VERSION ""

NS_ :

BS_:

BU_: ETH

BO_ 1359 SCCM_alertMatrix: 8 Vector__XXX
 SG_ SCCM_matrixIndex M : 0|4@1+ (1,0) [0|0] "" Vector__XXX
 SG_ SCCM_a001_CANBusOff m0 : 4|1@1+ (1,0) [0|0] "" Vector__XXX
 SG_ SCCM_a002_CANTOut m0 : 5|1@1+ (1,0) [0|0] "" Vector__XXX
 SG_ SCCM_a003_highBeamOpen m0 : 6|1@1+ (1,0) [0|0] "" Vector__XXX
 SG_ SCCM_a004_highBeamShortToGND m0 : 7|1@1+ (1,0) [0|0] "" Vector__XXX
 SG_ SCCM_a005_tipWipeOpen m0 : 8|1@1+ (1,0) [0|0] "" Vector__XXX
 SG_ SCCM_a006_tipWipeShortToGND m0 : 9|1@1+ (1,0) [0|0] "" Vector__XXX
 SG_ SCCM_a007_turnIndComInfo m0 : 10|1@1+ (1,0) [0|0] "" Vector__XXX
 SG_ SCCM_a008_turnIndInvalidTrans m0 : 11|1@1+ (1,0) [0|0] "" Vector__XXX
 SG_ SCCM_a009_turnIndOpen m0 : 12|1@1+ (1,0) [0|0] "" Vector__XXX
 SG_ SCCM_a010_turnIndShortToGnd m0 : 13|1@1+ (1,0) [0|0] "" Vector__XXX
 SG_ SCCM_a011_turnIndHWErr m0 : 14|1@1+ (1,0) [0|0] "" Vector__XXX
 SG_ SCCM_a012_turnGenErr m0 : 15|1@1+ (1,0) [0|0] "" Vector__XXX
 SG_ SCCM_a013_voltageHigh m0 : 16|1@1+ (1,0) [0|0] "" Vector__XXX
 SG_ SCCM_a014_voltageLow m0 : 17|1@1+ (1,0) [0|0] "" Vector__XXX
 SG_ SCCM_a015_softwareError m0 : 18|1@1+ (1,0) [0|0] "" Vector__XXX
 SG_ SCCM_a016_hardwareError m0 : 19|1@1+ (1,0) [0|0] "" Vector__XXX
 SG_ SCCM_a017_memoryError m0 : 20|1@1+ (1,0) [0|0] "" Vector__XXX
 SG_ SCCM_a018_angleSpeedOutOfRange m0 : 21|1@1+ (1,0) [0|0] "" Vector__XXX
 SG_ SCCM_a019_angleOutOfRange m0 : 22|1@1+ (1,0) [0|0] "" Vector__XXX
 SG_ SCCM_a020_angleInternalError m0 : 23|1@1+ (1,0) [0|0] "" Vector__XXX
 SG_ SCCM_a021_gearStalkSignalInvalid m0 : 24|1@1+ (1,0) [0|0] "" Vector__XXX
 SG_ SCCM_a022_gearStalkOpenCircuit m0 : 25|1@1+ (1,0) [0|0] "" Vector__XXX
 SG_ SCCM_a023_gearStalkShortCircuit m0 : 26|1@1+ (1,0) [0|0] "" Vector__XXX
 SG_ SCCM_a024_gearStalkGenErr m0 : 27|1@1+ (1,0) [0|0] "" Vector__XXX
 SG_ SCCM_a025_runTimeError m0 : 28|1@1+ (1,0) [0|0] "" Vector__XXX
 SG_ SCCM_a026_parkButtonInvalidSignal m0 : 29|1@1+ (1,0) [0|0] "" Vector__XXX
 SG_ SCCM_a027_parkButtonOpenCircuit m0 : 30|1@1+ (1,0) [0|0] "" Vector__XXX
 SG_ SCCM_a028_parkButtonShortToGround m0 : 31|1@1+ (1,0) [0|0] "" Vector__XXX
 SG_ SCCM_a029_parkButtonMalfunction m0 : 32|1@1+ (1,0) [0|0] "" Vector__XXX

BO_ 1360 VCRIGHT_alertLog: 8 Vector__XXX
 SG_ VCRIGHT_alertID M : 0|10@1+ (1,0) [0|0] "" Vector__XXX
 SG_ VCRIGHT_alertState : 15|1@1+ (1,0) [0|0] "" Vector__XXX
 SG_ VCRIGHT_a000_alertDataW0 m0 : 16|16@1+ (1,0) [0|0] "" Vector__XXX
 SG_ VCRIGHT_a001_InternalWatchdog m1 : 16|1@1+ (1,0) [0|0] "" Vector__XXX
 SG_ VCRIGHT_a002_CPUUndervoltage m2 : 16|1@1+ (1,0) [0|0] "" Vector__XXX
 SG_ VCRIGHT_a003_AssertID m3 : 16|16@1+ (1,0) [0|0] "" Vector__XXX
 SG_ VCRIGHT_a005_busID0 m5 : 16|4@1+ (1,0) [0|0] "" Vector__XXX
 SG_ VCRIGHT_a006_busID m6 : 16|4@1+ (1,0) [0|0] "" Vector__XXX
 SG_ VCRIGHT_a010_UnderVoltageDetected m10 : 16|1@1+ (1,0) [0|0] "" Vector__XXX
 SG_ VCRIGHT_a012_ClockError m12 : 16|1@1+ (1,0) [0|0] "" Vector__XXX
 SG_ VCRIGHT_a013_LogQueueFull m13 : 16|1@1+ (1,0) [0|0] "" Vector__XXX
 SG_ VCRIGHT_a015_NVMMMemOverflow m15 : 16|1@1+ (1,0) [0|0] "" Vector__XXX
 SG_ VCRIGHT_a016_NVMMRecordID m16 : 16|16@1+ (1,0) [0|0] "" Vector__XXX
 SG_ VCRIGHT_a017_NVMMLifetimeEraseCycles m17 : 16|32@1+ (1,0) [0|0] "" Vector__XXX
 SG_ VCRIGHT_a021_Task1msLate m21 : 16|1@1+ (1,0) [0|0] "" Vector__XXX
 SG_ VCRIGHT_a022_TaskInitErrorCount m22 : 16|8@1+ (1,0) [0|0] "" Vector__XXX
 SG_ VCRIGHT_a030_logId m30 : 16|4@1+ (1,0) [0|0] "" Vector__XXX
 SG_ VCRIGHT_a031_uds_bytes_0 m31 : 16|8@1+ (1,0) [0|0] "" Vector__XXX
 SG_ VCRIGHT_a041_CPULoadTotal m41 : 16|8@1+ (1,0) [0|0] "" Vector__XXX
 SG_ VCRIGHT_a042_Usage1msTask m42 : 16|8@1+ (1,0) [0|0] "" Vector__XXX
 SG_ VCRIGHT_a043_CallTrace0 m43 : 16|24@1+ (1,0) [0|0] "" Vector__XXX
 SG_ VCRIGHT_a044_CallTrace0 m44 : 16|24@1+ (1,0) [0|0] "" Vector__XXX
 SG_ VCRIGHT_a045_CallTrace0 m45 : 16|24@1+ (1,0) [0|0] "" Vector__XXX
 SG_ VCRIGHT_a046_CallTrace0 m46 : 16|24@1+ (1,0) [0|0] "" Vector__XXX
 SG_ VCRIGHT_a057_VEH_cpControl m57 : 16|1@1+ (1,0) [0|0] "" Vector__XXX
 SG_ VCRIGHT_a058_voltageDrop m58 : 16|12@1+ (0.005443676098,0) [0|0] "" Vector__XXX
 SG_ VCRIGHT_a059_voltageDrop m59 : 16|12@1+ (0.005443676098,0) [0|0] "" Vector__XXX
 SG_ VCRIGHT_a060_lockoutDisabled m60 : 16|1@1+ (1,0) [0|0] "" Vector__XXX
 SG_ VCRIGHT_a063_switchChannel m63 : 16|8@1+ (1,0) [0|0] "" Vector__XXX
 SG_ VCRIGHT_a064_busBitField m64 : 16|8@1+ (1,0) [0|0] "" Vector__XXX
 SG_ VCRIGHT_a065_bank m65 : 16|2@1+ (1,0) [0|0] "" Vector__XXX
 SG_ VCRIGHT_a066_bank m66 : 16|2@1+ (1,0) [0|0] "" Vector__XXX
 SG_ VCRIGHT_a082_RIPC_epbPrivateState m82 : 16|1@1+ (1,0) [0|0] "" Vector__XXX
 SG_ VCRIGHT_a083_LIPC_epbPrivateState m83 : 16|1@1+ (1,0) [0|0] "" Vector__XXX
 SG_ VCRIGHT_a084_CH_StatusC m84 : 16|1@1+ (1,0) [0|0] "" Vector__XXX
 SG_ VCRIGHT_a085_PARTY_buttonStatus m85 : 16|1@1+ (1,0) [0|0] "" Vector__XXX
 SG_ VCRIGHT_a086_VEH_LVBMS_statusHigh m86 : 16|1@1+ (1,0) [0|0] "" Vector__XXX
 SG_ VCRIGHT_a087_VEH_temperature m87 : 16|1@1+ (1,0) [0|0] "" Vector__XXX
 SG_ VCRIGHT_a088_VEH_temperature m88 : 16|1@1+ (1,0) [0|0] "" Vector__XXX
 SG_ VCRIGHT_a089_PARTY_party1 m89 : 16|1@1+ (1,0) [0|0] "" Vector__XXX
 SG_ VCRIGHT_a090_VEH_chNm m90 : 16|1@1+ (1,0) [0|0] "" Vector__XXX
 SG_ VCRIGHT_a091_VEH_faultsAndExtras m91 : 16|1@1+ (1,0) [0|0] "" Vector__XXX
 SG_ VCRIGHT_a092_VEH_restraintStatus m92 : 16|1@1+ (1,0) [0|0] "" Vector__XXX
 SG_ VCRIGHT_a093_VEH_restraintStatus m93 : 16|1@1+ (1,0) [0|0] "" Vector__XXX
 SG_ VCRIGHT_a094_VEH_sysStatus m94 : 16|1@1+ (1,0) [0|0] "" Vector__XXX
 SG_ VCRIGHT_a095_PT_ptNm m95 : 16|1@1+ (1,0) [0|0] "" Vector__XXX
 SG_ VCRIGHT_a096_VEH_status m96 : 16|1@1+ (1,0) [0|0] "" Vector__XXX
 SG_ VCRIGHT_a097_VEH_HVStatus m97 : 16|1@1+ (1,0) [0|0] "" Vector__XXX
 SG_ VCRIGHT_a098_CH_torque m98 : 16|1@1+ (1,0) [0|0] "" Vector__XXX
 SG_ VCRIGHT_a099_VEH_oocStatus m99 : 16|1@1+ (1,0) [0|0] "" Vector__XXX
 SG_ VCRIGHT_a100_VEH m100 : 16|1@1+ (1,0) [0|0] "" Vector__XXX
 SG_ VCRIGHT_a101_VEH_state m101 : 16|1@1+ (1,0) [0|0] "" Vector__XXX
 SG_ VCRIGHT_a102_VEH_faultsAndExtras m102 : 16|1@1+ (1,0) [0|0] "" Vector__XXX
 SG_ VCRIGHT_a103_VEH_hvsNm m103 : 16|1@1+ (1,0) [0|0] "" Vector__XXX
 SG_ VCRIGHT_a104_PARTY_redundantBrakingControl m104 : 16|1@1+ (1,0) [0|0] "" Vector__XXX
 SG_ VCRIGHT_a105_VEH_states m105 : 16|1@1+ (1,0) [0|0] "" Vector__XXX
 SG_ VCRIGHT_a106_VEH_dcdcStatus m106 : 16|1@1+ (1,0) [0|0] "" Vector__XXX
 SG_ VCRIGHT_a107_VEH_hvsNm m107 : 16|1@1+ (1,0) [0|0] "" Vector__XXX
 SG_ VCRIGHT_a108_VEH_hvStatus m108 : 16|1@1+ (1,0) [0|0] "" Vector__XXX
 SG_ VCRIGHT_a109_PARTY_status m109 : 16|1@1+ (1,0) [0|0] "" Vector__XXX
 SG_ VCRIGHT_a110_VEH_carState m110 : 16|1@1+ (1,0) [0|0] "" Vector__XXX
 SG_ VCRIGHT_a111_VEH_internalStatus m111 : 16|1@1+ (1,0) [0|0] "" Vector__XXX
 SG_ VCRIGHT_a112_VEH_internalStatus m112 : 16|1@1+ (1,0) [0|0] "" Vector__XXX
 SG_ VCRIGHT_a113_VEH_ethNm m113 : 16|1@1+ (1,0) [0|0] "" Vector__XXX
 SG_ VCRIGHT_a114_PARTY_status m114 : 16|1@1+ (1,0) [0|0] "" Vector__XXX
 SG_ VCRIGHT_a115_VEH_vehNm m115 : 16|1@1+ (1,0) [0|0] "" Vector__XXX
 SG_ VCRIGHT_a116_PARTY_epbmStatus m116 : 16|1@1+ (1,0) [0|0] "" Vector__XXX
 SG_ VCRIGHT_a117_BDY_epbmStatus m117 : 16|1@1+ (1,0) [0|0] "" Vector__XXX
 SG_ VCRIGHT_a118_VEH_vehNm m118 : 16|1@1+ (1,0) [0|0] "" Vector__XXX
 SG_ VCRIGHT_a119_VEH_steerAngle m119 : 16|1@1+ (1,0) [0|0] "" Vector__XXX
 SG_ VCRIGHT_a120_PARTY_chassisCntl m120 : 16|1@1+ (1,0) [0|0] "" Vector__XXX
 SG_ VCRIGHT_a122_VEH_status m122 : 16|1@1+ (1,0) [0|0] "" Vector__XXX
 SG_ VCRIGHT_a126_timeSinceInitMs m126 : 16|16@1+ (10,0) [0|0] "" Vector__XXX
 SG_ VCRIGHT_a127_timeSinceInitMs m127 : 16|16@1+ (10,0) [0|0] "" Vector__XXX
 SG_ VCRIGHT_a128_timeSinceInitMs m128 : 16|16@1+ (10,0) [0|0] "" Vector__XXX
 SG_ VCRIGHT_a136_hvacIntakeStall m136 : 16|1@1+ (1,0) [0|0] "" Vector__XXX
 SG_ VCRIGHT_a137_hvacLHBleedStall m137 : 16|1@1+ (1,0) [0|0] "" Vector__XXX
 SG_ VCRIGHT_a138_hvacRHBleedStall m138 : 16|1@1+ (1,0) [0|0] "" Vector__XXX
 SG_ VCRIGHT_a139_hvacLHVaneStall m139 : 16|1@1+ (1,0) [0|0] "" Vector__XXX
 SG_ VCRIGHT_a140_hvacRHVaneStall m140 : 16|1@1+ (1,0) [0|0] "" Vector__XXX
 SG_ VCRIGHT_a141_hvacUpperModeStall m141 : 16|1@1+ (1,0) [0|0] "" Vector__XXX
 SG_ VCRIGHT_a142_hvacLowerModeStall m142 : 16|1@1+ (1,0) [0|0] "" Vector__XXX
 SG_ VCRIGHT_a144_snsShortCircuit m144 : 16|1@1+ (1,0) [0|0] "" Vector__XXX
 SG_ VCRIGHT_a145_snsShortCircuit m145 : 16|1@1+ (1,0) [0|0] "" Vector__XXX
 SG_ VCRIGHT_a146_snsShortCircuit m146 : 16|1@1+ (1,0) [0|0] "" Vector__XXX
 SG_ VCRIGHT_a147_snsShortCircuit m147 : 16|1@1+ (1,0) [0|0] "" Vector__XXX
 SG_ VCRIGHT_a148_snsShortCircuit m148 : 16|1@1+ (1,0) [0|0] "" Vector__XXX
 SG_ VCRIGHT_a149_snsShortCircuit m149 : 16|1@1+ (1,0) [0|0] "" Vector__XXX
 SG_ VCRIGHT_a150_windowPosition m150 : 16|9@1- (1.4313725490196079,197.52941176470588) [0|0] "" Vector__XXX
 SG_ VCRIGHT_a151_windowPosition m151 : 16|9@1- (1.4313725490196079,197.52941176470588) [0|0] "" Vector__XXX
 SG_ VCRIGHT_a152_zeroed m152 : 16|1@1+ (1,0) [0|0] "" Vector__XXX
 SG_ VCRIGHT_a153_zeroed m153 : 16|1@1+ (1,0) [0|0] "" Vector__XXX
 SG_ VCRIGHT_a154_windowThermalMode m154 : 16|2@1+ (1,0) [0|0] "" Vector__XXX
 SG_ VCRIGHT_a155_windowThermalMode m155 : 16|2@1+ (1,0) [0|0] "" Vector__XXX
 SG_ VCRIGHT_a156_windowThermalMode m156 : 16|2@1+ (1,0) [0|0] "" Vector__XXX
 SG_ VCRIGHT_a157_windowThermalMode m157 : 16|2@1+ (1,0) [0|0] "" Vector__XXX
 SG_ VCRIGHT_a164_testPassed m164 : 16|1@1+ (1,0) [0|0] "" Vector__XXX
 SG_ VCRIGHT_a165_testPassed m165 : 16|1@1+ (1,0) [0|0] "" Vector__XXX
 SG_ VCRIGHT_a166_windowFront m166 : 16|1@1+ (1,0) [0|0] "" Vector__XXX
 SG_ VCRIGHT_a167_windowPosition m167 : 16|8@1+ (10,0) [0|0] "" Vector__XXX
 SG_ VCRIGHT_a168_windowPosition m168 : 16|8@1+ (10,0) [0|0] "" Vector__XXX
 SG_ VCRIGHT_a169_currentPeakCurrent m169 : 16|6@1+ (0.1,0) [0|0] "" Vector__XXX
 SG_ VCRIGHT_a170_currentPeakCurrent m170 : 16|6@1+ (0.1,0) [0|0] "" Vector__XXX
 SG_ VCRIGHT_a173_btnSwPackDownLF m173 : 16|1@1+ (1,0) [0|0] "" Vector__XXX
 SG_ VCRIGHT_a175_positionAtPinch m175 : 16|11@1- (0.25,230) [0|0] "" Vector__XXX
 SG_ VCRIGHT_a176_positionAtPinch m176 : 16|11@1- (0.25,230) [0|0] "" Vector__XXX
 SG_ VCRIGHT_a180_intButtonPressed m180 : 16|1@1+ (1,0) [0|0] "" Vector__XXX
 SG_ VCRIGHT_a181_intButtonPressed m181 : 16|1@1+ (1,0) [0|0] "" Vector__XXX
 SG_ VCRIGHT_a183_testPassed m183 : 16|1@1+ (1,0) [0|0] "" Vector__XXX
 SG_ VCRIGHT_a184_voltage m184 : 16|7@1+ (0.15,0) [0|0] "" Vector__XXX
 SG_ VCRIGHT_a185_summonFaultReason m185 : 16|5@1+ (1,0) [0|0] "" Vector__XXX
 SG_ VCRIGHT_a186_voltage m186 : 16|7@1+ (0.15,0) [0|0] "" Vector__XXX
 SG_ VCRIGHT_a187_voltage m187 : 16|7@1+ (0.15,0) [0|0] "" Vector__XXX
 SG_ VCRIGHT_a188_voltage m188 : 16|7@1+ (0.15,0) [0|0] "" Vector__XXX
 SG_ VCRIGHT_a189_voltage m189 : 16|7@1+ (0.15,0) [0|0] "" Vector__XXX
 SG_ VCRIGHT_a190_eFuseTripCount m190 : 16|8@1+ (1,0) [0|0] "" Vector__XXX
 SG_ VCRIGHT_a193_amplifierCurrent m193 : 16|10@1+ (0.1,0) [0|0] "" Vector__XXX
 SG_ VCRIGHT_a194_cntctrPwrCurrent m194 : 16|10@1+ (0.1,0) [0|0] "" Vector__XXX
 SG_ VCRIGHT_a195_hvcCurrent m195 : 16|10@1+ (0.1,0) [0|0] "" Vector__XXX
 SG_ VCRIGHT_a196_outputState m196 : 16|1@1+ (1,0) [0|0] "" Vector__XXX
 SG_ VCRIGHT_a197_outputState m197 : 16|1@1+ (1,0) [0|0] "" Vector__XXX
 SG_ VCRIGHT_a198_outputState m198 : 16|1@1+ (1,0) [0|0] "" Vector__XXX
 SG_ VCRIGHT_a199_outputState m199 : 16|1@1+ (1,0) [0|0] "" Vector__XXX
 SG_ VCRIGHT_a200_voltage m200 : 16|7@1+ (0.15,0) [0|0] "" Vector__XXX
 SG_ VCRIGHT_a201_voltage m201 : 16|7@1+ (0.15,0) [0|0] "" Vector__XXX
 SG_ VCRIGHT_a202_unknownAllowed m202 : 16|1@1+ (1,0) [0|0] "" Vector__XXX
 SG_ VCRIGHT_a203_unknownAllowed m203 : 16|1@1+ (1,0) [0|0] "" Vector__XXX
 SG_ VCRIGHT_a204_unknownAllowed m204 : 16|1@1+ (1,0) [0|0] "" Vector__XXX
 SG_ VCRIGHT_a205_unknownAllowed m205 : 16|1@1+ (1,0) [0|0] "" Vector__XXX
 SG_ VCRIGHT_a206_unknownAllowed m206 : 16|1@1+ (1,0) [0|0] "" Vector__XXX
 SG_ VCRIGHT_a207_unknownAllowed m207 : 16|1@1+ (1,0) [0|0] "" Vector__XXX
 SG_ VCRIGHT_a208_unknownAllowed m208 : 16|1@1+ (1,0) [0|0] "" Vector__XXX
 SG_ VCRIGHT_a209_unknownAllowed m209 : 16|1@1+ (1,0) [0|0] "" Vector__XXX
 SG_ VCRIGHT_a210_unknownAllowed m210 : 16|1@1+ (1,0) [0|0] "" Vector__XXX
 SG_ VCRIGHT_a211_unknownAllowed m211 : 16|1@1+ (1,0) [0|0] "" Vector__XXX
 SG_ VCRIGHT_a212_unknownAllowed m212 : 16|1@1+ (1,0) [0|0] "" Vector__XXX
 SG_ VCRIGHT_a213_unknownAllowed m213 : 16|1@1+ (1,0) [0|0] "" Vector__XXX
 SG_ VCRIGHT_a214_unknownAllowed m214 : 16|1@1+ (1,0) [0|0] "" Vector__XXX
 SG_ VCRIGHT_a215_desyncCount m215 : 16|8@1+ (1,0) [0|0] "" Vector__XXX
 SG_ VCRIGHT_a216_noData m216 : 16|1@1+ (1,0) [0|0] "" Vector__XXX
 SG_ VCRIGHT_a217_byte4 m217 : 16|8@1+ (1,0) [0|0] "" Vector__XXX
 SG_ VCRIGHT_a218_motorChannels m218 : 16|16@1+ (1,0) [0|0] "" Vector__XXX
 SG_ VCRIGHT_a219_motorChannels m219 : 16|16@1+ (1,0) [0|0] "" Vector__XXX
 SG_ VCRIGHT_a224_seatMotorCalibrated m224 : 16|1@1+ (1,0) [0|0] "" Vector__XXX
 SG_ VCRIGHT_a225_seatMotorCalibrated m225 : 16|1@1+ (1,0) [0|0] "" Vector__XXX
 SG_ VCRIGHT_a226_seatMotorCalibrated m226 : 16|1@1+ (1,0) [0|0] "" Vector__XXX
 SG_ VCRIGHT_a227_seatMotorCalibrated m227 : 16|1@1+ (1,0) [0|0] "" Vector__XXX
 SG_ VCRIGHT_a228_seatMotorCalibrated m228 : 16|1@1+ (1,0) [0|0] "" Vector__XXX
 SG_ VCRIGHT_a229_seatMotorCalibrated m229 : 16|1@1+ (1,0) [0|0] "" Vector__XXX
 SG_ VCRIGHT_a230_seatMotorCalibrated m230 : 16|1@1+ (1,0) [0|0] "" Vector__XXX
 SG_ VCRIGHT_a231_seatMotorCalibrated m231 : 16|1@1+ (1,0) [0|0] "" Vector__XXX
 SG_ VCRIGHT_a232_seatMotorCurrent m232 : 16|12@1- (0.01,0) [0|0] "" Vector__XXX
 SG_ VCRIGHT_a233_seatMotorCurrent m233 : 16|12@1- (0.01,0) [0|0] "" Vector__XXX
 SG_ VCRIGHT_a234_seatMotorCurrent m234 : 16|12@1- (0.01,0) [0|0] "" Vector__XXX
 SG_ VCRIGHT_a235_seatMotorCurrent m235 : 16|12@1- (0.01,0) [0|0] "" Vector__XXX
 SG_ VCRIGHT_a236_lumbarAPressureHpa m236 : 16|16@1+ (1,0) [0|0] "" Vector__XXX
 SG_ VCRIGHT_a237_lumbarAPressureHpa m237 : 16|16@1+ (1,0) [0|0] "" Vector__XXX
 SG_ VCRIGHT_a238_lumbarAPressureHpa m238 : 16|16@1+ (1,0) [0|0] "" Vector__XXX
 SG_ VCRIGHT_a239_seatHeatCurrent m239 : 16|12@1+ (0.01,0) [0|0] "" Vector__XXX
 SG_ VCRIGHT_a240_seatHeatCurrent m240 : 16|12@1+ (0.01,0) [0|0] "" Vector__XXX
 SG_ VCRIGHT_a241_seatHeatCurrent m241 : 16|12@1+ (0.01,0) [0|0] "" Vector__XXX
 SG_ VCRIGHT_a242_seatHeatCurrent m242 : 16|12@1+ (0.01,0) [0|0] "" Vector__XXX
 SG_ VCRIGHT_a243_seatHeatCurrent m243 : 16|12@1+ (0.01,0) [0|0] "" Vector__XXX
 SG_ VCRIGHT_a244_seatHeatCurrent m244 : 16|12@1+ (0.01,0) [0|0] "" Vector__XXX
 SG_ VCRIGHT_a245_seatHeatCurrent m245 : 16|12@1+ (0.01,0) [0|0] "" Vector__XXX
 SG_ VCRIGHT_a246_seatHeatCurrent m246 : 16|12@1+ (0.01,0) [0|0] "" Vector__XXX
 SG_ VCRIGHT_a247_seatHeatCurrent m247 : 16|12@1+ (0.01,0) [0|0] "" Vector__XXX
 SG_ VCRIGHT_a248_seatHeatCurrent m248 : 16|12@1+ (0.01,0) [0|0] "" Vector__XXX
 SG_ VCRIGHT_a249_seatHeatCurrent m249 : 16|12@1+ (0.01,0) [0|0] "" Vector__XXX
 SG_ VCRIGHT_a250_seatHeatCurrent m250 : 16|12@1+ (0.01,0) [0|0] "" Vector__XXX
 SG_ VCRIGHT_a251_seatMotorCurrent m251 : 16|12@1- (0.01,0) [0|0] "" Vector__XXX
 SG_ VCRIGHT_a252_seatMotorCurrent m252 : 16|12@1- (0.01,0) [0|0] "" Vector__XXX
 SG_ VCRIGHT_a253_seatMotorCurrent m253 : 16|12@1- (0.01,0) [0|0] "" Vector__XXX
 SG_ VCRIGHT_a254_seatMotorCurrent m254 : 16|12@1- (0.01,0) [0|0] "" Vector__XXX
 SG_ VCRIGHT_a255_leftIGBTTemp m255 : 16|8@1- (1,80) [0|0] "" Vector__XXX
 SG_ VCRIGHT_a256_leftCurrent m256 : 16|8@1+ (0.2,0) [0|0] "" Vector__XXX
 SG_ VCRIGHT_a257_MIAStatus m257 : 16|1@1+ (1,0) [0|0] "" Vector__XXX
 SG_ VCRIGHT_a258_bootIdFreq m258 : 16|8@1+ (0.02,0) [0|0] "" Vector__XXX
 SG_ VCRIGHT_a259_disarmDelay m259 : 16|7@1+ (10,0) [0|0] "" Vector__XXX
 SG_ VCRIGHT_a260_disarmDelay m260 : 16|7@1+ (10,0) [0|0] "" Vector__XXX
 SG_ VCRIGHT_a262_LVLow m262 : 16|1@1+ (1,0) [0|0] "" Vector__XXX
 SG_ VCRIGHT_a263_seatMotorCurrent m263 : 16|12@1- (0.01,0) [0|0] "" Vector__XXX
 SG_ VCRIGHT_a264_seatMotorCurrent m264 : 16|12@1- (0.01,0) [0|0] "" Vector__XXX
 SG_ VCRIGHT_a265_seatMotorCurrent m265 : 16|12@1- (0.01,0) [0|0] "" Vector__XXX
 SG_ VCRIGHT_a266_seatMotorCurrent m266 : 16|12@1- (0.01,0) [0|0] "" Vector__XXX
 SG_ VCRIGHT_a267_seatMotorCurrent m267 : 16|12@1- (0.01,0) [0|0] "" Vector__XXX
 SG_ VCRIGHT_a268_seatMotorCurrent m268 : 16|12@1- (0.01,0) [0|0] "" Vector__XXX
 SG_ VCRIGHT_a269_seatMotorCurrent m269 : 16|12@1- (0.01,0) [0|0] "" Vector__XXX
 SG_ VCRIGHT_a270_seatMotorCurrent m270 : 16|12@1- (0.01,0) [0|0] "" Vector__XXX
 SG_ VCRIGHT_a271_humiditySensorSNA m271 : 16|1@1+ (1,0) [0|0] "" Vector__XXX
 SG_ VCRIGHT_a272_expectedState m272 : 16|2@1+ (1,0) [0|0] "" Vector__XXX
 SG_ VCRIGHT_a273_handlePWM m273 : 16|7@1+ (1,0) [0|0] "" Vector__XXX
 SG_ VCRIGHT_a274_handlePWM m274 : 16|7@1+ (1,0) [0|0] "" Vector__XXX
 SG_ VCRIGHT_a275_outputFaulted m275 : 16|1@1+ (1,0) [0|0] "" Vector__XXX
 SG_ VCRIGHT_a276_mirrorDebugType m276 : 16|3@1+ (1,0) [0|0] "" Vector__XXX
 SG_ VCRIGHT_a277_voltageInmV m277 : 16|16@1+ (1,0) [0|0] "" Vector__XXX
 SG_ VCRIGHT_a278_HVLow m278 : 16|1@1+ (1,0) [0|0] "" Vector__XXX
 SG_ VCRIGHT_a279_temperature m279 : 16|8@1+ (0.5,-40) [0|0] "" Vector__XXX
 SG_ VCRIGHT_a282_voltage m282 : 16|7@1+ (0.15,0) [0|0] "" Vector__XXX
 SG_ VCRIGHT_a283_voltage m283 : 16|7@1+ (0.15,0) [0|0] "" Vector__XXX
 SG_ VCRIGHT_a284_gloveboxMinCurrent m284 : 16|8@1+ (0.1,0) [0|0] "" Vector__XXX
 SG_ VCRIGHT_a285_gloveboxMinCurrent m285 : 16|8@1+ (0.1,0) [0|0] "" Vector__XXX
 SG_ VCRIGHT_a286_windowSpeed m286 : 16|8@1- (100,0) [0|0] "" Vector__XXX
 SG_ VCRIGHT_a287_windowSpeed m287 : 16|8@1- (100,0) [0|0] "" Vector__XXX
 SG_ VCRIGHT_a288_period m288 : 16|8@1+ (0.05,0) [0|0] "" Vector__XXX
 SG_ VCRIGHT_a289_period m289 : 16|8@1+ (0.05,0) [0|0] "" Vector__XXX
 SG_ VCRIGHT_a290_isNetworkSwitch m290 : 16|1@1+ (1,0) [0|0] "" Vector__XXX
 SG_ VCRIGHT_a291_buckleSensorVoltage m291 : 16|12@1+ (0.01,0) [0|0] "" Vector__XXX
 SG_ VCRIGHT_a292_buckleSensorVoltage m292 : 16|12@1- (0.01,0) [0|0] "" Vector__XXX
 SG_ VCRIGHT_a293_buckleSensorVoltage m293 : 16|12@1- (0.01,0) [0|0] "" Vector__XXX
 SG_ VCRIGHT_a294_isNetworkSwitch m294 : 16|1@1+ (1,0) [0|0] "" Vector__XXX
 SG_ VCRIGHT_a295_isNetworkSwitch m295 : 16|1@1+ (1,0) [0|0] "" Vector__XXX
 SG_ VCRIGHT_a296_isNetworkSwitch m296 : 16|1@1+ (1,0) [0|0] "" Vector__XXX
 SG_ VCRIGHT_a297_cabinTmp m297 : 16|12@1- (0.1,0) [0|0] "" Vector__XXX
 SG_ VCRIGHT_a298_buckleSensorVoltage m298 : 16|12@1- (0.01,0) [0|0] "" Vector__XXX
 SG_ VCRIGHT_a299_buckleSensorVoltage m299 : 16|12@1- (0.01,0) [0|0] "" Vector__XXX
 SG_ VCRIGHT_a303_eFuseTripCount m303 : 16|8@1+ (1,0) [0|0] "" Vector__XXX
 SG_ VCRIGHT_a304_handleADCmV m304 : 16|8@1+ (20,0) [0|0] "" Vector__XXX
 SG_ VCRIGHT_a305_handleADCmV m305 : 16|8@1+ (20,0) [0|0] "" Vector__XXX
 SG_ VCRIGHT_a306_disconnectedTime m306 : 16|10@1+ (1,0) [0|0] "" Vector__XXX
 SG_ VCRIGHT_a307_disconnectedTime m307 : 16|10@1+ (1,0) [0|0] "" Vector__XXX
 SG_ VCRIGHT_a310_mirrorFoldTime m310 : 16|9@1+ (10,0) [0|0] "" Vector__XXX
 SG_ VCRIGHT_a311_outputFaulted m311 : 16|1@1+ (1,0) [0|0] "" Vector__XXX
 SG_ VCRIGHT_a312_outputFaulted m312 : 16|1@1+ (1,0) [0|0] "" Vector__XXX
 SG_ VCRIGHT_a313_outputFaulted m313 : 16|1@1+ (1,0) [0|0] "" Vector__XXX
 SG_ VCRIGHT_a314_outputFaulted m314 : 16|1@1+ (1,0) [0|0] "" Vector__XXX
 SG_ VCRIGHT_a315_outputFaulted m315 : 16|1@1+ (1,0) [0|0] "" Vector__XXX
 SG_ VCRIGHT_a316_foldState m316 : 16|3@1+ (1,0) [0|0] "" Vector__XXX
 SG_ VCRIGHT_a318_outputFaulted m318 : 16|1@1+ (1,0) [0|0] "" Vector__XXX
 SG_ VCRIGHT_a319_outputFaulted m319 : 16|1@1+ (1,0) [0|0] "" Vector__XXX
 SG_ VCRIGHT_a321_deltaPrevZero m321 : 16|16@1- (1,0) [0|0] "" Vector__XXX
 SG_ VCRIGHT_a322_deltaPrevZero m322 : 16|16@1- (1,0) [0|0] "" Vector__XXX
 SG_ VCRIGHT_a323_calibrationLeft m323 : 16|12@1+ (0.002,0) [0|0] "" Vector__XXX
 SG_ VCRIGHT_a324_mirrorHeatCurrent m324 : 16|10@1+ (0.01,0) [0|0] "" Vector__XXX
 SG_ VCRIGHT_a330_voltage m330 : 16|7@1+ (0.15,0) [0|0] "" Vector__XXX
 SG_ VCRIGHT_a331_voltage m331 : 16|7@1+ (0.15,0) [0|0] "" Vector__XXX
 SG_ VCRIGHT_a343_rearDefrostCurrent m343 : 16|9@1+ (0.1,0) [0|0] "" Vector__XXX
 SG_ VCRIGHT_a344_rearDefrostCurrent m344 : 16|9@1+ (0.1,0) [0|0] "" Vector__XXX
 SG_ VCRIGHT_a345_PTCTHSGBPwrCurrent m345 : 16|10@1+ (0.1,0) [0|0] "" Vector__XXX
 SG_ VCRIGHT_a352_pointsAboveThreshold m352 : 16|10@1+ (1,0) [0|0] "" Vector__XXX
 SG_ VCRIGHT_a355_hvacLHBleedDither m355 : 16|1@1+ (1,0) [0|0] "" Vector__XXX
 SG_ VCRIGHT_a356_hvacRHBleedDither m356 : 16|1@1+ (1,0) [0|0] "" Vector__XXX
 SG_ VCRIGHT_a357_hvacLHVaneDither m357 : 16|1@1+ (1,0) [0|0] "" Vector__XXX
 SG_ VCRIGHT_a358_hvacRHVaneDither m358 : 16|1@1+ (1,0) [0|0] "" Vector__XXX
 SG_ VCRIGHT_a359_hvacUpperModeDither m359 : 16|1@1+ (1,0) [0|0] "" Vector__XXX
 SG_ VCRIGHT_a360_vehicleSpeed m360 : 16|8@1- (1,80) [0|0] "" Vector__XXX
 SG_ VCRIGHT_a361_accelVar m361 : 16|15@1+ (0.0001,0) [0|0] "" Vector__XXX
 SG_ VCRIGHT_a362_accelVar m362 : 16|20@1+ (1e-06,0) [0|0] "" Vector__XXX
 SG_ VCRIGHT_a363_hvacLowerModeDither m363 : 16|1@1+ (1,0) [0|0] "" Vector__XXX
 SG_ VCRIGHT_a364_hvacIntakeDither m364 : 16|1@1+ (1,0) [0|0] "" Vector__XXX
 SG_ VCRIGHT_a368_snsShortCircuit m368 : 16|1@1+ (1,0) [0|0] "" Vector__XXX
 SG_ VCRIGHT_a369_snsShortCircuit m369 : 16|1@1+ (1,0) [0|0] "" Vector__XXX
 SG_ VCRIGHT_a373_windowChannel m373 : 16|2@1+ (1,0) [0|0] "" Vector__XXX
 SG_ VCRIGHT_a375_windowFront m375 : 16|1@1+ (1,0) [0|0] "" Vector__XXX
 SG_ VCRIGHT_a376_2RowSeatTrackActuatorCurrent m376 : 16|12@1- (0.01,0) [0|0] "" Vector__XXX
 SG_ VCRIGHT_a377_snsShortCircuit m377 : 16|1@1+ (1,0) [0|0] "" Vector__XXX
 SG_ VCRIGHT_a378_snsShortCircuit m378 : 16|1@1+ (1,0) [0|0] "" Vector__XXX
 SG_ VCRIGHT_a379_snsShortCircuit m379 : 16|1@1+ (1,0) [0|0] "" Vector__XXX
 SG_ VCRIGHT_a380_outputFaulted m380 : 16|1@1+ (1,0) [0|0] "" Vector__XXX
 SG_ VCRIGHT_a381_outputFaulted m381 : 16|1@1+ (1,0) [0|0] "" Vector__XXX
 SG_ VCRIGHT_a382_outputFaulted m382 : 16|1@1+ (1,0) [0|0] "" Vector__XXX
 SG_ VCRIGHT_a426_seatMotorCalibrated m426 : 16|1@1+ (1,0) [0|0] "" Vector__XXX
 SG_ VCRIGHT_a427_seatMotorCalibrated m427 : 16|1@1+ (1,0) [0|0] "" Vector__XXX
 SG_ VCRIGHT_a428_seatMotorCalibrated m428 : 16|1@1+ (1,0) [0|0] "" Vector__XXX
 SG_ VCRIGHT_a429_seatMotorCalibrated m429 : 16|1@1+ (1,0) [0|0] "" Vector__XXX
 SG_ VCRIGHT_a444_retriesAvailable m444 : 16|8@1+ (1,0) [0|0] "" Vector__XXX
 SG_ VCRIGHT_a445_checksFailedCount m445 : 16|2@1+ (1,0) [0|0] "" Vector__XXX
 SG_ VCRIGHT_a446_caseTempHVACUnavailable m446 : 16|1@1+ (1,0) [0|0] "" Vector__XXX
 SG_ VCRIGHT_a448_manACOFFComfortCoolNudge m448 : 16|1@1+ (1,0) [0|0] "" Vector__XXX
 SG_ VCRIGHT_a450_datOverTemp m450 : 16|1@1+ (1,0) [0|0] "" Vector__XXX
 SG_ VCRIGHT_a454_failedRodRight m454 : 16|3@1+ (1,0) [0|0] "" Vector__XXX
 SG_ VCRIGHT_a482_channel m482 : 16|6@1+ (1,0) [0|0] "" Vector__XXX
 SG_ VCRIGHT_a491_faultType m491 : 16|1@1+ (1,0) [0|0] "" Vector__XXX
 SG_ VCRIGHT_a496_cabinTempInterior m496 : 16|8@1+ (0.5,-40) [0|0] "" Vector__XXX
 SG_ VCRIGHT_a499_localCdpState m499 : 16|2@1+ (1,0) [0|0] "" Vector__XXX
 SG_ VCRIGHT_a520_epbConfig m520 : 16|4@1+ (1,0) [0|0] "" Vector__XXX
 SG_ VCRIGHT_a525_GTW_twelveVBatteryType m525 : 16|3@1+ (1,0) [0|0] "" Vector__XXX
 SG_ VCRIGHT_a526_aboveAbsMaxTemp m526 : 16|1@1+ (1,0) [0|0] "" Vector__XXX
 SG_ VCRIGHT_a527_voltage m527 : 16|8@1+ (0.1,0) [0|0] "" Vector__XXX
 SG_ VCRIGHT_a533_solarScalingFactor m533 : 16|7@1+ (0.01,0) [0|0] "" Vector__XXX
 SG_ VCRIGHT_a537_usingNVRAMData m537 : 16|1@1+ (1,0) [0|0] "" Vector__XXX
 SG_ VCRIGHT_a538_ptcHeaterFault m538 : 16|1@1+ (1,0) [0|0] "" Vector__XXX
 SG_ VCRIGHT_a539_hvacSystemNotNominal m539 : 16|1@1+ (1,0) [0|0] "" Vector__XXX
 SG_ VCRIGHT_a540_LHVaneDebugDither m540 : 16|1@1+ (1,0) [0|0] "" Vector__XXX
 SG_ VCRIGHT_a542_VCLEFTMsgMIAOrSignalsSNA m542 : 16|1@1+ (1,0) [0|0] "" Vector__XXX
 SG_ VCRIGHT_a545_GTW_twelveVBatteryType m545 : 16|3@1+ (1,0) [0|0] "" Vector__XXX
 SG_ VCRIGHT_a546_mirrorFoldTypePresent m546 : 16|2@1+ (1,0) [0|0] "" Vector__XXX
 SG_ VCRIGHT_a550_ambientTemperature m550 : 16|16@1- (0.125,55) [0|0] "" Vector__XXX
 SG_ VCRIGHT_a551_restrictDoorReleaseSignalFront m551 : 16|1@1+ (1,0) [0|0] "" Vector__XXX
 SG_ VCRIGHT_a555_VEH_alertMatrix m555 : 16|1@1+ (1,0) [0|0] "" Vector__XXX
 SG_ VCRIGHT_a570_seatHeatCurrent m570 : 16|12@1+ (0.01,0) [0|0] "" Vector__XXX
 SG_ VCRIGHT_a571_seatHeatCurrent m571 : 16|12@1+ (0.01,0) [0|0] "" Vector__XXX
 SG_ VCRIGHT_a572_seatHeatCurrent m572 : 16|12@1+ (0.01,0) [0|0] "" Vector__XXX
 SG_ VCRIGHT_a573_seatHeatCurrent m573 : 16|12@1+ (0.01,0) [0|0] "" Vector__XXX
 SG_ VCRIGHT_a583_ambientTemp m583 : 16|8@1+ (0.5,-40) [0|0] "" Vector__XXX
 SG_ VCRIGHT_a584_ambientTemp m584 : 16|8@1+ (0.5,-40) [0|0] "" Vector__XXX
 SG_ VCRIGHT_a585_ambientTemp m585 : 16|8@1+ (0.5,-40) [0|0] "" Vector__XXX
 SG_ VCRIGHT_a586_ambientTemp m586 : 16|8@1+ (0.5,-40) [0|0] "" Vector__XXX
 SG_ VCRIGHT_a589_finalState m589 : 16|3@1+ (1,0) [0|0] "" Vector__XXX
 SG_ VCRIGHT_a598_hvacSystemNotNominal m598 : 16|1@1+ (1,0) [0|0] "" Vector__XXX
 SG_ VCRIGHT_a599_GTW_twelveVBatteryType m599 : 16|3@1+ (1,0) [0|0] "" Vector__XXX
 SG_ VCRIGHT_a617_VEH_VC_infoMessage m617 : 16|1@1+ (1,0) [0|0] "" Vector__XXX
 SG_ VCRIGHT_a002_PowerOnReset m2 : 17|1@1+ (1,0) [0|0] "" Vector__XXX
 SG_ VCRIGHT_a010_UnderVoltageTimeout m10 : 17|1@1+ (1,0) [0|0] "" Vector__XXX
 SG_ VCRIGHT_a012_FlashError m12 : 17|1@1+ (1,0) [0|0] "" Vector__XXX
 SG_ VCRIGHT_a013_ClearQueueFull m13 : 17|1@1+ (1,0) [0|0] "" Vector__XXX
 SG_ VCRIGHT_a015_NVMMFilesystemError m15 : 17|1@1+ (1,0) [0|0] "" Vector__XXX
 SG_ VCRIGHT_a021_Task1msStarved m21 : 17|1@1+ (1,0) [0|0] "" Vector__XXX
 SG_ VCRIGHT_a060_resetUnlocked m60 : 17|1@1+ (1,0) [0|0] "" Vector__XXX
 SG_ VCRIGHT_a082_RIPC_remoteHSD m82 : 17|1@1+ (1,0) [0|0] "" Vector__XXX
 SG_ VCRIGHT_a083_LIPC_remoteHSD m83 : 17|1@1+ (1,0) [0|0] "" Vector__XXX
 SG_ VCRIGHT_a086_VEH_LVBMS_statusLow m86 : 17|1@1+ (1,0) [0|0] "" Vector__XXX
 SG_ VCRIGHT_a087_VEH_thermalControl m87 : 17|1@1+ (1,0) [0|0] "" Vector__XXX
 SG_ VCRIGHT_a088_VEH_thermalControl m88 : 17|1@1+ (1,0) [0|0] "" Vector__XXX
 SG_ VCRIGHT_a089_PARTY_status m89 : 17|1@1+ (1,0) [0|0] "" Vector__XXX
 SG_ VCRIGHT_a090_VEH_state m90 : 17|1@1+ (1,0) [0|0] "" Vector__XXX
 SG_ VCRIGHT_a091_VEH_info m91 : 17|1@1+ (1,0) [0|0] "" Vector__XXX
 SG_ VCRIGHT_a092_VEH_switchStatus m92 : 17|1@1+ (1,0) [0|0] "" Vector__XXX
 SG_ VCRIGHT_a093_VEH_switchStatus m93 : 17|1@1+ (1,0) [0|0] "" Vector__XXX
 SG_ VCRIGHT_a094_PARTY_sysStatus m94 : 17|1@1+ (1,0) [0|0] "" Vector__XXX
 SG_ VCRIGHT_a095_PT_status m95 : 17|1@1+ (1,0) [0|0] "" Vector__XXX
 SG_ VCRIGHT_a096_CH_status m96 : 17|1@1+ (1,0) [0|0] "" Vector__XXX
 SG_ VCRIGHT_a097_VEH_state m97 : 17|1@1+ (1,0) [0|0] "" Vector__XXX
 SG_ VCRIGHT_a098_VEH_hvStatus m98 : 17|1@1+ (1,0) [0|0] "" Vector__XXX
 SG_ VCRIGHT_a100_PARTY m100 : 17|1@1+ (1,0) [0|0] "" Vector__XXX
 SG_ VCRIGHT_a101_PARTY_locState m101 : 17|1@1+ (1,0) [0|0] "" Vector__XXX
 SG_ VCRIGHT_a102_VEH_feedbackStatus m102 : 17|1@1+ (1,0) [0|0] "" Vector__XXX
 SG_ VCRIGHT_a103_VEH_vehNm m103 : 17|1@1+ (1,0) [0|0] "" Vector__XXX
 SG_ VCRIGHT_a104_BDY_redundantBrakingControl m104 : 17|1@1+ (1,0) [0|0] "" Vector__XXX
 SG_ VCRIGHT_a105_VEH_chNm m105 : 17|1@1+ (1,0) [0|0] "" Vector__XXX
 SG_ VCRIGHT_a106_VEH_thermalControl m106 : 17|1@1+ (1,0) [0|0] "" Vector__XXX
 SG_ VCRIGHT_a107_VEH_vehNm m107 : 17|1@1+ (1,0) [0|0] "" Vector__XXX
 SG_ VCRIGHT_a108_VEH_temperature m108 : 17|1@1+ (1,0) [0|0] "" Vector__XXX
 SG_ VCRIGHT_a109_PARTY_inertial2 m109 : 17|1@1+ (1,0) [0|0] "" Vector__XXX
 SG_ VCRIGHT_a110_VEH_carConfig m110 : 17|1@1+ (1,0) [0|0] "" Vector__XXX
 SG_ VCRIGHT_a111_VEH_status m111 : 17|1@1+ (1,0) [0|0] "" Vector__XXX
 SG_ VCRIGHT_a112_VEH_status m112 : 17|1@1+ (1,0) [0|0] "" Vector__XXX
 SG_ VCRIGHT_a113_VEH_hvacRequest m113 : 17|1@1+ (1,0) [0|0] "" Vector__XXX
 SG_ VCRIGHT_a114_PARTY_wheelSpeeds m114 : 17|1@1+ (1,0) [0|0] "" Vector__XXX
 SG_ VCRIGHT_a115_VEH_authentication m115 : 17|1@1+ (1,0) [0|0] "" Vector__XXX
 SG_ VCRIGHT_a116_VEH_vehNm m116 : 17|1@1+ (1,0) [0|0] "" Vector__XXX
 SG_ VCRIGHT_a117_BDY_restraintStatus m117 : 17|1@1+ (1,0) [0|0] "" Vector__XXX
 SG_ VCRIGHT_a118_VEH_lighting m118 : 17|1@1+ (1,0) [0|0] "" Vector__XXX
 SG_ VCRIGHT_a119_VEH_leftStalk m119 : 17|1@1+ (1,0) [0|0] "" Vector__XXX
 SG_ VCRIGHT_a120_VEH_systemStatus m120 : 17|1@1+ (1,0) [0|0] "" Vector__XXX
 SG_ VCRIGHT_a122_VEH_nonLocalizedOccupancy m122 : 17|1@1+ (1,0) [0|0] "" Vector__XXX
 SG_ VCRIGHT_a144_snsDisconnect m144 : 17|1@1+ (1,0) [0|0] "" Vector__XXX
 SG_ VCRIGHT_a145_snsDisconnect m145 : 17|1@1+ (1,0) [0|0] "" Vector__XXX
 SG_ VCRIGHT_a146_snsDisconnect m146 : 17|1@1+ (1,0) [0|0] "" Vector__XXX
 SG_ VCRIGHT_a147_snsDisconnect m147 : 17|1@1+ (1,0) [0|0] "" Vector__XXX
 SG_ VCRIGHT_a148_snsDisconnect m148 : 17|1@1+ (1,0) [0|0] "" Vector__XXX
 SG_ VCRIGHT_a149_snsDisconnect m149 : 17|1@1+ (1,0) [0|0] "" Vector__XXX
 SG_ VCRIGHT_a152_endStopTrusted m152 : 17|1@1+ (1,0) [0|0] "" Vector__XXX
 SG_ VCRIGHT_a153_endStopTrusted m153 : 17|1@1+ (1,0) [0|0] "" Vector__XXX
 SG_ VCRIGHT_a164_windowFront m164 : 17|1@1+ (1,0) [0|0] "" Vector__XXX
 SG_ VCRIGHT_a165_windowFront m165 : 17|1@1+ (1,0) [0|0] "" Vector__XXX
 SG_ VCRIGHT_a166_windowRear m166 : 17|1@1+ (1,0) [0|0] "" Vector__XXX
 SG_ VCRIGHT_a173_btnSwPackAutoDownLF m173 : 17|1@1+ (1,0) [0|0] "" Vector__XXX
 SG_ VCRIGHT_a183_doorFront m183 : 17|1@1+ (1,0) [0|0] "" Vector__XXX
 SG_ VCRIGHT_a196_NVRAMState m196 : 17|1@1+ (1,0) [0|0] "" Vector__XXX
 SG_ VCRIGHT_a197_NVRAMState m197 : 17|1@1+ (1,0) [0|0] "" Vector__XXX
 SG_ VCRIGHT_a198_NVRAMState m198 : 17|1@1+ (1,0) [0|0] "" Vector__XXX
 SG_ VCRIGHT_a199_NVRAMState m199 : 17|1@1+ (1,0) [0|0] "" Vector__XXX
 SG_ VCRIGHT_a202_openAllowed m202 : 17|1@1+ (1,0) [0|0] "" Vector__XXX
 SG_ VCRIGHT_a203_openAllowed m203 : 17|1@1+ (1,0) [0|0] "" Vector__XXX
 SG_ VCRIGHT_a204_openAllowed m204 : 17|1@1+ (1,0) [0|0] "" Vector__XXX
 SG_ VCRIGHT_a205_openAllowed m205 : 17|1@1+ (1,0) [0|0] "" Vector__XXX
 SG_ VCRIGHT_a206_openAllowed m206 : 17|1@1+ (1,0) [0|0] "" Vector__XXX
 SG_ VCRIGHT_a207_openAllowed m207 : 17|1@1+ (1,0) [0|0] "" Vector__XXX
 SG_ VCRIGHT_a208_openAllowed m208 : 17|1@1+ (1,0) [0|0] "" Vector__XXX
 SG_ VCRIGHT_a209_openAllowed m209 : 17|1@1+ (1,0) [0|0] "" Vector__XXX
 SG_ VCRIGHT_a210_openAllowed m210 : 17|1@1+ (1,0) [0|0] "" Vector__XXX
 SG_ VCRIGHT_a211_openAllowed m211 : 17|1@1+ (1,0) [0|0] "" Vector__XXX
 SG_ VCRIGHT_a212_openAllowed m212 : 17|1@1+ (1,0) [0|0] "" Vector__XXX
 SG_ VCRIGHT_a213_openAllowed m213 : 17|1@1+ (1,0) [0|0] "" Vector__XXX
 SG_ VCRIGHT_a214_openAllowed m214 : 17|1@1+ (1,0) [0|0] "" Vector__XXX
 SG_ VCRIGHT_a216_spiFault m216 : 17|1@1+ (1,0) [0|0] "" Vector__XXX
 SG_ VCRIGHT_a224_seatMotorCurrent m224 : 17|12@1- (0.01,0) [0|0] "" Vector__XXX
 SG_ VCRIGHT_a225_seatMotorCurrent m225 : 17|12@1- (0.01,0) [0|0] "" Vector__XXX
 SG_ VCRIGHT_a226_seatMotorCurrent m226 : 17|12@1- (0.01,0) [0|0] "" Vector__XXX
 SG_ VCRIGHT_a227_seatMotorCurrent m227 : 17|12@1- (0.01,0) [0|0] "" Vector__XXX
 SG_ VCRIGHT_a228_seatMotorCurrent m228 : 17|12@1- (0.01,0) [0|0] "" Vector__XXX
 SG_ VCRIGHT_a229_seatMotorCurrent m229 : 17|12@1- (0.01,0) [0|0] "" Vector__XXX
 SG_ VCRIGHT_a230_seatMotorCurrent m230 : 17|12@1- (0.01,0) [0|0] "" Vector__XXX
 SG_ VCRIGHT_a231_seatMotorCurrent m231 : 17|12@1- (0.01,0) [0|0] "" Vector__XXX
 SG_ VCRIGHT_a262_LVHigh m262 : 17|1@1+ (1,0) [0|0] "" Vector__XXX
 SG_ VCRIGHT_a271_temperatureSensorSNA m271 : 17|1@1+ (1,0) [0|0] "" Vector__XXX
 SG_ VCRIGHT_a275_currentSenseFaulted m275 : 17|1@1+ (1,0) [0|0] "" Vector__XXX
 SG_ VCRIGHT_a278_PTCMIA m278 : 17|1@1+ (1,0) [0|0] "" Vector__XXX
 SG_ VCRIGHT_a290_occupancySensorV m290 : 17|12@1- (0.01,0) [0|0] "" Vector__XXX
 SG_ VCRIGHT_a294_occupancySensorV m294 : 17|12@1- (0.01,0) [0|0] "" Vector__XXX
 SG_ VCRIGHT_a295_occupancySensorV m295 : 17|12@1- (0.01,0) [0|0] "" Vector__XXX
 SG_ VCRIGHT_a296_occupancySensorV m296 : 17|12@1- (0.01,0) [0|0] "" Vector__XXX
 SG_ VCRIGHT_a311_currentSenseFaulted m311 : 17|1@1+ (1,0) [0|0] "" Vector__XXX
 SG_ VCRIGHT_a312_currentSenseFaulted m312 : 17|1@1+ (1,0) [0|0] "" Vector__XXX
 SG_ VCRIGHT_a313_currentSenseFaulted m313 : 17|1@1+ (1,0) [0|0] "" Vector__XXX
 SG_ VCRIGHT_a314_currentSenseFaulted m314 : 17|1@1+ (1,0) [0|0] "" Vector__XXX
 SG_ VCRIGHT_a315_currentSenseFaulted m315 : 17|1@1+ (1,0) [0|0] "" Vector__XXX
 SG_ VCRIGHT_a318_currentSenseFaulted m318 : 17|1@1+ (1,0) [0|0] "" Vector__XXX
 SG_ VCRIGHT_a319_currentSenseFaulted m319 : 17|1@1+ (1,0) [0|0] "" Vector__XXX
 SG_ VCRIGHT_a368_snsDisconnect m368 : 17|1@1+ (1,0) [0|0] "" Vector__XXX
 SG_ VCRIGHT_a369_snsDisconnect m369 : 17|1@1+ (1,0) [0|0] "" Vector__XXX
 SG_ VCRIGHT_a377_snsDisconnect m377 : 17|1@1+ (1,0) [0|0] "" Vector__XXX
 SG_ VCRIGHT_a378_snsDisconnect m378 : 17|1@1+ (1,0) [0|0] "" Vector__XXX
 SG_ VCRIGHT_a379_snsDisconnect m379 : 17|1@1+ (1,0) [0|0] "" Vector__XXX
 SG_ VCRIGHT_a380_currentSenseFaulted m380 : 17|1@1+ (1,0) [0|0] "" Vector__XXX
 SG_ VCRIGHT_a381_currentSenseFaulted m381 : 17|1@1+ (1,0) [0|0] "" Vector__XXX
 SG_ VCRIGHT_a382_currentSenseFaulted m382 : 17|1@1+ (1,0) [0|0] "" Vector__XXX
 SG_ VCRIGHT_a426_seatMotorCurrent m426 : 17|12@1- (0.01,0) [0|0] "" Vector__XXX
 SG_ VCRIGHT_a427_seatMotorCurrent m427 : 17|12@1- (0.01,0) [0|0] "" Vector__XXX
 SG_ VCRIGHT_a428_seatMotorCurrent m428 : 17|12@1- (0.01,0) [0|0] "" Vector__XXX
 SG_ VCRIGHT_a429_seatMotorCurrent m429 : 17|12@1- (0.01,0) [0|0] "" Vector__XXX
 SG_ VCRIGHT_a446_evapHVACUnavailable m446 : 17|1@1+ (1,0) [0|0] "" Vector__XXX
 SG_ VCRIGHT_a448_manAirflowComfortHeatNudge m448 : 17|1@1+ (1,0) [0|0] "" Vector__XXX
 SG_ VCRIGHT_a450_datExceedingModel m450 : 17|1@1+ (1,0) [0|0] "" Vector__XXX
 SG_ VCRIGHT_a491_faultCurrent m491 : 17|10@1+ (0.01,0) [0|0] "" Vector__XXX
 SG_ VCRIGHT_a526_slowTemperatureRise m526 : 17|1@1+ (1,0) [0|0] "" Vector__XXX
 SG_ VCRIGHT_a537_outputsInvalid m537 : 17|1@1+ (1,0) [0|0] "" Vector__XXX
 SG_ VCRIGHT_a538_ductTempSensorFault m538 : 17|1@1+ (1,0) [0|0] "" Vector__XXX
 SG_ VCRIGHT_a539_modeledCabinTempOutOfRange m539 : 17|1@1+ (1,0) [0|0] "" Vector__XXX
 SG_ VCRIGHT_a540_LHVaneDBGDitherErrToTarget m540 : 17|5@1+ (1,0) [0|0] "" Vector__XXX
 SG_ VCRIGHT_a542_SWCHeaterFaulty m542 : 17|1@1+ (1,0) [0|0] "" Vector__XXX
 SG_ VCRIGHT_a598_modeledCabinTempOutOfRange m598 : 17|1@1+ (1,0) [0|0] "" Vector__XXX
 SG_ VCRIGHT_a617_BDY_defogInfoMessage m617 : 17|1@1+ (1,0) [0|0] "" Vector__XXX
 SG_ VCRIGHT_a012_SoftwareReset m12 : 18|1@1+ (1,0) [0|0] "" Vector__XXX
 SG_ VCRIGHT_a015_NVMMRecordIDError m15 : 18|1@1+ (1,0) [0|0] "" Vector__XXX
 SG_ VCRIGHT_a021_Task1msMissed m21 : 18|1@1+ (1,0) [0|0] "" Vector__XXX
 SG_ VCRIGHT_a065_index m65 : 18|5@1+ (1,0) [0|0] "" Vector__XXX
 SG_ VCRIGHT_a066_index m66 : 18|5@1+ (1,0) [0|0] "" Vector__XXX
 SG_ VCRIGHT_a082_RIPC_railStatus m82 : 18|1@1+ (1,0) [0|0] "" Vector__XXX
 SG_ VCRIGHT_a083_LIPC_railStatus m83 : 18|1@1+ (1,0) [0|0] "" Vector__XXX
 SG_ VCRIGHT_a086_VEH_status m86 : 18|1@1+ (1,0) [0|0] "" Vector__XXX
 SG_ VCRIGHT_a087_VEH_torque m87 : 18|1@1+ (1,0) [0|0] "" Vector__XXX
 SG_ VCRIGHT_a088_VEH_torque m88 : 18|1@1+ (1,0) [0|0] "" Vector__XXX
 SG_ VCRIGHT_a089_VEH_status m89 : 18|1@1+ (1,0) [0|0] "" Vector__XXX
 SG_ VCRIGHT_a090_PARTY_eacMonitor m90 : 18|1@1+ (1,0) [0|0] "" Vector__XXX
 SG_ VCRIGHT_a091_VEH_state m91 : 18|1@1+ (1,0) [0|0] "" Vector__XXX
 SG_ VCRIGHT_a092_VEH_seatStatus2 m92 : 18|1@1+ (1,0) [0|0] "" Vector__XXX
 SG_ VCRIGHT_a093_VEH_seatStatus2 m93 : 18|1@1+ (1,0) [0|0] "" Vector__XXX
 SG_ VCRIGHT_a098_VEH_status m98 : 18|1@1+ (1,0) [0|0] "" Vector__XXX
 SG_ VCRIGHT_a100_PT m100 : 18|1@1+ (1,0) [0|0] "" Vector__XXX
 SG_ VCRIGHT_a101_LIPC_externalWatchdogHeartBeat m101 : 18|1@1+ (1,0) [0|0] "" Vector__XXX
 SG_ VCRIGHT_a102_VEH_sensorStatus m102 : 18|1@1+ (1,0) [0|0] "" Vector__XXX
 SG_ VCRIGHT_a103_VEH_status m103 : 18|1@1+ (1,0) [0|0] "" Vector__XXX
 SG_ VCRIGHT_a104_VEH_chNm m104 : 18|1@1+ (1,0) [0|0] "" Vector__XXX
 SG_ VCRIGHT_a105_VEH_dampingStates m105 : 18|1@1+ (1,0) [0|0] "" Vector__XXX
 SG_ VCRIGHT_a106_VEH_dcdcRailStatus m106 : 18|1@1+ (1,0) [0|0] "" Vector__XXX
 SG_ VCRIGHT_a107_VEH_status m107 : 18|1@1+ (1,0) [0|0] "" Vector__XXX
 SG_ VCRIGHT_a108_VEH_thermalControl m108 : 18|1@1+ (1,0) [0|0] "" Vector__XXX
 SG_ VCRIGHT_a109_PARTY_nearDeploy m109 : 18|1@1+ (1,0) [0|0] "" Vector__XXX
 SG_ VCRIGHT_a110_VEH_time m110 : 18|1@1+ (1,0) [0|0] "" Vector__XXX
 SG_ VCRIGHT_a111_VEH_vehNm m111 : 18|1@1+ (1,0) [0|0] "" Vector__XXX
 SG_ VCRIGHT_a112_VEH_vehNm m112 : 18|1@1+ (1,0) [0|0] "" Vector__XXX
 SG_ VCRIGHT_a113_VEH_chargeRequest m113 : 18|1@1+ (1,0) [0|0] "" Vector__XXX
 SG_ VCRIGHT_a114_VEH_wheelSpeeds m114 : 18|1@1+ (1,0) [0|0] "" Vector__XXX
 SG_ VCRIGHT_a115_VEH_BLEResetRequest m115 : 18|1@1+ (1,0) [0|0] "" Vector__XXX
 SG_ VCRIGHT_a116_VEH_hvacRequest m116 : 18|1@1+ (1,0) [0|0] "" Vector__XXX
 SG_ VCRIGHT_a117_VEH_prndStatus m117 : 18|1@1+ (1,0) [0|0] "" Vector__XXX
 SG_ VCRIGHT_a118_VEH_sensors m118 : 18|1@1+ (1,0) [0|0] "" Vector__XXX
 SG_ VCRIGHT_a119_VEH_rightStalk m119 : 18|1@1+ (1,0) [0|0] "" Vector__XXX
 SG_ VCRIGHT_a120_CH_chassisCntl m120 : 18|1@1+ (1,0) [0|0] "" Vector__XXX
 SG_ VCRIGHT_a122_VEH_occupancy m122 : 18|1@1+ (1,0) [0|0] "" Vector__XXX
 SG_ VCRIGHT_a144_snsRateChangeUp m144 : 18|1@1+ (1,0) [0|0] "" Vector__XXX
 SG_ VCRIGHT_a145_snsRateChangeUp m145 : 18|1@1+ (1,0) [0|0] "" Vector__XXX
 SG_ VCRIGHT_a146_snsRateChangeUp m146 : 18|1@1+ (1,0) [0|0] "" Vector__XXX
 SG_ VCRIGHT_a147_snsRateChangeUp m147 : 18|1@1+ (1,0) [0|0] "" Vector__XXX
 SG_ VCRIGHT_a148_snsRateChangeUp m148 : 18|1@1+ (1,0) [0|0] "" Vector__XXX
 SG_ VCRIGHT_a149_snsRateChangeUp m149 : 18|1@1+ (1,0) [0|0] "" Vector__XXX
 SG_ VCRIGHT_a152_speedTableStatus m152 : 18|2@1+ (1,0) [0|0] "" Vector__XXX
 SG_ VCRIGHT_a153_speedTableStatus m153 : 18|2@1+ (1,0) [0|0] "" Vector__XXX
 SG_ VCRIGHT_a154_lightShowActive m154 : 18|1@1+ (1,0) [0|0] "" Vector__XXX
 SG_ VCRIGHT_a155_lightShowActive m155 : 18|1@1+ (1,0) [0|0] "" Vector__XXX
 SG_ VCRIGHT_a164_windowRear m164 : 18|1@1+ (1,0) [0|0] "" Vector__XXX
 SG_ VCRIGHT_a165_windowRear m165 : 18|1@1+ (1,0) [0|0] "" Vector__XXX
 SG_ VCRIGHT_a166_PINCH_V2C m166 : 18|1@1+ (1,0) [0|0] "" Vector__XXX
 SG_ VCRIGHT_a173_btnSwPackDownLR m173 : 18|1@1+ (1,0) [0|0] "" Vector__XXX
 SG_ VCRIGHT_a183_doorRear m183 : 18|1@1+ (1,0) [0|0] "" Vector__XXX
 SG_ VCRIGHT_a196_lockoutState m196 : 18|1@1+ (1,0) [0|0] "" Vector__XXX
 SG_ VCRIGHT_a197_lockoutState m197 : 18|1@1+ (1,0) [0|0] "" Vector__XXX
 SG_ VCRIGHT_a198_lockoutState m198 : 18|1@1+ (1,0) [0|0] "" Vector__XXX
 SG_ VCRIGHT_a199_lockoutState m199 : 18|1@1+ (1,0) [0|0] "" Vector__XXX
 SG_ VCRIGHT_a202_dynamicAllowed m202 : 18|1@1+ (1,0) [0|0] "" Vector__XXX
 SG_ VCRIGHT_a203_dynamicAllowed m203 : 18|1@1+ (1,0) [0|0] "" Vector__XXX
 SG_ VCRIGHT_a204_dynamicAllowed m204 : 18|1@1+ (1,0) [0|0] "" Vector__XXX
 SG_ VCRIGHT_a205_dynamicAllowed m205 : 18|1@1+ (1,0) [0|0] "" Vector__XXX
 SG_ VCRIGHT_a206_dynamicAllowed m206 : 18|1@1+ (1,0) [0|0] "" Vector__XXX
 SG_ VCRIGHT_a207_dynamicAllowed m207 : 18|1@1+ (1,0) [0|0] "" Vector__XXX
 SG_ VCRIGHT_a208_dynamicAllowed m208 : 18|1@1+ (1,0) [0|0] "" Vector__XXX
 SG_ VCRIGHT_a209_dynamicAllowed m209 : 18|1@1+ (1,0) [0|0] "" Vector__XXX
 SG_ VCRIGHT_a210_dynamicAllowed m210 : 18|1@1+ (1,0) [0|0] "" Vector__XXX
 SG_ VCRIGHT_a211_dynamicAllowed m211 : 18|1@1+ (1,0) [0|0] "" Vector__XXX
 SG_ VCRIGHT_a212_dynamicAllowed m212 : 18|1@1+ (1,0) [0|0] "" Vector__XXX
 SG_ VCRIGHT_a213_dynamicAllowed m213 : 18|1@1+ (1,0) [0|0] "" Vector__XXX
 SG_ VCRIGHT_a214_dynamicAllowed m214 : 18|1@1+ (1,0) [0|0] "" Vector__XXX
 SG_ VCRIGHT_a216_CRC_error m216 : 18|1@1+ (1,0) [0|0] "" Vector__XXX
 SG_ VCRIGHT_a262_HVLow m262 : 18|1@1+ (1,0) [0|0] "" Vector__XXX
 SG_ VCRIGHT_a271_solarVisSensorSNA m271 : 18|1@1+ (1,0) [0|0] "" Vector__XXX
 SG_ VCRIGHT_a272_actualState m272 : 18|2@1+ (1,0) [0|0] "" Vector__XXX
 SG_ VCRIGHT_a275_tempSenseFaulted m275 : 18|1@1+ (1,0) [0|0] "" Vector__XXX
 SG_ VCRIGHT_a311_tempSenseFaulted m311 : 18|1@1+ (1,0) [0|0] "" Vector__XXX
 SG_ VCRIGHT_a312_tempSenseFaulted m312 : 18|1@1+ (1,0) [0|0] "" Vector__XXX
 SG_ VCRIGHT_a313_tempSenseFaulted m313 : 18|1@1+ (1,0) [0|0] "" Vector__XXX
 SG_ VCRIGHT_a314_tempSenseFaulted m314 : 18|1@1+ (1,0) [0|0] "" Vector__XXX
 SG_ VCRIGHT_a315_tempSenseFaulted m315 : 18|1@1+ (1,0) [0|0] "" Vector__XXX
 SG_ VCRIGHT_a318_tempSenseFaulted m318 : 18|1@1+ (1,0) [0|0] "" Vector__XXX
 SG_ VCRIGHT_a319_tempSenseFaulted m319 : 18|1@1+ (1,0) [0|0] "" Vector__XXX
 SG_ VCRIGHT_a368_snsRateChangeUp m368 : 18|1@1+ (1,0) [0|0] "" Vector__XXX
 SG_ VCRIGHT_a369_snsRateChangeUp m369 : 18|1@1+ (1,0) [0|0] "" Vector__XXX
 SG_ VCRIGHT_a377_snsRateChangeUp m377 : 18|1@1+ (1,0) [0|0] "" Vector__XXX
 SG_ VCRIGHT_a378_snsRateChangeUp m378 : 18|1@1+ (1,0) [0|0] "" Vector__XXX
 SG_ VCRIGHT_a379_snsRateChangeUp m379 : 18|1@1+ (1,0) [0|0] "" Vector__XXX
 SG_ VCRIGHT_a380_tempSenseFaulted m380 : 18|1@1+ (1,0) [0|0] "" Vector__XXX
 SG_ VCRIGHT_a381_tempSenseFaulted m381 : 18|1@1+ (1,0) [0|0] "" Vector__XXX
 SG_ VCRIGHT_a382_tempSenseFaulted m382 : 18|1@1+ (1,0) [0|0] "" Vector__XXX
 SG_ VCRIGHT_a445_SPIFaultCount m445 : 18|2@1+ (1,0) [0|0] "" Vector__XXX
 SG_ VCRIGHT_a446_evapTempInvalid m446 : 18|1@1+ (1,0) [0|0] "" Vector__XXX
 SG_ VCRIGHT_a448_manAirflowFwdLkComfortHeatNudge m448 : 18|1@1+ (1,0) [0|0] "" Vector__XXX
 SG_ VCRIGHT_a450_heaterOverTemp m450 : 18|1@1+ (1,0) [0|0] "" Vector__XXX
 SG_ VCRIGHT_a499_remoteCdpState m499 : 18|2@1+ (1,0) [0|0] "" Vector__XXX
 SG_ VCRIGHT_a526_fastTemperatureRise m526 : 18|1@1+ (1,0) [0|0] "" Vector__XXX
 SG_ VCRIGHT_a538_evapTempSensorFault m538 : 18|1@1+ (1,0) [0|0] "" Vector__XXX
 SG_ VCRIGHT_a539_modeledCabinTempExceedingSetTemp m539 : 18|1@1+ (1,0) [0|0] "" Vector__XXX
 SG_ VCRIGHT_a542_ThermistorOverTemp m542 : 18|1@1+ (1,0) [0|0] "" Vector__XXX
 SG_ VCRIGHT_a546_mirrorFoldTypePrevious m546 : 18|2@1+ (1,0) [0|0] "" Vector__XXX
 SG_ VCRIGHT_a598_modeledCabinTempExceedingSetTemp m598 : 18|1@1+ (1,0) [0|0] "" Vector__XXX
 SG_ VCRIGHT_a617_VEH_thermalStatus m617 : 18|1@1+ (1,0) [0|0] "" Vector__XXX
 SG_ VCRIGHT_a012_CheckstopReset m12 : 19|1@1+ (1,0) [0|0] "" Vector__XXX
 SG_ VCRIGHT_a021_Task10msLate m21 : 19|1@1+ (1,0) [0|0] "" Vector__XXX
 SG_ VCRIGHT_a082_RIPC_remoteMux m82 : 19|1@1+ (1,0) [0|0] "" Vector__XXX
 SG_ VCRIGHT_a083_LIPC_HSDFaults m83 : 19|1@1+ (1,0) [0|0] "" Vector__XXX
 SG_ VCRIGHT_a086_VEH_12VBatteryStatus m86 : 19|1@1+ (1,0) [0|0] "" Vector__XXX
 SG_ VCRIGHT_a087_VEH_status m87 : 19|1@1+ (1,0) [0|0] "" Vector__XXX
 SG_ VCRIGHT_a088_VEH_status m88 : 19|1@1+ (1,0) [0|0] "" Vector__XXX
 SG_ VCRIGHT_a089_BDY_party1 m89 : 19|1@1+ (1,0) [0|0] "" Vector__XXX
 SG_ VCRIGHT_a090_CH_eacMonitor m90 : 19|1@1+ (1,0) [0|0] "" Vector__XXX
 SG_ VCRIGHT_a092_VEH_vehNm m92 : 19|1@1+ (1,0) [0|0] "" Vector__XXX
 SG_ VCRIGHT_a093_VEH_vehNm m93 : 19|1@1+ (1,0) [0|0] "" Vector__XXX
 SG_ VCRIGHT_a098_VEH_thermalControl m98 : 19|1@1+ (1,0) [0|0] "" Vector__XXX
 SG_ VCRIGHT_a100_CH m100 : 19|1@1+ (1,0) [0|0] "" Vector__XXX
 SG_ VCRIGHT_a101_VEH_locState m101 : 19|1@1+ (1,0) [0|0] "" Vector__XXX
 SG_ VCRIGHT_a102_VEH_rods m102 : 19|1@1+ (1,0) [0|0] "" Vector__XXX
 SG_ VCRIGHT_a103_PT_ptNm m103 : 19|1@1+ (1,0) [0|0] "" Vector__XXX
 SG_ VCRIGHT_a104_VEH_bodyControls m104 : 19|1@1+ (1,0) [0|0] "" Vector__XXX
 SG_ VCRIGHT_a106_CH_dcdcRailStatus m106 : 19|1@1+ (1,0) [0|0] "" Vector__XXX
 SG_ VCRIGHT_a107_VEH_thermalStatus m107 : 19|1@1+ (1,0) [0|0] "" Vector__XXX
 SG_ VCRIGHT_a108_VEH_torque m108 : 19|1@1+ (1,0) [0|0] "" Vector__XXX
 SG_ VCRIGHT_a109_PARTY_collision m109 : 19|1@1+ (1,0) [0|0] "" Vector__XXX
 SG_ VCRIGHT_a110_VEH_updateStatus m110 : 19|1@1+ (1,0) [0|0] "" Vector__XXX
 SG_ VCRIGHT_a111_RIPC_LVPowerState m111 : 19|1@1+ (1,0) [0|0] "" Vector__XXX
 SG_ VCRIGHT_a112_LIPC_LVPowerState m112 : 19|1@1+ (1,0) [0|0] "" Vector__XXX
 SG_ VCRIGHT_a113_VEH_vehicleControl m113 : 19|1@1+ (1,0) [0|0] "" Vector__XXX
 SG_ VCRIGHT_a114_CH_wheelSpeeds m114 : 19|1@1+ (1,0) [0|0] "" Vector__XXX
 SG_ VCRIGHT_a115_VEH_requests m115 : 19|1@1+ (1,0) [0|0] "" Vector__XXX
 SG_ VCRIGHT_a116_VEH_hvacStatus m116 : 19|1@1+ (1,0) [0|0] "" Vector__XXX
 SG_ VCRIGHT_a117_PARTY_epbmStatus m117 : 19|1@1+ (1,0) [0|0] "" Vector__XXX
 SG_ VCRIGHT_a118_VEH_status m118 : 19|1@1+ (1,0) [0|0] "" Vector__XXX
 SG_ VCRIGHT_a119_PARTY_rightStalk m119 : 19|1@1+ (1,0) [0|0] "" Vector__XXX
 SG_ VCRIGHT_a120_PARTY_systemStatus m120 : 19|1@1+ (1,0) [0|0] "" Vector__XXX
 SG_ VCRIGHT_a122_VEH_occupancy2 m122 : 19|1@1+ (1,0) [0|0] "" Vector__XXX
 SG_ VCRIGHT_a144_snsRateChangeDown m144 : 19|1@1+ (1,0) [0|0] "" Vector__XXX
 SG_ VCRIGHT_a145_snsRateChangeDown m145 : 19|1@1+ (1,0) [0|0] "" Vector__XXX
 SG_ VCRIGHT_a146_snsRateChangeDown m146 : 19|1@1+ (1,0) [0|0] "" Vector__XXX
 SG_ VCRIGHT_a147_snsRateChangeDown m147 : 19|1@1+ (1,0) [0|0] "" Vector__XXX
 SG_ VCRIGHT_a148_snsRateChangeDown m148 : 19|1@1+ (1,0) [0|0] "" Vector__XXX
 SG_ VCRIGHT_a149_snsRateChangeDown m149 : 19|1@1+ (1,0) [0|0] "" Vector__XXX
 SG_ VCRIGHT_a164_lastState m164 : 19|4@1+ (1,0) [0|0] "" Vector__XXX
 SG_ VCRIGHT_a166_PINCH_OVERRIDE m166 : 19|1@1+ (1,0) [0|0] "" Vector__XXX
 SG_ VCRIGHT_a173_btnSwPackAutoDownLR m173 : 19|1@1+ (1,0) [0|0] "" Vector__XXX
 SG_ VCRIGHT_a183_lastState m183 : 19|3@1+ (1,0) [0|0] "" Vector__XXX
 SG_ VCRIGHT_a202_parkAllowed m202 : 19|1@1+ (1,0) [0|0] "" Vector__XXX
 SG_ VCRIGHT_a203_parkAllowed m203 : 19|1@1+ (1,0) [0|0] "" Vector__XXX
 SG_ VCRIGHT_a204_parkAllowed m204 : 19|1@1+ (1,0) [0|0] "" Vector__XXX
 SG_ VCRIGHT_a205_parkAllowed m205 : 19|1@1+ (1,0) [0|0] "" Vector__XXX
 SG_ VCRIGHT_a206_parkAllowed m206 : 19|1@1+ (1,0) [0|0] "" Vector__XXX
 SG_ VCRIGHT_a207_parkAllowed m207 : 19|1@1+ (1,0) [0|0] "" Vector__XXX
 SG_ VCRIGHT_a208_parkAllowed m208 : 19|1@1+ (1,0) [0|0] "" Vector__XXX
 SG_ VCRIGHT_a209_parkAllowed m209 : 19|1@1+ (1,0) [0|0] "" Vector__XXX
 SG_ VCRIGHT_a210_parkAllowed m210 : 19|1@1+ (1,0) [0|0] "" Vector__XXX
 SG_ VCRIGHT_a211_parkAllowed m211 : 19|1@1+ (1,0) [0|0] "" Vector__XXX
 SG_ VCRIGHT_a212_parkAllowed m212 : 19|1@1+ (1,0) [0|0] "" Vector__XXX
 SG_ VCRIGHT_a213_parkAllowed m213 : 19|1@1+ (1,0) [0|0] "" Vector__XXX
 SG_ VCRIGHT_a214_parkAllowed m214 : 19|1@1+ (1,0) [0|0] "" Vector__XXX
 SG_ VCRIGHT_a216_monitor_MIA m216 : 19|1@1+ (1,0) [0|0] "" Vector__XXX
 SG_ VCRIGHT_a262_HVHigh m262 : 19|1@1+ (1,0) [0|0] "" Vector__XXX
 SG_ VCRIGHT_a271_solarInfSensorSNA m271 : 19|1@1+ (1,0) [0|0] "" Vector__XXX
 SG_ VCRIGHT_a275_underCurrent m275 : 19|1@1+ (1,0) [0|0] "" Vector__XXX
 SG_ VCRIGHT_a276_mirrorState m276 : 19|3@1+ (1,0) [0|0] "" Vector__XXX
 SG_ VCRIGHT_a311_underCurrent m311 : 19|1@1+ (1,0) [0|0] "" Vector__XXX
 SG_ VCRIGHT_a312_underCurrent m312 : 19|1@1+ (1,0) [0|0] "" Vector__XXX
 SG_ VCRIGHT_a313_underCurrent m313 : 19|1@1+ (1,0) [0|0] "" Vector__XXX
 SG_ VCRIGHT_a314_underCurrent m314 : 19|1@1+ (1,0) [0|0] "" Vector__XXX
 SG_ VCRIGHT_a315_underCurrent m315 : 19|1@1+ (1,0) [0|0] "" Vector__XXX
 SG_ VCRIGHT_a316_actuationDurationMs m316 : 19|10@1+ (10,0) [0|0] "" Vector__XXX
 SG_ VCRIGHT_a318_underCurrent m318 : 19|1@1+ (1,0) [0|0] "" Vector__XXX
 SG_ VCRIGHT_a319_underCurrent m319 : 19|1@1+ (1,0) [0|0] "" Vector__XXX
 SG_ VCRIGHT_a368_snsRateChangeDown m368 : 19|1@1+ (1,0) [0|0] "" Vector__XXX
 SG_ VCRIGHT_a369_snsRateChangeDown m369 : 19|1@1+ (1,0) [0|0] "" Vector__XXX
 SG_ VCRIGHT_a377_snsRateChangeDown m377 : 19|1@1+ (1,0) [0|0] "" Vector__XXX
 SG_ VCRIGHT_a378_snsRateChangeDown m378 : 19|1@1+ (1,0) [0|0] "" Vector__XXX
 SG_ VCRIGHT_a379_snsRateChangeDown m379 : 19|1@1+ (1,0) [0|0] "" Vector__XXX
 SG_ VCRIGHT_a380_underCurrent m380 : 19|1@1+ (1,0) [0|0] "" Vector__XXX
 SG_ VCRIGHT_a381_underCurrent m381 : 19|1@1+ (1,0) [0|0] "" Vector__XXX
 SG_ VCRIGHT_a382_underCurrent m382 : 19|1@1+ (1,0) [0|0] "" Vector__XXX
 SG_ VCRIGHT_a446_hvacBlowerFaulted m446 : 19|1@1+ (1,0) [0|0] "" Vector__XXX
 SG_ VCRIGHT_a448_manAirflowFwdLkComfortCoolNudge m448 : 19|1@1+ (1,0) [0|0] "" Vector__XXX
 SG_ VCRIGHT_a450_tempDuctLeft m450 : 19|8@1+ (0.5,-22) [0|0] "" Vector__XXX
 SG_ VCRIGHT_a454_failedRodLeft m454 : 19|3@1+ (1,0) [0|0] "" Vector__XXX
 SG_ VCRIGHT_a525_newLVBatteryType m525 : 19|3@1+ (1,0) [0|0] "" Vector__XXX
 SG_ VCRIGHT_a538_cabinTempSensorFault m538 : 19|1@1+ (1,0) [0|0] "" Vector__XXX
 SG_ VCRIGHT_a539_cabinTempSensorFault m539 : 19|1@1+ (1,0) [0|0] "" Vector__XXX
 SG_ VCRIGHT_a542_CabinProbeTempFaultyOrOverTemp m542 : 19|1@1+ (1,0) [0|0] "" Vector__XXX
 SG_ VCRIGHT_a545_newLVBatteryType m545 : 19|3@1+ (1,0) [0|0] "" Vector__XXX
 SG_ VCRIGHT_a589_blowerFault m589 : 19|1@1+ (1,0) [0|0] "" Vector__XXX
 SG_ VCRIGHT_a598_cabinTempSensorFault m598 : 19|1@1+ (1,0) [0|0] "" Vector__XXX
 SG_ VCRIGHT_a599_newLVBatteryType m599 : 19|3@1+ (1,0) [0|0] "" Vector__XXX
 SG_ VCRIGHT_a617_VEH_APP_VC_infoMessage m617 : 19|1@1+ (1,0) [0|0] "" Vector__XXX
 SG_ VCRIGHT_a005_faults0 m5 : 20|12@1+ (1,0) [0|0] "" Vector__XXX
 SG_ VCRIGHT_a006_fault m6 : 20|4@1+ (1,0) [0|0] "" Vector__XXX
 SG_ VCRIGHT_a012_DebugReset m12 : 20|1@1+ (1,0) [0|0] "" Vector__XXX
 SG_ VCRIGHT_a021_Task10msStarved m21 : 20|1@1+ (1,0) [0|0] "" Vector__XXX
 SG_ VCRIGHT_a086_VEH_LVPowerState m86 : 20|1@1+ (1,0) [0|0] "" Vector__XXX
 SG_ VCRIGHT_a087_PARTY_torque m87 : 20|1@1+ (1,0) [0|0] "" Vector__XXX
 SG_ VCRIGHT_a088_PARTY_torque m88 : 20|1@1+ (1,0) [0|0] "" Vector__XXX
 SG_ VCRIGHT_a089_BDY_status m89 : 20|1@1+ (1,0) [0|0] "" Vector__XXX
 SG_ VCRIGHT_a098_VEH_temperature m98 : 20|1@1+ (1,0) [0|0] "" Vector__XXX
 SG_ VCRIGHT_a100_OBD m100 : 20|1@1+ (1,0) [0|0] "" Vector__XXX
 SG_ VCRIGHT_a101_BDY_locState m101 : 20|1@1+ (1,0) [0|0] "" Vector__XXX
 SG_ VCRIGHT_a103_PT_status m103 : 20|1@1+ (1,0) [0|0] "" Vector__XXX
 SG_ VCRIGHT_a104_VEH_bodyControls3 m104 : 20|1@1+ (1,0) [0|0] "" Vector__XXX
 SG_ VCRIGHT_a106_CH_alertMatrix m106 : 20|1@1+ (1,0) [0|0] "" Vector__XXX
 SG_ VCRIGHT_a107_VEH_bmbMinMax m107 : 20|1@1+ (1,0) [0|0] "" Vector__XXX
 SG_ VCRIGHT_a108_VEH_status m108 : 20|1@1+ (1,0) [0|0] "" Vector__XXX
 SG_ VCRIGHT_a109_VEH_status m109 : 20|1@1+ (1,0) [0|0] "" Vector__XXX
 SG_ VCRIGHT_a110_VEH_vehNm m110 : 20|1@1+ (1,0) [0|0] "" Vector__XXX
 SG_ VCRIGHT_a111_RIPC_epbPrivateState m111 : 20|1@1+ (1,0) [0|0] "" Vector__XXX
 SG_ VCRIGHT_a112_LIPC_epbPrivateState m112 : 20|1@1+ (1,0) [0|0] "" Vector__XXX
 SG_ VCRIGHT_a113_VEH_vehicleControl2 m113 : 20|1@1+ (1,0) [0|0] "" Vector__XXX
 SG_ VCRIGHT_a114_PARTY_party3 m114 : 20|1@1+ (1,0) [0|0] "" Vector__XXX
 SG_ VCRIGHT_a115_VEH_requests2 m115 : 20|1@1+ (1,0) [0|0] "" Vector__XXX
 SG_ VCRIGHT_a116_VEH_LVPowerState m116 : 20|1@1+ (1,0) [0|0] "" Vector__XXX
 SG_ VCRIGHT_a117_VEH_vehNm m117 : 20|1@1+ (1,0) [0|0] "" Vector__XXX
 SG_ VCRIGHT_a118_VEH_okToUseHighPwr m118 : 20|1@1+ (1,0) [0|0] "" Vector__XXX
 SG_ VCRIGHT_a119_CH_steerAngle m119 : 20|1@1+ (1,0) [0|0] "" Vector__XXX
 SG_ VCRIGHT_a120_PARTY_torque m120 : 20|1@1+ (1,0) [0|0] "" Vector__XXX
 SG_ VCRIGHT_a152_causedByBackoffs m152 : 20|1@1+ (1,0) [0|0] "" Vector__XXX
 SG_ VCRIGHT_a153_causedByBackoffs m153 : 20|1@1+ (1,0) [0|0] "" Vector__XXX
 SG_ VCRIGHT_a166_THERMAL m166 : 20|1@1+ (1,0) [0|0] "" Vector__XXX
 SG_ VCRIGHT_a173_btnSwPackDownRF m173 : 20|1@1+ (1,0) [0|0] "" Vector__XXX
 SG_ VCRIGHT_a202_startAllowed m202 : 20|1@1+ (1,0) [0|0] "" Vector__XXX
 SG_ VCRIGHT_a203_startAllowed m203 : 20|1@1+ (1,0) [0|0] "" Vector__XXX
 SG_ VCRIGHT_a204_startAllowed m204 : 20|1@1+ (1,0) [0|0] "" Vector__XXX
 SG_ VCRIGHT_a205_startAllowed m205 : 20|1@1+ (1,0) [0|0] "" Vector__XXX
 SG_ VCRIGHT_a206_startAllowed m206 : 20|1@1+ (1,0) [0|0] "" Vector__XXX
 SG_ VCRIGHT_a207_startAllowed m207 : 20|1@1+ (1,0) [0|0] "" Vector__XXX
 SG_ VCRIGHT_a208_startAllowed m208 : 20|1@1+ (1,0) [0|0] "" Vector__XXX
 SG_ VCRIGHT_a209_startAllowed m209 : 20|1@1+ (1,0) [0|0] "" Vector__XXX
 SG_ VCRIGHT_a210_startAllowed m210 : 20|1@1+ (1,0) [0|0] "" Vector__XXX
 SG_ VCRIGHT_a211_startAllowed m211 : 20|1@1+ (1,0) [0|0] "" Vector__XXX
 SG_ VCRIGHT_a212_startAllowed m212 : 20|1@1+ (1,0) [0|0] "" Vector__XXX
 SG_ VCRIGHT_a213_startAllowed m213 : 20|1@1+ (1,0) [0|0] "" Vector__XXX
 SG_ VCRIGHT_a214_startAllowed m214 : 20|1@1+ (1,0) [0|0] "" Vector__XXX
 SG_ VCRIGHT_a262_LeftOverCurrent m262 : 20|1@1+ (1,0) [0|0] "" Vector__XXX
 SG_ VCRIGHT_a275_overCurrent m275 : 20|1@1+ (1,0) [0|0] "" Vector__XXX
 SG_ VCRIGHT_a311_overCurrent m311 : 20|1@1+ (1,0) [0|0] "" Vector__XXX
 SG_ VCRIGHT_a312_overCurrent m312 : 20|1@1+ (1,0) [0|0] "" Vector__XXX
 SG_ VCRIGHT_a313_overCurrent m313 : 20|1@1+ (1,0) [0|0] "" Vector__XXX
 SG_ VCRIGHT_a314_overCurrent m314 : 20|1@1+ (1,0) [0|0] "" Vector__XXX
 SG_ VCRIGHT_a315_overCurrent m315 : 20|1@1+ (1,0) [0|0] "" Vector__XXX
 SG_ VCRIGHT_a318_overCurrent m318 : 20|1@1+ (1,0) [0|0] "" Vector__XXX
 SG_ VCRIGHT_a319_overCurrent m319 : 20|1@1+ (1,0) [0|0] "" Vector__XXX
 SG_ VCRIGHT_a380_overCurrent m380 : 20|1@1+ (1,0) [0|0] "" Vector__XXX
 SG_ VCRIGHT_a381_overCurrent m381 : 20|1@1+ (1,0) [0|0] "" Vector__XXX
 SG_ VCRIGHT_a382_overCurrent m382 : 20|1@1+ (1,0) [0|0] "" Vector__XXX
 SG_ VCRIGHT_a446_evapOperationNotAllowed m446 : 20|1@1+ (1,0) [0|0] "" Vector__XXX
 SG_ VCRIGHT_a448_manACOffFwdLkComfortCoolNudge m448 : 20|1@1+ (1,0) [0|0] "" Vector__XXX
 SG_ VCRIGHT_a520_gtwEpbConfig m520 : 20|4@1+ (1,0) [0|0] "" Vector__XXX
 SG_ VCRIGHT_a538_cabinModelNotInitialized m538 : 20|1@1+ (1,0) [0|0] "" Vector__XXX
 SG_ VCRIGHT_a539_cabinTempSensorOutOfRange m539 : 20|1@1+ (1,0) [0|0] "" Vector__XXX
 SG_ VCRIGHT_a542_SWCFirmwareMismatch m542 : 20|1@1+ (1,0) [0|0] "" Vector__XXX
 SG_ VCRIGHT_a589_blowerRpm m589 : 20|1@1+ (1,0) [0|0] "" Vector__XXX
 SG_ VCRIGHT_a598_cabinTempSensorOutOfRange m598 : 20|1@1+ (1,0) [0|0] "" Vector__XXX
 SG_ VCRIGHT_a617_VEH_defogInfoMessage m617 : 20|1@1+ (1,0) [0|0] "" Vector__XXX
 SG_ VCRIGHT_a012_ExternalReset m12 : 21|1@1+ (1,0) [0|0] "" Vector__XXX
 SG_ VCRIGHT_a021_Task10msMissed m21 : 21|1@1+ (1,0) [0|0] "" Vector__XXX
 SG_ VCRIGHT_a086_VEH_lightStatus m86 : 21|1@1+ (1,0) [0|0] "" Vector__XXX
 SG_ VCRIGHT_a087_PARTY_status m87 : 21|1@1+ (1,0) [0|0] "" Vector__XXX
 SG_ VCRIGHT_a088_PARTY_status m88 : 21|1@1+ (1,0) [0|0] "" Vector__XXX
 SG_ VCRIGHT_a089_CH_status m89 : 21|1@1+ (1,0) [0|0] "" Vector__XXX
 SG_ VCRIGHT_a098_VEH_torque m98 : 21|1@1+ (1,0) [0|0] "" Vector__XXX
 SG_ VCRIGHT_a103_VEH_evseStatus m103 : 21|1@1+ (1,0) [0|0] "" Vector__XXX
 SG_ VCRIGHT_a104_BDY_bodyControls3 m104 : 21|1@1+ (1,0) [0|0] "" Vector__XXX
 SG_ VCRIGHT_a107_VEH_powerAvailable m107 : 21|1@1+ (1,0) [0|0] "" Vector__XXX
 SG_ VCRIGHT_a108_PARTY_torque m108 : 21|1@1+ (1,0) [0|0] "" Vector__XXX
 SG_ VCRIGHT_a109_VEH_imuOffsets m109 : 21|1@1+ (1,0) [0|0] "" Vector__XXX
 SG_ VCRIGHT_a110_VEH_mismatchFault m110 : 21|1@1+ (1,0) [0|0] "" Vector__XXX
 SG_ VCRIGHT_a111_RIPC_railStatus m111 : 21|1@1+ (1,0) [0|0] "" Vector__XXX
 SG_ VCRIGHT_a112_LIPC_railStatus m112 : 21|1@1+ (1,0) [0|0] "" Vector__XXX
 SG_ VCRIGHT_a113_VEH_peripheralPowerRequests m113 : 21|1@1+ (1,0) [0|0] "" Vector__XXX
 SG_ VCRIGHT_a114_VEH_party3 m114 : 21|1@1+ (1,0) [0|0] "" Vector__XXX
 SG_ VCRIGHT_a115_REM_authentication m115 : 21|1@1+ (1,0) [0|0] "" Vector__XXX
 SG_ VCRIGHT_a116_VEH_lightStatus m116 : 21|1@1+ (1,0) [0|0] "" Vector__XXX
 SG_ VCRIGHT_a117_VEH_hvacBlowerFdb m117 : 21|1@1+ (1,0) [0|0] "" Vector__XXX
 SG_ VCRIGHT_a118_VEH_LVPowerState m118 : 21|1@1+ (1,0) [0|0] "" Vector__XXX
 SG_ VCRIGHT_a119_PARTY_steerAngle m119 : 21|1@1+ (1,0) [0|0] "" Vector__XXX
 SG_ VCRIGHT_a120_VEH_torque m120 : 21|1@1+ (1,0) [0|0] "" Vector__XXX
 SG_ VCRIGHT_a166_THERMAL_BLOCKED m166 : 21|1@1+ (1,0) [0|0] "" Vector__XXX
 SG_ VCRIGHT_a173_btnSwPackAutoDownRF m173 : 21|1@1+ (1,0) [0|0] "" Vector__XXX
 SG_ VCRIGHT_a202_serviceAllowed m202 : 21|1@1+ (1,0) [0|0] "" Vector__XXX
 SG_ VCRIGHT_a203_serviceAllowed m203 : 21|1@1+ (1,0) [0|0] "" Vector__XXX
 SG_ VCRIGHT_a204_serviceAllowed m204 : 21|1@1+ (1,0) [0|0] "" Vector__XXX
 SG_ VCRIGHT_a205_serviceAllowed m205 : 21|1@1+ (1,0) [0|0] "" Vector__XXX
 SG_ VCRIGHT_a206_serviceAllowed m206 : 21|1@1+ (1,0) [0|0] "" Vector__XXX
 SG_ VCRIGHT_a207_serviceAllowed m207 : 21|1@1+ (1,0) [0|0] "" Vector__XXX
 SG_ VCRIGHT_a208_serviceAllowed m208 : 21|1@1+ (1,0) [0|0] "" Vector__XXX
 SG_ VCRIGHT_a209_serviceAllowed m209 : 21|1@1+ (1,0) [0|0] "" Vector__XXX
 SG_ VCRIGHT_a210_serviceAllowed m210 : 21|1@1+ (1,0) [0|0] "" Vector__XXX
 SG_ VCRIGHT_a211_serviceAllowed m211 : 21|1@1+ (1,0) [0|0] "" Vector__XXX
 SG_ VCRIGHT_a212_serviceAllowed m212 : 21|1@1+ (1,0) [0|0] "" Vector__XXX
 SG_ VCRIGHT_a213_serviceAllowed m213 : 21|1@1+ (1,0) [0|0] "" Vector__XXX
 SG_ VCRIGHT_a214_serviceAllowed m214 : 21|1@1+ (1,0) [0|0] "" Vector__XXX
 SG_ VCRIGHT_a262_RightOverCurrent m262 : 21|1@1+ (1,0) [0|0] "" Vector__XXX
 SG_ VCRIGHT_a275_overTemperature m275 : 21|1@1+ (1,0) [0|0] "" Vector__XXX
 SG_ VCRIGHT_a311_overTemperature m311 : 21|1@1+ (1,0) [0|0] "" Vector__XXX
 SG_ VCRIGHT_a312_overTemperature m312 : 21|1@1+ (1,0) [0|0] "" Vector__XXX
 SG_ VCRIGHT_a313_overTemperature m313 : 21|1@1+ (1,0) [0|0] "" Vector__XXX
 SG_ VCRIGHT_a314_overTemperature m314 : 21|1@1+ (1,0) [0|0] "" Vector__XXX
 SG_ VCRIGHT_a315_overTemperature m315 : 21|1@1+ (1,0) [0|0] "" Vector__XXX
 SG_ VCRIGHT_a318_overTemperature m318 : 21|1@1+ (1,0) [0|0] "" Vector__XXX
 SG_ VCRIGHT_a319_overTemperature m319 : 21|1@1+ (1,0) [0|0] "" Vector__XXX
 SG_ VCRIGHT_a380_overTemperature m380 : 21|1@1+ (1,0) [0|0] "" Vector__XXX
 SG_ VCRIGHT_a381_overTemperature m381 : 21|1@1+ (1,0) [0|0] "" Vector__XXX
 SG_ VCRIGHT_a382_overTemperature m382 : 21|1@1+ (1,0) [0|0] "" Vector__XXX
 SG_ VCRIGHT_a446_allAirPathsBlocked m446 : 21|1@1+ (1,0) [0|0] "" Vector__XXX
 SG_ VCRIGHT_a448_manFreshComfortHeatManualHVACIntvn m448 : 21|1@1+ (1,0) [0|0] "" Vector__XXX
 SG_ VCRIGHT_a538_airpathsBlocked m538 : 21|1@1+ (1,0) [0|0] "" Vector__XXX
 SG_ VCRIGHT_a539_modeledCabinTempDeviation m539 : 21|1@1+ (1,0) [0|0] "" Vector__XXX
 SG_ VCRIGHT_a589_intakeDoor m589 : 21|1@1+ (1,0) [0|0] "" Vector__XXX
 SG_ VCRIGHT_a598_modeledCabinTempDeviation m598 : 21|1@1+ (1,0) [0|0] "" Vector__XXX
 SG_ VCRIGHT_a021_Task100msLate m21 : 22|1@1+ (1,0) [0|0] "" Vector__XXX
 SG_ VCRIGHT_a086_VEH_systemStatus m86 : 22|1@1+ (1,0) [0|0] "" Vector__XXX
 SG_ VCRIGHT_a087_PARTY_temperature m87 : 22|1@1+ (1,0) [0|0] "" Vector__XXX
 SG_ VCRIGHT_a088_PARTY_temperature m88 : 22|1@1+ (1,0) [0|0] "" Vector__XXX
 SG_ VCRIGHT_a089_CH_party1 m89 : 22|1@1+ (1,0) [0|0] "" Vector__XXX
 SG_ VCRIGHT_a098_PARTY_status m98 : 22|1@1+ (1,0) [0|0] "" Vector__XXX
 SG_ VCRIGHT_a104_VEH_thermalStatus m104 : 22|1@1+ (1,0) [0|0] "" Vector__XXX
 SG_ VCRIGHT_a107_PT_ptNm m107 : 22|1@1+ (1,0) [0|0] "" Vector__XXX
 SG_ VCRIGHT_a108_PARTY_status m108 : 22|1@1+ (1,0) [0|0] "" Vector__XXX
 SG_ VCRIGHT_a109_PARTY_inertial1 m109 : 22|1@1+ (1,0) [0|0] "" Vector__XXX
 SG_ VCRIGHT_a110_VEH_vin m110 : 22|1@1+ (1,0) [0|0] "" Vector__XXX
 SG_ VCRIGHT_a111_RIPC_remoteADC m111 : 22|1@1+ (1,0) [0|0] "" Vector__XXX
 SG_ VCRIGHT_a112_LIPC_remoteADC m112 : 22|1@1+ (1,0) [0|0] "" Vector__XXX
 SG_ VCRIGHT_a113_VEH_corianderVehicleControl m113 : 22|1@1+ (1,0) [0|0] "" Vector__XXX
 SG_ VCRIGHT_a114_VEH_status m114 : 22|1@1+ (1,0) [0|0] "" Vector__XXX
 SG_ VCRIGHT_a115_UI_corianderVehicleControl m115 : 22|1@1+ (1,0) [0|0] "" Vector__XXX
 SG_ VCRIGHT_a116_VEH_seatStatus m116 : 22|1@1+ (1,0) [0|0] "" Vector__XXX
 SG_ VCRIGHT_a117_VEH_LVPowerState m117 : 22|1@1+ (1,0) [0|0] "" Vector__XXX
 SG_ VCRIGHT_a118_VEH_coolant m118 : 22|1@1+ (1,0) [0|0] "" Vector__XXX
 SG_ VCRIGHT_a120_PARTY_locStatus m120 : 22|1@1+ (1,0) [0|0] "" Vector__XXX
 SG_ VCRIGHT_a166_CAL_CLEAR_SWITCH m166 : 22|1@1+ (1,0) [0|0] "" Vector__XXX
 SG_ VCRIGHT_a173_btnSwPackDownRR m173 : 22|1@1+ (1,0) [0|0] "" Vector__XXX
 SG_ VCRIGHT_a202_winchAllowed m202 : 22|1@1+ (1,0) [0|0] "" Vector__XXX
 SG_ VCRIGHT_a203_winchAllowed m203 : 22|1@1+ (1,0) [0|0] "" Vector__XXX
 SG_ VCRIGHT_a204_winchAllowed m204 : 22|1@1+ (1,0) [0|0] "" Vector__XXX
 SG_ VCRIGHT_a205_winchAllowed m205 : 22|1@1+ (1,0) [0|0] "" Vector__XXX
 SG_ VCRIGHT_a206_winchAllowed m206 : 22|1@1+ (1,0) [0|0] "" Vector__XXX
 SG_ VCRIGHT_a207_winchAllowed m207 : 22|1@1+ (1,0) [0|0] "" Vector__XXX
 SG_ VCRIGHT_a208_winchAllowed m208 : 22|1@1+ (1,0) [0|0] "" Vector__XXX
 SG_ VCRIGHT_a209_winchAllowed m209 : 22|1@1+ (1,0) [0|0] "" Vector__XXX
 SG_ VCRIGHT_a210_winchAllowed m210 : 22|1@1+ (1,0) [0|0] "" Vector__XXX
 SG_ VCRIGHT_a211_winchAllowed m211 : 22|1@1+ (1,0) [0|0] "" Vector__XXX
 SG_ VCRIGHT_a212_winchAllowed m212 : 22|1@1+ (1,0) [0|0] "" Vector__XXX
 SG_ VCRIGHT_a213_winchAllowed m213 : 22|1@1+ (1,0) [0|0] "" Vector__XXX
 SG_ VCRIGHT_a214_winchAllowed m214 : 22|1@1+ (1,0) [0|0] "" Vector__XXX
 SG_ VCRIGHT_a262_LeftShutOutlet m262 : 22|1@1+ (1,0) [0|0] "" Vector__XXX
 SG_ VCRIGHT_a276_mirrorDip m276 : 22|1@1+ (1,0) [0|0] "" Vector__XXX
 SG_ VCRIGHT_a446_rawDuctTempInvalidLeft m446 : 22|1@1+ (1,0) [0|0] "" Vector__XXX
 SG_ VCRIGHT_a448_manFreshComfortCoolManualHVACIntvn m448 : 22|1@1+ (1,0) [0|0] "" Vector__XXX
 SG_ VCRIGHT_a482_spiFault m482 : 22|1@1+ (1,0) [0|0] "" Vector__XXX
 SG_ VCRIGHT_a538_blowerFaultOrStopped m538 : 22|1@1+ (1,0) [0|0] "" Vector__XXX
 SG_ VCRIGHT_a540_LHBleedDebugDither m540 : 22|1@1+ (1,0) [0|0] "" Vector__XXX
 SG_ VCRIGHT_a545_serviceMode m545 : 22|1@1+ (1,0) [0|0] "" Vector__XXX
 SG_ VCRIGHT_a589_upperModeDoor m589 : 22|1@1+ (1,0) [0|0] "" Vector__XXX
 SG_ VCRIGHT_a598_cabinTempSensorOutOfRangeLow m598 : 22|1@1+ (1,0) [0|0] "" Vector__XXX
 SG_ VCRIGHT_a021_Task100msStarved m21 : 23|1@1+ (1,0) [0|0] "" Vector__XXX
 SG_ VCRIGHT_a066_totalShortPeriods m66 : 23|16@1+ (10,0) [0|0] "" Vector__XXX
 SG_ VCRIGHT_a086_VEH_thermalStatus m86 : 23|1@1+ (1,0) [0|0] "" Vector__XXX
 SG_ VCRIGHT_a087_PARTY_thermalControl m87 : 23|1@1+ (1,0) [0|0] "" Vector__XXX
 SG_ VCRIGHT_a088_PARTY_thermalControl m88 : 23|1@1+ (1,0) [0|0] "" Vector__XXX
 SG_ VCRIGHT_a089_CH_party3 m89 : 23|1@1+ (1,0) [0|0] "" Vector__XXX
 SG_ VCRIGHT_a098_PARTY_temperature m98 : 23|1@1+ (1,0) [0|0] "" Vector__XXX
 SG_ VCRIGHT_a104_CH_control m104 : 23|1@1+ (1,0) [0|0] "" Vector__XXX
 SG_ VCRIGHT_a107_PT_status m107 : 23|1@1+ (1,0) [0|0] "" Vector__XXX
 SG_ VCRIGHT_a108_PARTY_temperature m108 : 23|1@1+ (1,0) [0|0] "" Vector__XXX
 SG_ VCRIGHT_a109_BDY_imuOffsets m109 : 23|1@1+ (1,0) [0|0] "" Vector__XXX
 SG_ VCRIGHT_a110_VEH_bmpDebug m110 : 23|1@1+ (1,0) [0|0] "" Vector__XXX
 SG_ VCRIGHT_a111_RIPC_switchStatus m111 : 23|1@1+ (1,0) [0|0] "" Vector__XXX
 SG_ VCRIGHT_a112_LIPC_switchStatus m112 : 23|1@1+ (1,0) [0|0] "" Vector__XXX
 SG_ VCRIGHT_a113_VEH_solarData m113 : 23|1@1+ (1,0) [0|0] "" Vector__XXX
 SG_ VCRIGHT_a114_PARTY_wheelRotation m114 : 23|1@1+ (1,0) [0|0] "" Vector__XXX
 SG_ VCRIGHT_a115_CH_TPMSDisplay m115 : 23|1@1+ (1,0) [0|0] "" Vector__XXX
 SG_ VCRIGHT_a116_VEH_thsStatus m116 : 23|1@1+ (1,0) [0|0] "" Vector__XXX
 SG_ VCRIGHT_a117_VEH_restraintStatus m117 : 23|1@1+ (1,0) [0|0] "" Vector__XXX
 SG_ VCRIGHT_a118_VEH_vehicleStatus m118 : 23|1@1+ (1,0) [0|0] "" Vector__XXX
 SG_ VCRIGHT_a120_PARTY_speed m120 : 23|1@1+ (1,0) [0|0] "" Vector__XXX
 SG_ VCRIGHT_a166_CAL_CLEAR_POS m166 : 23|1@1+ (1,0) [0|0] "" Vector__XXX
 SG_ VCRIGHT_a173_btnSwPackAutoDownRR m173 : 23|1@1+ (1,0) [0|0] "" Vector__XXX
 SG_ VCRIGHT_a200_motorChannels m200 : 23|16@1+ (1,0) [0|0] "" Vector__XXX
 SG_ VCRIGHT_a202_winchReleaseAllowed m202 : 23|1@1+ (1,0) [0|0] "" Vector__XXX
 SG_ VCRIGHT_a203_winchReleaseAllowed m203 : 23|1@1+ (1,0) [0|0] "" Vector__XXX
 SG_ VCRIGHT_a204_winchReleaseAllowed m204 : 23|1@1+ (1,0) [0|0] "" Vector__XXX
 SG_ VCRIGHT_a205_winchReleaseAllowed m205 : 23|1@1+ (1,0) [0|0] "" Vector__XXX
 SG_ VCRIGHT_a206_winchReleaseAllowed m206 : 23|1@1+ (1,0) [0|0] "" Vector__XXX
 SG_ VCRIGHT_a207_winchReleaseAllowed m207 : 23|1@1+ (1,0) [0|0] "" Vector__XXX
 SG_ VCRIGHT_a208_winchReleaseAllowed m208 : 23|1@1+ (1,0) [0|0] "" Vector__XXX
 SG_ VCRIGHT_a209_winchReleaseAllowed m209 : 23|1@1+ (1,0) [0|0] "" Vector__XXX
 SG_ VCRIGHT_a210_winchReleaseAllowed m210 : 23|1@1+ (1,0) [0|0] "" Vector__XXX
 SG_ VCRIGHT_a211_winchReleaseAllowed m211 : 23|1@1+ (1,0) [0|0] "" Vector__XXX
 SG_ VCRIGHT_a212_winchReleaseAllowed m212 : 23|1@1+ (1,0) [0|0] "" Vector__XXX
 SG_ VCRIGHT_a213_winchReleaseAllowed m213 : 23|1@1+ (1,0) [0|0] "" Vector__XXX
 SG_ VCRIGHT_a214_winchReleaseAllowed m214 : 23|1@1+ (1,0) [0|0] "" Vector__XXX
 SG_ VCRIGHT_a262_RightShutOutlet m262 : 23|1@1+ (1,0) [0|0] "" Vector__XXX
 SG_ VCRIGHT_a446_rawDuctTempInvalidRight m446 : 23|1@1+ (1,0) [0|0] "" Vector__XXX
 SG_ VCRIGHT_a448_manFreshComfortCoolAutoHVACIntvn m448 : 23|1@1+ (1,0) [0|0] "" Vector__XXX
 SG_ VCRIGHT_a482_resetBar m482 : 23|1@1+ (1,0) [0|0] "" Vector__XXX
 SG_ VCRIGHT_a538_compressorFaultOrStandby m538 : 23|1@1+ (1,0) [0|0] "" Vector__XXX
 SG_ VCRIGHT_a545_factoryGated m545 : 23|1@1+ (1,0) [0|0] "" Vector__XXX
 SG_ VCRIGHT_a589_cameraHeaterGrid m589 : 23|1@1+ (1,0) [0|0] "" Vector__XXX
 SG_ VCRIGHT_a006_mailboxID m6 : 24|8@1+ (1,0) [0|0] "" Vector__XXX
 SG_ VCRIGHT_a021_Task100msMissed m21 : 24|1@1+ (1,0) [0|0] "" Vector__XXX
 SG_ VCRIGHT_a022_TaskInitError0 m22 : 24|8@1+ (1,0) [0|0] "" Vector__XXX
 SG_ VCRIGHT_a031_uds_bytes_1 m31 : 24|8@1+ (1,0) [0|0] "" Vector__XXX
 SG_ VCRIGHT_a041_CPULoad1msTask m41 : 24|8@1+ (1,0) [0|0] "" Vector__XXX
 SG_ VCRIGHT_a042_Usage10msTask m42 : 24|8@1+ (1,0) [0|0] "" Vector__XXX
 SG_ VCRIGHT_a063_switchType m63 : 24|8@1+ (1,0) [0|0] "" Vector__XXX
 SG_ VCRIGHT_a086_VEH_vehNm m86 : 24|1@1+ (1,0) [0|0] "" Vector__XXX
 SG_ VCRIGHT_a087_VEH_motorStatus m87 : 24|1@1+ (1,0) [0|0] "" Vector__XXX
 SG_ VCRIGHT_a088_VEH_motorStatus m88 : 24|1@1+ (1,0) [0|0] "" Vector__XXX
 SG_ VCRIGHT_a089_VEH_party1 m89 : 24|1@1+ (1,0) [0|0] "" Vector__XXX
 SG_ VCRIGHT_a098_PARTY_thermalControl m98 : 24|1@1+ (1,0) [0|0] "" Vector__XXX
 SG_ VCRIGHT_a104_PARTY_control m104 : 24|1@1+ (1,0) [0|0] "" Vector__XXX
 SG_ VCRIGHT_a107_PT_thermalStatus m107 : 24|1@1+ (1,0) [0|0] "" Vector__XXX
 SG_ VCRIGHT_a108_PARTY_thermalControl m108 : 24|1@1+ (1,0) [0|0] "" Vector__XXX
 SG_ VCRIGHT_a109_BDY_inertial1 m109 : 24|1@1+ (1,0) [0|0] "" Vector__XXX
 SG_ VCRIGHT_a110_VEH_gearControl m110 : 24|1@1+ (1,0) [0|0] "" Vector__XXX
 SG_ VCRIGHT_a111_VEH_LVPowerState m111 : 24|1@1+ (1,0) [0|0] "" Vector__XXX
 SG_ VCRIGHT_a112_VEH_LVPowerState m112 : 24|1@1+ (1,0) [0|0] "" Vector__XXX
 SG_ VCRIGHT_a113_VEH_ventCntlReq m113 : 24|1@1+ (1,0) [0|0] "" Vector__XXX
 SG_ VCRIGHT_a114_CH_wheelRotation m114 : 24|1@1+ (1,0) [0|0] "" Vector__XXX
 SG_ VCRIGHT_a115_VEH_RSSI m115 : 24|1@1+ (1,0) [0|0] "" Vector__XXX
 SG_ VCRIGHT_a116_VEH_doorStatus m116 : 24|1@1+ (1,0) [0|0] "" Vector__XXX
 SG_ VCRIGHT_a117_VEH_lightStatus m117 : 24|1@1+ (1,0) [0|0] "" Vector__XXX
 SG_ VCRIGHT_a118_VEH_12VBatteryStatus m118 : 24|1@1+ (1,0) [0|0] "" Vector__XXX
 SG_ VCRIGHT_a120_VEH_speed m120 : 24|1@1+ (1,0) [0|0] "" Vector__XXX
 SG_ VCRIGHT_a164_stopReason m164 : 24|3@1+ (1,0) [0|0] "" Vector__XXX
 SG_ VCRIGHT_a165_maxClosingPower m165 : 24|8@1+ (1,0) [0|0] "" Vector__XXX
 SG_ VCRIGHT_a166_CAL_CLEAR_PARTIAL m166 : 24|1@1+ (1,0) [0|0] "" Vector__XXX
 SG_ VCRIGHT_a167_movementTimeMs m167 : 24|7@1+ (50,0) [0|0] "" Vector__XXX
 SG_ VCRIGHT_a168_movementTimeMs m168 : 24|7@1+ (50,0) [0|0] "" Vector__XXX
 SG_ VCRIGHT_a169_currentPeakPosition m169 : 24|8@1+ (10,0) [0|0] "" Vector__XXX
 SG_ VCRIGHT_a170_currentPeakPosition m170 : 24|8@1+ (10,0) [0|0] "" Vector__XXX
 SG_ VCRIGHT_a173_isRHD m173 : 24|1@1+ (1,0) [0|0] "" Vector__XXX
 SG_ VCRIGHT_a180_extHandlePWM m180 : 24|8@1+ (1,0) [0|0] "" Vector__XXX
 SG_ VCRIGHT_a181_extHandlePWM m181 : 24|8@1+ (1,0) [0|0] "" Vector__XXX
 SG_ VCRIGHT_a183_stopReason m183 : 24|4@1+ (1,0) [0|0] "" Vector__XXX
 SG_ VCRIGHT_a184_temperature m184 : 24|8@1+ (0.5,-40) [0|0] "" Vector__XXX
 SG_ VCRIGHT_a186_temperature m186 : 24|8@1+ (0.5,-40) [0|0] "" Vector__XXX
 SG_ VCRIGHT_a187_temperature m187 : 24|8@1+ (0.5,-40) [0|0] "" Vector__XXX
 SG_ VCRIGHT_a188_temperature m188 : 24|8@1+ (0.5,-40) [0|0] "" Vector__XXX
 SG_ VCRIGHT_a189_temperature m189 : 24|8@1+ (0.5,-40) [0|0] "" Vector__XXX
 SG_ VCRIGHT_a201_motorChannels m201 : 24|16@1+ (1,0) [0|0] "" Vector__XXX
 SG_ VCRIGHT_a202_parkingAllowed m202 : 24|1@1+ (1,0) [0|0] "" Vector__XXX
 SG_ VCRIGHT_a203_parkingAllowed m203 : 24|1@1+ (1,0) [0|0] "" Vector__XXX
 SG_ VCRIGHT_a204_parkingAllowed m204 : 24|1@1+ (1,0) [0|0] "" Vector__XXX
 SG_ VCRIGHT_a205_parkingAllowed m205 : 24|1@1+ (1,0) [0|0] "" Vector__XXX
 SG_ VCRIGHT_a206_parkingAllowed m206 : 24|1@1+ (1,0) [0|0] "" Vector__XXX
 SG_ VCRIGHT_a207_parkingAllowed m207 : 24|1@1+ (1,0) [0|0] "" Vector__XXX
 SG_ VCRIGHT_a208_parkingAllowed m208 : 24|1@1+ (1,0) [0|0] "" Vector__XXX
 SG_ VCRIGHT_a209_parkingAllowed m209 : 24|1@1+ (1,0) [0|0] "" Vector__XXX
 SG_ VCRIGHT_a210_parkingAllowed m210 : 24|1@1+ (1,0) [0|0] "" Vector__XXX
 SG_ VCRIGHT_a211_parkingAllowed m211 : 24|1@1+ (1,0) [0|0] "" Vector__XXX
 SG_ VCRIGHT_a212_parkingAllowed m212 : 24|1@1+ (1,0) [0|0] "" Vector__XXX
 SG_ VCRIGHT_a213_parkingAllowed m213 : 24|1@1+ (1,0) [0|0] "" Vector__XXX
 SG_ VCRIGHT_a214_parkingAllowed m214 : 24|1@1+ (1,0) [0|0] "" Vector__XXX
 SG_ VCRIGHT_a216_byte0 m216 : 24|8@1+ (1,0) [0|0] "" Vector__XXX
 SG_ VCRIGHT_a217_byte5 m217 : 24|8@1+ (1,0) [0|0] "" Vector__XXX
 SG_ VCRIGHT_a255_rightIGBTTemp m255 : 24|8@1- (1,80) [0|0] "" Vector__XXX
 SG_ VCRIGHT_a256_rightCurrent m256 : 24|8@1+ (0.2,0) [0|0] "" Vector__XXX
 SG_ VCRIGHT_a259_voltage m259 : 24|7@1+ (0.15,0) [0|0] "" Vector__XXX
 SG_ VCRIGHT_a260_voltage m260 : 24|7@1+ (0.15,0) [0|0] "" Vector__XXX
 SG_ VCRIGHT_a262_ThermalShutPCB m262 : 24|1@1+ (1,0) [0|0] "" Vector__XXX
 SG_ VCRIGHT_a273_temperature m273 : 24|8@1+ (0.5,-40) [0|0] "" Vector__XXX
 SG_ VCRIGHT_a274_temperature m274 : 24|8@1+ (0.5,-40) [0|0] "" Vector__XXX
 SG_ VCRIGHT_a276_mirrorTiltXPosition m276 : 24|8@1+ (0.02,0) [0|0] "" Vector__XXX
 SG_ VCRIGHT_a282_temperature m282 : 24|8@1+ (0.5,-40) [0|0] "" Vector__XXX
 SG_ VCRIGHT_a283_temperature m283 : 24|8@1+ (0.5,-40) [0|0] "" Vector__XXX
 SG_ VCRIGHT_a284_gloveboxMaxCurrent m284 : 24|8@1+ (0.1,0) [0|0] "" Vector__XXX
 SG_ VCRIGHT_a285_gloveboxMaxCurrent m285 : 24|8@1+ (0.1,0) [0|0] "" Vector__XXX
 SG_ VCRIGHT_a286_windowDirectionUp m286 : 24|1@1+ (1,0) [0|0] "" Vector__XXX
 SG_ VCRIGHT_a287_windowDirectionUp m287 : 24|1@1+ (1,0) [0|0] "" Vector__XXX
 SG_ VCRIGHT_a288_temperature m288 : 24|8@1+ (0.5,-40) [0|0] "" Vector__XXX
 SG_ VCRIGHT_a289_temperature m289 : 24|8@1+ (0.5,-40) [0|0] "" Vector__XXX
 SG_ VCRIGHT_a330_maxCurrent m330 : 24|7@1+ (0.25,0) [0|0] "" Vector__XXX
 SG_ VCRIGHT_a331_maxCurrent m331 : 24|7@1+ (0.25,0) [0|0] "" Vector__XXX
 SG_ VCRIGHT_a360_accelVar m360 : 24|10@1+ (0.0002,0) [0|0] "" Vector__XXX
 SG_ VCRIGHT_a444_channel m444 : 24|8@1+ (1,0) [0|0] "" Vector__XXX
 SG_ VCRIGHT_a445_expectedMSB m445 : 24|8@1+ (1,0) [0|0] "" Vector__XXX
 SG_ VCRIGHT_a448_manFreshComfortHeatAutoHVACIntvn m448 : 24|1@1+ (1,0) [0|0] "" Vector__XXX
 SG_ VCRIGHT_a482_overTempShutdown m482 : 24|1@1+ (1,0) [0|0] "" Vector__XXX
 SG_ VCRIGHT_a499_localEpbmStatus m499 : 24|5@1+ (1,0) [0|0] "" Vector__XXX
 SG_ VCRIGHT_a525_initialLVBatteryType m525 : 24|3@1+ (1,0) [0|0] "" Vector__XXX
 SG_ VCRIGHT_a526_pcbaTemperature m526 : 24|16@1- (0.125,55) [0|0] "" Vector__XXX
 SG_ VCRIGHT_a533_thsLINSchedule m533 : 24|3@1+ (1,0) [0|0] "" Vector__XXX
 SG_ VCRIGHT_a538_heatPumpModeNotAttainable m538 : 24|1@1+ (1,0) [0|0] "" Vector__XXX
 SG_ VCRIGHT_a540_LHBleedDBGDitherErrToTarget m540 : 24|5@1+ (1,0) [0|0] "" Vector__XXX
 SG_ VCRIGHT_a545_frunkOpen m545 : 24|1@1+ (1,0) [0|0] "" Vector__XXX
 SG_ VCRIGHT_a546_mirrorMaxFoldCurrent m546 : 24|7@1- (0.05,0) [0|0] "" Vector__XXX
 SG_ VCRIGHT_a551_interiorReleaseReqCountFront m551 : 24|8@1+ (1,0) [0|0] "" Vector__XXX
 SG_ VCRIGHT_a589_cabinTempSensor m589 : 24|1@1+ (1,0) [0|0] "" Vector__XXX
 SG_ VCRIGHT_a599_initialLVBatteryType m599 : 24|3@1+ (1,0) [0|0] "" Vector__XXX
 SG_ VCRIGHT_a021_Task1000msLate m21 : 25|1@1+ (1,0) [0|0] "" Vector__XXX
 SG_ VCRIGHT_a089_VEH_party3 m89 : 25|1@1+ (1,0) [0|0] "" Vector__XXX
 SG_ VCRIGHT_a098_PARTY_torque m98 : 25|1@1+ (1,0) [0|0] "" Vector__XXX
 SG_ VCRIGHT_a104_PARTY_bodyControls m104 : 25|1@1+ (1,0) [0|0] "" Vector__XXX
 SG_ VCRIGHT_a107_PT_socStatus m107 : 25|1@1+ (1,0) [0|0] "" Vector__XXX
 SG_ VCRIGHT_a108_PT_temperature m108 : 25|1@1+ (1,0) [0|0] "" Vector__XXX
 SG_ VCRIGHT_a109_BDY_inertial2 m109 : 25|1@1+ (1,0) [0|0] "" Vector__XXX
 SG_ VCRIGHT_a110_VEH_canLogAvailability m110 : 25|1@1+ (1,0) [0|0] "" Vector__XXX
 SG_ VCRIGHT_a111_VEH_seatStatus m111 : 25|1@1+ (1,0) [0|0] "" Vector__XXX
 SG_ VCRIGHT_a112_PARTY_status m112 : 25|1@1+ (1,0) [0|0] "" Vector__XXX
 SG_ VCRIGHT_a113_VEH_chassisControl m113 : 25|1@1+ (1,0) [0|0] "" Vector__XXX
 SG_ VCRIGHT_a114_VEH_wheelRotation m114 : 25|1@1+ (1,0) [0|0] "" Vector__XXX
 SG_ VCRIGHT_a115_VEH_authenticationWithMac m115 : 25|1@1+ (1,0) [0|0] "" Vector__XXX
 SG_ VCRIGHT_a116_VEH_seatHeatStatus m116 : 25|1@1+ (1,0) [0|0] "" Vector__XXX
 SG_ VCRIGHT_a117_VEH_seatStatus m117 : 25|1@1+ (1,0) [0|0] "" Vector__XXX
 SG_ VCRIGHT_a118_VEH_systemStatus m118 : 25|1@1+ (1,0) [0|0] "" Vector__XXX
 SG_ VCRIGHT_a120_PARTY_status m120 : 25|1@1+ (1,0) [0|0] "" Vector__XXX
 SG_ VCRIGHT_a150_movementTimeMs m150 : 25|7@1+ (50,0) [0|0] "" Vector__XXX
 SG_ VCRIGHT_a151_movementTimeMs m151 : 25|7@1+ (50,0) [0|0] "" Vector__XXX
 SG_ VCRIGHT_a166_JUST_CALIBRATED m166 : 25|1@1+ (1,0) [0|0] "" Vector__XXX
 SG_ VCRIGHT_a173_doorOpenTimeMs m173 : 25|7@1+ (500,0) [0|0] "" Vector__XXX
 SG_ VCRIGHT_a202_dynApplyAllowed m202 : 25|1@1+ (1,0) [0|0] "" Vector__XXX
 SG_ VCRIGHT_a203_dynApplyAllowed m203 : 25|1@1+ (1,0) [0|0] "" Vector__XXX
 SG_ VCRIGHT_a204_dynApplyAllowed m204 : 25|1@1+ (1,0) [0|0] "" Vector__XXX
 SG_ VCRIGHT_a205_dynApplyAllowed m205 : 25|1@1+ (1,0) [0|0] "" Vector__XXX
 SG_ VCRIGHT_a206_dynApplyAllowed m206 : 25|1@1+ (1,0) [0|0] "" Vector__XXX
 SG_ VCRIGHT_a207_dynApplyAllowed m207 : 25|1@1+ (1,0) [0|0] "" Vector__XXX
 SG_ VCRIGHT_a208_dynApplyAllowed m208 : 25|1@1+ (1,0) [0|0] "" Vector__XXX
 SG_ VCRIGHT_a209_dynApplyAllowed m209 : 25|1@1+ (1,0) [0|0] "" Vector__XXX
 SG_ VCRIGHT_a210_dynApplyAllowed m210 : 25|1@1+ (1,0) [0|0] "" Vector__XXX
 SG_ VCRIGHT_a211_dynApplyAllowed m211 : 25|1@1+ (1,0) [0|0] "" Vector__XXX
 SG_ VCRIGHT_a212_dynApplyAllowed m212 : 25|1@1+ (1,0) [0|0] "" Vector__XXX
 SG_ VCRIGHT_a213_dynApplyAllowed m213 : 25|1@1+ (1,0) [0|0] "" Vector__XXX
 SG_ VCRIGHT_a214_dynApplyAllowed m214 : 25|1@1+ (1,0) [0|0] "" Vector__XXX
 SG_ VCRIGHT_a262_LeftThermalShutIGBT m262 : 25|1@1+ (1,0) [0|0] "" Vector__XXX
 SG_ VCRIGHT_a286_voltage m286 : 25|7@1+ (0.15,0) [0|0] "" Vector__XXX
 SG_ VCRIGHT_a287_voltage m287 : 25|7@1+ (0.15,0) [0|0] "" Vector__XXX
 SG_ VCRIGHT_a310_foldingDirection m310 : 25|1@1+ (1,0) [0|0] "" Vector__XXX
 SG_ VCRIGHT_a343_batteryVoltage m343 : 25|7@1+ (0.15,0) [0|0] "" Vector__XXX
 SG_ VCRIGHT_a344_batteryVoltage m344 : 25|7@1+ (0.15,0) [0|0] "" Vector__XXX
 SG_ VCRIGHT_a448_manRecircRHAutoHVACIntvn m448 : 25|1@1+ (1,0) [0|0] "" Vector__XXX
 SG_ VCRIGHT_a482_thermalWarning m482 : 25|1@1+ (1,0) [0|0] "" Vector__XXX
 SG_ VCRIGHT_a538_thsVersionMismatch m538 : 25|1@1+ (1,0) [0|0] "" Vector__XXX
 SG_ VCRIGHT_a589_ambientTempSensor m589 : 25|1@1+ (1,0) [0|0] "" Vector__XXX
 SG_ VCRIGHT_a021_Task1000msStarved m21 : 26|1@1+ (1,0) [0|0] "" Vector__XXX
 SG_ VCRIGHT_a098_PT_thermalControl m98 : 26|1@1+ (1,0) [0|0] "" Vector__XXX
 SG_ VCRIGHT_a104_PARTY_gpsAccuracies m104 : 26|1@1+ (1,0) [0|0] "" Vector__XXX
 SG_ VCRIGHT_a107_VEH_socStatus m107 : 26|1@1+ (1,0) [0|0] "" Vector__XXX
 SG_ VCRIGHT_a108_PT_thermalControl m108 : 26|1@1+ (1,0) [0|0] "" Vector__XXX
 SG_ VCRIGHT_a109_BDY_status m109 : 26|1@1+ (1,0) [0|0] "" Vector__XXX
 SG_ VCRIGHT_a110_CH_airbagCutoffStatus m110 : 26|1@1+ (1,0) [0|0] "" Vector__XXX
 SG_ VCRIGHT_a111_PARTY_status m111 : 26|1@1+ (1,0) [0|0] "" Vector__XXX
 SG_ VCRIGHT_a112_CH_status m112 : 26|1@1+ (1,0) [0|0] "" Vector__XXX
 SG_ VCRIGHT_a113_VEH_trackModeSettings m113 : 26|1@1+ (1,0) [0|0] "" Vector__XXX
 SG_ VCRIGHT_a114_PARTY_brakeTorque m114 : 26|1@1+ (1,0) [0|0] "" Vector__XXX
 SG_ VCRIGHT_a115_VEH_endpointTemp m115 : 26|1@1+ (1,0) [0|0] "" Vector__XXX
 SG_ VCRIGHT_a116_VEH_restraintStatus m116 : 26|1@1+ (1,0) [0|0] "" Vector__XXX
 SG_ VCRIGHT_a117_BDY_falconSwitchStatus m117 : 26|1@1+ (1,0) [0|0] "" Vector__XXX
 SG_ VCRIGHT_a118_PARTY_LVPowerState m118 : 26|1@1+ (1,0) [0|0] "" Vector__XXX
 SG_ VCRIGHT_a120_PT_speed m120 : 26|1@1+ (1,0) [0|0] "" Vector__XXX
 SG_ VCRIGHT_a166_POWER_AT_SEAL m166 : 26|1@1+ (1,0) [0|0] "" Vector__XXX
 SG_ VCRIGHT_a202_releaseAllowed m202 : 26|1@1+ (1,0) [0|0] "" Vector__XXX
 SG_ VCRIGHT_a203_releaseAllowed m203 : 26|1@1+ (1,0) [0|0] "" Vector__XXX
 SG_ VCRIGHT_a204_releaseAllowed m204 : 26|1@1+ (1,0) [0|0] "" Vector__XXX
 SG_ VCRIGHT_a205_releaseAllowed m205 : 26|1@1+ (1,0) [0|0] "" Vector__XXX
 SG_ VCRIGHT_a206_releaseAllowed m206 : 26|1@1+ (1,0) [0|0] "" Vector__XXX
 SG_ VCRIGHT_a207_releaseAllowed m207 : 26|1@1+ (1,0) [0|0] "" Vector__XXX
 SG_ VCRIGHT_a208_releaseAllowed m208 : 26|1@1+ (1,0) [0|0] "" Vector__XXX
 SG_ VCRIGHT_a209_releaseAllowed m209 : 26|1@1+ (1,0) [0|0] "" Vector__XXX
 SG_ VCRIGHT_a210_releaseAllowed m210 : 26|1@1+ (1,0) [0|0] "" Vector__XXX
 SG_ VCRIGHT_a211_releaseAllowed m211 : 26|1@1+ (1,0) [0|0] "" Vector__XXX
 SG_ VCRIGHT_a212_releaseAllowed m212 : 26|1@1+ (1,0) [0|0] "" Vector__XXX
 SG_ VCRIGHT_a213_releaseAllowed m213 : 26|1@1+ (1,0) [0|0] "" Vector__XXX
 SG_ VCRIGHT_a214_releaseAllowed m214 : 26|1@1+ (1,0) [0|0] "" Vector__XXX
 SG_ VCRIGHT_a262_RightThermalShutIGBT m262 : 26|1@1+ (1,0) [0|0] "" Vector__XXX
 SG_ VCRIGHT_a352_maxCurrent m352 : 26|8@1+ (0.1,0) [0|0] "" Vector__XXX
 SG_ VCRIGHT_a448_manRecircFlashFogGenericHVACIntvn m448 : 26|1@1+ (1,0) [0|0] "" Vector__XXX
 SG_ VCRIGHT_a482_underOrOverVoltageOrOverCurrent m482 : 26|1@1+ (1,0) [0|0] "" Vector__XXX
 SG_ VCRIGHT_a538_thsMia m538 : 26|1@1+ (1,0) [0|0] "" Vector__XXX
 SG_ VCRIGHT_a589_THS m589 : 26|1@1+ (1,0) [0|0] "" Vector__XXX
 SG_ VCRIGHT_a021_Task1000msMissed m21 : 27|1@1+ (1,0) [0|0] "" Vector__XXX
 SG_ VCRIGHT_a098_PT_temperature m98 : 27|1@1+ (1,0) [0|0] "" Vector__XXX
 SG_ VCRIGHT_a104_CH_status m104 : 27|1@1+ (1,0) [0|0] "" Vector__XXX
 SG_ VCRIGHT_a107_VEH_packConfig m107 : 27|1@1+ (1,0) [0|0] "" Vector__XXX
 SG_ VCRIGHT_a108_PARTY_motorStatus m108 : 27|1@1+ (1,0) [0|0] "" Vector__XXX
 SG_ VCRIGHT_a109_VEH_inertial1 m109 : 27|1@1+ (1,0) [0|0] "" Vector__XXX
 SG_ VCRIGHT_a110_CH_carConfig m110 : 27|1@1+ (1,0) [0|0] "" Vector__XXX
 SG_ VCRIGHT_a111_CH_status m111 : 27|1@1+ (1,0) [0|0] "" Vector__XXX
 SG_ VCRIGHT_a113_VEH_powertrainControl m113 : 27|1@1+ (1,0) [0|0] "" Vector__XXX
 SG_ VCRIGHT_a114_PARTY_offsets m114 : 27|1@1+ (1,0) [0|0] "" Vector__XXX
 SG_ VCRIGHT_a115_VEH_ChildSeatStatus m115 : 27|1@1+ (1,0) [0|0] "" Vector__XXX
 SG_ VCRIGHT_a116_VEH_switchStatus m116 : 27|1@1+ (1,0) [0|0] "" Vector__XXX
 SG_ VCRIGHT_a117_VEH_doorStatus m117 : 27|1@1+ (1,0) [0|0] "" Vector__XXX
 SG_ VCRIGHT_a118_PARTY_outputPowerStatus m118 : 27|1@1+ (1,0) [0|0] "" Vector__XXX
 SG_ VCRIGHT_a120_PT_systemStatus m120 : 27|1@1+ (1,0) [0|0] "" Vector__XXX
 SG_ VCRIGHT_a166_UNDERCURRENT m166 : 27|1@1+ (1,0) [0|0] "" Vector__XXX
 SG_ VCRIGHT_a202_parkPendingAllowed m202 : 27|1@1+ (1,0) [0|0] "" Vector__XXX
 SG_ VCRIGHT_a203_parkPendingAllowed m203 : 27|1@1+ (1,0) [0|0] "" Vector__XXX
 SG_ VCRIGHT_a204_parkPendingAllowed m204 : 27|1@1+ (1,0) [0|0] "" Vector__XXX
 SG_ VCRIGHT_a205_parkPendingAllowed m205 : 27|1@1+ (1,0) [0|0] "" Vector__XXX
 SG_ VCRIGHT_a206_parkPendingAllowed m206 : 27|1@1+ (1,0) [0|0] "" Vector__XXX
 SG_ VCRIGHT_a207_parkPendingAllowed m207 : 27|1@1+ (1,0) [0|0] "" Vector__XXX
 SG_ VCRIGHT_a208_parkPendingAllowed m208 : 27|1@1+ (1,0) [0|0] "" Vector__XXX
 SG_ VCRIGHT_a209_parkPendingAllowed m209 : 27|1@1+ (1,0) [0|0] "" Vector__XXX
 SG_ VCRIGHT_a210_parkPendingAllowed m210 : 27|1@1+ (1,0) [0|0] "" Vector__XXX
 SG_ VCRIGHT_a211_parkPendingAllowed m211 : 27|1@1+ (1,0) [0|0] "" Vector__XXX
 SG_ VCRIGHT_a212_parkPendingAllowed m212 : 27|1@1+ (1,0) [0|0] "" Vector__XXX
 SG_ VCRIGHT_a213_parkPendingAllowed m213 : 27|1@1+ (1,0) [0|0] "" Vector__XXX
 SG_ VCRIGHT_a214_parkPendingAllowed m214 : 27|1@1+ (1,0) [0|0] "" Vector__XXX
 SG_ VCRIGHT_a262_CANTimeout m262 : 27|1@1+ (1,0) [0|0] "" Vector__XXX
 SG_ VCRIGHT_a448_manRecircFlashFogWetAirHVACIntvn m448 : 27|1@1+ (1,0) [0|0] "" Vector__XXX
 SG_ VCRIGHT_a450_tempDuctRight m450 : 27|8@1+ (0.5,-22) [0|0] "" Vector__XXX
 SG_ VCRIGHT_a482_underloadDetected m482 : 27|1@1+ (1,0) [0|0] "" Vector__XXX
 SG_ VCRIGHT_a525_serviceMode m525 : 27|1@1+ (1,0) [0|0] "" Vector__XXX
 SG_ VCRIGHT_a538_hvOn m538 : 27|1@1+ (1,0) [0|0] "" Vector__XXX
 SG_ VCRIGHT_a589_evapTempSensor m589 : 27|1@1+ (1,0) [0|0] "" Vector__XXX
 SG_ VCRIGHT_a599_serviceMode m599 : 27|1@1+ (1,0) [0|0] "" Vector__XXX
 SG_ VCRIGHT_a058_current m58 : 28|11@1+ (0.1,0) [0|0] "" Vector__XXX
 SG_ VCRIGHT_a059_resistanceEstimate m59 : 28|12@1+ (0.00244,0) [0|0] "" Vector__XXX
 SG_ VCRIGHT_a098_PARTY_motorStatus m98 : 28|1@1+ (1,0) [0|0] "" Vector__XXX
 SG_ VCRIGHT_a104_PARTY_status m104 : 28|1@1+ (1,0) [0|0] "" Vector__XXX
 SG_ VCRIGHT_a107_VEH_energyStatus m107 : 28|1@1+ (1,0) [0|0] "" Vector__XXX
 SG_ VCRIGHT_a108_VEH_motorStatus m108 : 28|1@1+ (1,0) [0|0] "" Vector__XXX
 SG_ VCRIGHT_a109_VEH_inertial2 m109 : 28|1@1+ (1,0) [0|0] "" Vector__XXX
 SG_ VCRIGHT_a110_CH_carState m110 : 28|1@1+ (1,0) [0|0] "" Vector__XXX
 SG_ VCRIGHT_a113_VEH_vehicleModes m113 : 28|1@1+ (1,0) [0|0] "" Vector__XXX
 SG_ VCRIGHT_a114_BDY_offsets m114 : 28|1@1+ (1,0) [0|0] "" Vector__XXX
 SG_ VCRIGHT_a115_BDY_ChildSeatStatus m115 : 28|1@1+ (1,0) [0|0] "" Vector__XXX
 SG_ VCRIGHT_a116_VEH_logging1Hz m116 : 28|1@1+ (1,0) [0|0] "" Vector__XXX
 SG_ VCRIGHT_a117_VEH_doorStatus2 m117 : 28|1@1+ (1,0) [0|0] "" Vector__XXX
 SG_ VCRIGHT_a118_PARTY_vehicleTime m118 : 28|1@1+ (1,0) [0|0] "" Vector__XXX
 SG_ VCRIGHT_a120_PARTY_vehicleEstimates m120 : 28|1@1+ (1,0) [0|0] "" Vector__XXX
 SG_ VCRIGHT_a166_ENCODER_STALL m166 : 28|1@1+ (1,0) [0|0] "" Vector__XXX
 SG_ VCRIGHT_a202_wenchPendingAllowed m202 : 28|1@1+ (1,0) [0|0] "" Vector__XXX
 SG_ VCRIGHT_a203_wenchPendingAllowed m203 : 28|1@1+ (1,0) [0|0] "" Vector__XXX
 SG_ VCRIGHT_a204_wenchPendingAllowed m204 : 28|1@1+ (1,0) [0|0] "" Vector__XXX
 SG_ VCRIGHT_a205_wenchPendingAllowed m205 : 28|1@1+ (1,0) [0|0] "" Vector__XXX
 SG_ VCRIGHT_a206_wenchPendingAllowed m206 : 28|1@1+ (1,0) [0|0] "" Vector__XXX
 SG_ VCRIGHT_a207_wenchPendingAllowed m207 : 28|1@1+ (1,0) [0|0] "" Vector__XXX
 SG_ VCRIGHT_a208_wenchPendingAllowed m208 : 28|1@1+ (1,0) [0|0] "" Vector__XXX
 SG_ VCRIGHT_a209_wenchPendingAllowed m209 : 28|1@1+ (1,0) [0|0] "" Vector__XXX
 SG_ VCRIGHT_a210_wenchPendingAllowed m210 : 28|1@1+ (1,0) [0|0] "" Vector__XXX
 SG_ VCRIGHT_a211_wenchPendingAllowed m211 : 28|1@1+ (1,0) [0|0] "" Vector__XXX
 SG_ VCRIGHT_a212_wenchPendingAllowed m212 : 28|1@1+ (1,0) [0|0] "" Vector__XXX
 SG_ VCRIGHT_a213_wenchPendingAllowed m213 : 28|1@1+ (1,0) [0|0] "" Vector__XXX
 SG_ VCRIGHT_a214_wenchPendingAllowed m214 : 28|1@1+ (1,0) [0|0] "" Vector__XXX
 SG_ VCRIGHT_a232_seatMotorPosReal m232 : 28|12@1- (1,0) [0|0] "" Vector__XXX
 SG_ VCRIGHT_a233_seatMotorPosReal m233 : 28|12@1- (1,0) [0|0] "" Vector__XXX
 SG_ VCRIGHT_a234_seatMotorPosReal m234 : 28|12@1- (1,0) [0|0] "" Vector__XXX
 SG_ VCRIGHT_a235_seatMotorPosReal m235 : 28|12@1- (1,0) [0|0] "" Vector__XXX
 SG_ VCRIGHT_a239_seatHeatTmp m239 : 28|12@1- (0.05,0) [0|0] "" Vector__XXX
 SG_ VCRIGHT_a240_seatHeatTmp m240 : 28|12@1- (0.05,0) [0|0] "" Vector__XXX
 SG_ VCRIGHT_a241_seatHeatTmp m241 : 28|12@1- (0.05,0) [0|0] "" Vector__XXX
 SG_ VCRIGHT_a242_seatHeatTmp m242 : 28|12@1- (0.05,0) [0|0] "" Vector__XXX
 SG_ VCRIGHT_a243_seatHeatTmp m243 : 28|12@1- (0.05,0) [0|0] "" Vector__XXX
 SG_ VCRIGHT_a244_seatHeatTmp m244 : 28|12@1- (0.05,0) [0|0] "" Vector__XXX
 SG_ VCRIGHT_a245_seatHeatTmp m245 : 28|12@1- (0.05,0) [0|0] "" Vector__XXX
 SG_ VCRIGHT_a246_seatHeatTmp m246 : 28|12@1- (0.05,0) [0|0] "" Vector__XXX
 SG_ VCRIGHT_a247_seatHeatTmp m247 : 28|12@1- (0.05,0) [0|0] "" Vector__XXX
 SG_ VCRIGHT_a248_seatHeatTmp m248 : 28|12@1- (0.05,0) [0|0] "" Vector__XXX
 SG_ VCRIGHT_a249_seatHeatTmp m249 : 28|12@1- (0.05,0) [0|0] "" Vector__XXX
 SG_ VCRIGHT_a250_seatHeatTmp m250 : 28|12@1- (0.05,0) [0|0] "" Vector__XXX
 SG_ VCRIGHT_a251_seatMotorPosReal m251 : 28|12@1- (1,0) [0|0] "" Vector__XXX
 SG_ VCRIGHT_a252_seatMotorPosReal m252 : 28|12@1- (1,0) [0|0] "" Vector__XXX
 SG_ VCRIGHT_a253_seatMotorPosReal m253 : 28|12@1- (1,0) [0|0] "" Vector__XXX
 SG_ VCRIGHT_a254_seatMotorPosReal m254 : 28|12@1- (1,0) [0|0] "" Vector__XXX
 SG_ VCRIGHT_a262_LowVoltageSensor m262 : 28|1@1+ (1,0) [0|0] "" Vector__XXX
 SG_ VCRIGHT_a263_seatMotorDCurrent m263 : 28|12@1- (0.01,0) [0|0] "" Vector__XXX
 SG_ VCRIGHT_a264_seatMotorDCurrent m264 : 28|12@1- (0.01,0) [0|0] "" Vector__XXX
 SG_ VCRIGHT_a265_seatMotorDCurrent m265 : 28|12@1- (0.01,0) [0|0] "" Vector__XXX
 SG_ VCRIGHT_a266_seatMotorDCurrent m266 : 28|12@1- (0.01,0) [0|0] "" Vector__XXX
 SG_ VCRIGHT_a267_seatMotorDCurrent m267 : 28|12@1- (0.01,0) [0|0] "" Vector__XXX
 SG_ VCRIGHT_a268_seatMotorDCurrent m268 : 28|12@1- (0.01,0) [0|0] "" Vector__XXX
 SG_ VCRIGHT_a269_seatMotorDCurrent m269 : 28|12@1- (0.01,0) [0|0] "" Vector__XXX
 SG_ VCRIGHT_a270_seatMotorDCurrent m270 : 28|12@1- (0.01,0) [0|0] "" Vector__XXX
 SG_ VCRIGHT_a291_railVoltage m291 : 28|12@1+ (0.01,0) [0|0] "" Vector__XXX
 SG_ VCRIGHT_a292_railV m292 : 28|12@1- (0.01,0) [0|0] "" Vector__XXX
 SG_ VCRIGHT_a293_railV m293 : 28|12@1- (0.01,0) [0|0] "" Vector__XXX
 SG_ VCRIGHT_a298_railV m298 : 28|12@1- (0.01,0) [0|0] "" Vector__XXX
 SG_ VCRIGHT_a299_railV m299 : 28|12@1- (0.01,0) [0|0] "" Vector__XXX
 SG_ VCRIGHT_a323_calibrationRight m323 : 28|12@1+ (0.002,0) [0|0] "" Vector__XXX
 SG_ VCRIGHT_a376_2RowSeatTrackActuatorDuty m376 : 28|12@1- (0.1,0) [0|0] "" Vector__XXX
 SG_ VCRIGHT_a448_manRecircRHManualHVACNudge m448 : 28|1@1+ (1,0) [0|0] "" Vector__XXX
 SG_ VCRIGHT_a525_factoryGated m525 : 28|1@1+ (1,0) [0|0] "" Vector__XXX
 SG_ VCRIGHT_a538_hvacPowerOn m538 : 28|1@1+ (1,0) [0|0] "" Vector__XXX
 SG_ VCRIGHT_a570_seatHeatTmp m570 : 28|12@1- (0.05,0) [0|0] "" Vector__XXX
 SG_ VCRIGHT_a571_seatHeatTmp m571 : 28|12@1- (0.05,0) [0|0] "" Vector__XXX
 SG_ VCRIGHT_a572_seatHeatTmp m572 : 28|12@1- (0.05,0) [0|0] "" Vector__XXX
 SG_ VCRIGHT_a573_seatHeatTmp m573 : 28|12@1- (0.05,0) [0|0] "" Vector__XXX
 SG_ VCRIGHT_a589_defrostTempSensor m589 : 28|1@1+ (1,0) [0|0] "" Vector__XXX
 SG_ VCRIGHT_a599_factoryGated m599 : 28|1@1+ (1,0) [0|0] "" Vector__XXX
 SG_ VCRIGHT_a098_VEH_motorStatus m98 : 29|1@1+ (1,0) [0|0] "" Vector__XXX
 SG_ VCRIGHT_a104_PARTY_steeringControl m104 : 29|1@1+ (1,0) [0|0] "" Vector__XXX
 SG_ VCRIGHT_a107_VEH_chargeInfo m107 : 29|1@1+ (1,0) [0|0] "" Vector__XXX
 SG_ VCRIGHT_a108_CH_torque m108 : 29|1@1+ (1,0) [0|0] "" Vector__XXX
 SG_ VCRIGHT_a109_CH_inertial1 m109 : 29|1@1+ (1,0) [0|0] "" Vector__XXX
 SG_ VCRIGHT_a110_CH_vin m110 : 29|1@1+ (1,0) [0|0] "" Vector__XXX
 SG_ VCRIGHT_a113_VEH_driverProfileRecall m113 : 29|1@1+ (1,0) [0|0] "" Vector__XXX
 SG_ VCRIGHT_a114_BDY_party3 m114 : 29|1@1+ (1,0) [0|0] "" Vector__XXX
 SG_ VCRIGHT_a116_VEH_seatStatus2 m116 : 29|1@1+ (1,0) [0|0] "" Vector__XXX
 SG_ VCRIGHT_a117_VEH_windowStatus m117 : 29|1@1+ (1,0) [0|0] "" Vector__XXX
 SG_ VCRIGHT_a118_VEH_thermalCommand m118 : 29|1@1+ (1,0) [0|0] "" Vector__XXX
 SG_ VCRIGHT_a120_VEH_aggregatedAxleSpeed m120 : 29|1@1+ (1,0) [0|0] "" Vector__XXX
 SG_ VCRIGHT_a166_PINCH_V1 m166 : 29|1@1+ (1,0) [0|0] "" Vector__XXX
 SG_ VCRIGHT_a224_seatMotorState m224 : 29|3@1+ (1,0) [0|0] "" Vector__XXX
 SG_ VCRIGHT_a225_seatMotorState m225 : 29|3@1+ (1,0) [0|0] "" Vector__XXX
 SG_ VCRIGHT_a226_seatMotorState m226 : 29|3@1+ (1,0) [0|0] "" Vector__XXX
 SG_ VCRIGHT_a227_seatMotorState m227 : 29|3@1+ (1,0) [0|0] "" Vector__XXX
 SG_ VCRIGHT_a262_HighVoltageSensor m262 : 29|1@1+ (1,0) [0|0] "" Vector__XXX
 SG_ VCRIGHT_a448_manACoffRHManualHVACNudge m448 : 29|1@1+ (1,0) [0|0] "" Vector__XXX
 SG_ VCRIGHT_a525_frunkOpen m525 : 29|1@1+ (1,0) [0|0] "" Vector__XXX
 SG_ VCRIGHT_a538_limpMode m538 : 29|1@1+ (1,0) [0|0] "" Vector__XXX
 SG_ VCRIGHT_a540_RHVaneDebugDither m540 : 29|1@1+ (1,0) [0|0] "" Vector__XXX
 SG_ VCRIGHT_a589_cabinModel m589 : 29|1@1+ (1,0) [0|0] "" Vector__XXX
 SG_ VCRIGHT_a599_frunkOpen m599 : 29|1@1+ (1,0) [0|0] "" Vector__XXX
 SG_ VCRIGHT_a104_CH_steeringControl m104 : 30|1@1+ (1,0) [0|0] "" Vector__XXX
 SG_ VCRIGHT_a109_CH_inertial2 m109 : 30|1@1+ (1,0) [0|0] "" Vector__XXX
 SG_ VCRIGHT_a110_CH_chNm m110 : 30|1@1+ (1,0) [0|0] "" Vector__XXX
 SG_ VCRIGHT_a113_VEH_driverProfileRecall2 m113 : 30|1@1+ (1,0) [0|0] "" Vector__XXX
 SG_ VCRIGHT_a114_BDY_status m114 : 30|1@1+ (1,0) [0|0] "" Vector__XXX
 SG_ VCRIGHT_a116_VEH_status m116 : 30|1@1+ (1,0) [0|0] "" Vector__XXX
 SG_ VCRIGHT_a117_VEH_switchStatus m117 : 30|1@1+ (1,0) [0|0] "" Vector__XXX
 SG_ VCRIGHT_a118_CH_LVPowerState m118 : 30|1@1+ (1,0) [0|0] "" Vector__XXX
 SG_ VCRIGHT_a120_PARTY_aggregatedAxleSpeed m120 : 30|1@1+ (1,0) [0|0] "" Vector__XXX
 SG_ VCRIGHT_a166_PINCH_DEBUG m166 : 30|1@1+ (1,0) [0|0] "" Vector__XXX
 SG_ VCRIGHT_a262_LeftCurrentHVSensor m262 : 30|1@1+ (1,0) [0|0] "" Vector__XXX
 SG_ VCRIGHT_a448_manHvacOffAutoSteerFogIntvn m448 : 30|1@1+ (1,0) [0|0] "" Vector__XXX
 SG_ VCRIGHT_a104_VEH_steeringControl m104 : 31|1@1+ (1,0) [0|0] "" Vector__XXX
 SG_ VCRIGHT_a109_CH_status m109 : 31|1@1+ (1,0) [0|0] "" Vector__XXX
 SG_ VCRIGHT_a110_CH_epochTimeGtw m110 : 31|1@1+ (1,0) [0|0] "" Vector__XXX
 SG_ VCRIGHT_a113_VEH_ventCntlReg m113 : 31|1@1+ (1,0) [0|0] "" Vector__XXX
 SG_ VCRIGHT_a114_BDY_wheelRotation m114 : 31|1@1+ (1,0) [0|0] "" Vector__XXX
 SG_ VCRIGHT_a116_VEH_thermalCommand m116 : 31|1@1+ (1,0) [0|0] "" Vector__XXX
 SG_ VCRIGHT_a117_VEH_intrusionSensorStatus m117 : 31|1@1+ (1,0) [0|0] "" Vector__XXX
 SG_ VCRIGHT_a118_PARTY_sensors m118 : 31|1@1+ (1,0) [0|0] "" Vector__XXX
 SG_ VCRIGHT_a120_VEH_systemPower m120 : 31|1@1+ (1,0) [0|0] "" Vector__XXX
 SG_ VCRIGHT_a166_STATE_TIMEOUT m166 : 31|1@1+ (1,0) [0|0] "" Vector__XXX
 SG_ VCRIGHT_a262_RightCurrentHVSensor m262 : 31|1@1+ (1,0) [0|0] "" Vector__XXX
 SG_ VCRIGHT_a361_angleVar m361 : 31|17@1+ (1e-05,0) [0|0] "" Vector__XXX
 SG_ VCRIGHT_a448_manHvacOffAutoSteerFogNudge m448 : 31|1@1+ (1,0) [0|0] "" Vector__XXX
 SG_ VCRIGHT_a000_alertDataW1 m0 : 32|16@1+ (1,0) [0|0] "" Vector__XXX
 SG_ VCRIGHT_a003_LineNumber m3 : 32|16@1+ (1,0) [0|0] "" Vector__XXX
 SG_ VCRIGHT_a005_busID1 m5 : 32|4@1+ (1,0) [0|0] "" Vector__XXX
 SG_ VCRIGHT_a006_messageID m6 : 32|29@1+ (1,0) [0|0] "" Vector__XXX
 SG_ VCRIGHT_a016_NVMMRecordNotFound m16 : 32|1@1+ (1,0) [0|0] "" Vector__XXX
 SG_ VCRIGHT_a022_TaskInitError1 m22 : 32|8@1+ (1,0) [0|0] "" Vector__XXX
 SG_ VCRIGHT_a031_uds_bytes_2 m31 : 32|8@1+ (1,0) [0|0] "" Vector__XXX
 SG_ VCRIGHT_a041_CPULoad10msTask m41 : 32|8@1+ (1,0) [0|0] "" Vector__XXX
 SG_ VCRIGHT_a042_Usage100msTask m42 : 32|8@1+ (1,0) [0|0] "" Vector__XXX
 SG_ VCRIGHT_a063_ADCVoltage m63 : 32|8@1+ (0.025,0) [0|0] "" Vector__XXX
 SG_ VCRIGHT_a104_PARTY_integratedSafetyFront m104 : 32|1@1+ (1,0) [0|0] "" Vector__XXX
 SG_ VCRIGHT_a110_PARTY_carConfig m110 : 32|1@1+ (1,0) [0|0] "" Vector__XXX
 SG_ VCRIGHT_a113_VEH_debugECU m113 : 32|1@1+ (1,0) [0|0] "" Vector__XXX
 SG_ VCRIGHT_a114_BDY_wheelSpeeds m114 : 32|1@1+ (1,0) [0|0] "" Vector__XXX
 SG_ VCRIGHT_a116_VEH_windowStatus m116 : 32|1@1+ (1,0) [0|0] "" Vector__XXX
 SG_ VCRIGHT_a117_VEH_liftgateStatus m117 : 32|1@1+ (1,0) [0|0] "" Vector__XXX
 SG_ VCRIGHT_a118_CH_sensors m118 : 32|1@1+ (1,0) [0|0] "" Vector__XXX
 SG_ VCRIGHT_a120_PARTY_autonomyHealth m120 : 32|1@1+ (1,0) [0|0] "" Vector__XXX
 SG_ VCRIGHT_a126_intakeN0P1LS m126 : 32|1@1+ (1,0) [0|0] "" Vector__XXX
 SG_ VCRIGHT_a127_intakeN0P1LS m127 : 32|1@1+ (1,0) [0|0] "" Vector__XXX
 SG_ VCRIGHT_a128_IOSPIErr m128 : 32|1@1+ (1,0) [0|0] "" Vector__XXX
 SG_ VCRIGHT_a150_windowPinchReason m150 : 32|3@1+ (1,0) [0|0] "" Vector__XXX
 SG_ VCRIGHT_a151_windowPinchReason m151 : 32|3@1+ (1,0) [0|0] "" Vector__XXX
 SG_ VCRIGHT_a164_upMovementTimeMs m164 : 32|7@1+ (50,0) [0|0] "" Vector__XXX
 SG_ VCRIGHT_a165_sealZoneStartPos m165 : 32|8@1+ (1,0) [0|0] "" Vector__XXX
 SG_ VCRIGHT_a166_powerSealPos m166 : 32|11@1+ (1,0) [0|0] "" Vector__XXX
 SG_ VCRIGHT_a167_pinchVoltage m167 : 32|6@1+ (0.25,0) [0|0] "" Vector__XXX
 SG_ VCRIGHT_a168_pinchVoltage m168 : 32|6@1+ (0.25,0) [0|0] "" Vector__XXX
 SG_ VCRIGHT_a173_btnTimeMsDownLF m173 : 32|4@1+ (50,0) [0|0] "" Vector__XXX
 SG_ VCRIGHT_a175_lookbackIndex m175 : 32|6@1+ (1,0) [0|0] "" Vector__XXX
 SG_ VCRIGHT_a176_lookbackIndex m176 : 32|6@1+ (1,0) [0|0] "" Vector__XXX
 SG_ VCRIGHT_a180_extHandlePulled m180 : 32|1@1+ (1,0) [0|0] "" Vector__XXX
 SG_ VCRIGHT_a181_extHandlePulled m181 : 32|1@1+ (1,0) [0|0] "" Vector__XXX
 SG_ VCRIGHT_a184_trunkCurrent m184 : 32|8@1+ (0.05,0) [0|0] "" Vector__XXX
 SG_ VCRIGHT_a202_desyncCount m202 : 32|6@1+ (1,0) [0|0] "" Vector__XXX
 SG_ VCRIGHT_a203_desyncCount m203 : 32|6@1+ (1,0) [0|0] "" Vector__XXX
 SG_ VCRIGHT_a204_desyncCount m204 : 32|6@1+ (1,0) [0|0] "" Vector__XXX
 SG_ VCRIGHT_a205_desyncCount m205 : 32|6@1+ (1,0) [0|0] "" Vector__XXX
 SG_ VCRIGHT_a206_unitStatusEPB m206 : 32|5@1+ (1,0) [0|0] "" Vector__XXX
 SG_ VCRIGHT_a207_unitStatusEPB m207 : 32|5@1+ (1,0) [0|0] "" Vector__XXX
 SG_ VCRIGHT_a208_unitStatusEPB m208 : 32|5@1+ (1,0) [0|0] "" Vector__XXX
 SG_ VCRIGHT_a209_unitStatusEPB m209 : 32|5@1+ (1,0) [0|0] "" Vector__XXX
 SG_ VCRIGHT_a210_unitStatusEPB m210 : 32|5@1+ (1,0) [0|0] "" Vector__XXX
 SG_ VCRIGHT_a211_desyncCount m211 : 32|6@1+ (1,0) [0|0] "" Vector__XXX
 SG_ VCRIGHT_a212_desyncCount m212 : 32|6@1+ (1,0) [0|0] "" Vector__XXX
 SG_ VCRIGHT_a213_desyncCount m213 : 32|6@1+ (1,0) [0|0] "" Vector__XXX
 SG_ VCRIGHT_a214_desyncCount m214 : 32|6@1+ (1,0) [0|0] "" Vector__XXX
 SG_ VCRIGHT_a216_byte1 m216 : 32|8@1+ (1,0) [0|0] "" Vector__XXX
 SG_ VCRIGHT_a217_byte6 m217 : 32|8@1+ (1,0) [0|0] "" Vector__XXX
 SG_ VCRIGHT_a218_voltage m218 : 32|10@1+ (0.02,0) [0|0] "" Vector__XXX
 SG_ VCRIGHT_a219_dropoutCount m219 : 32|12@1+ (1,0) [0|0] "" Vector__XXX
 SG_ VCRIGHT_a224_seatSwitchBack m224 : 32|2@1+ (1,0) [0|0] "" Vector__XXX
 SG_ VCRIGHT_a225_seatSwitchBack m225 : 32|2@1+ (1,0) [0|0] "" Vector__XXX
 SG_ VCRIGHT_a226_seatSwitchBack m226 : 32|2@1+ (1,0) [0|0] "" Vector__XXX
 SG_ VCRIGHT_a227_seatSwitchBack m227 : 32|2@1+ (1,0) [0|0] "" Vector__XXX
 SG_ VCRIGHT_a228_seatMotorPosReal m228 : 32|12@1- (1,0) [0|0] "" Vector__XXX
 SG_ VCRIGHT_a229_seatMotorPosReal m229 : 32|12@1- (1,0) [0|0] "" Vector__XXX
 SG_ VCRIGHT_a230_seatMotorPosReal m230 : 32|12@1- (1,0) [0|0] "" Vector__XXX
 SG_ VCRIGHT_a231_seatMotorPosReal m231 : 32|12@1- (1,0) [0|0] "" Vector__XXX
 SG_ VCRIGHT_a236_lumbarBPressureHpa m236 : 32|16@1+ (1,0) [0|0] "" Vector__XXX
 SG_ VCRIGHT_a237_lumbarBPressureHpa m237 : 32|16@1+ (1,0) [0|0] "" Vector__XXX
 SG_ VCRIGHT_a238_lumbarBPressureHpa m238 : 32|16@1+ (1,0) [0|0] "" Vector__XXX
 SG_ VCRIGHT_a255_OCPTemp m255 : 32|8@1- (1,80) [0|0] "" Vector__XXX
 SG_ VCRIGHT_a259_temperature m259 : 32|8@1+ (0.5,-40) [0|0] "" Vector__XXX
 SG_ VCRIGHT_a260_temperature m260 : 32|8@1+ (0.5,-40) [0|0] "" Vector__XXX
 SG_ VCRIGHT_a262_LeftTempIGBT m262 : 32|1@1+ (1,0) [0|0] "" Vector__XXX
 SG_ VCRIGHT_a276_mirrorTiltYPosition m276 : 32|8@1+ (0.02,0) [0|0] "" Vector__XXX
 SG_ VCRIGHT_a284_cabinTempInterior m284 : 32|8@1+ (0.5,-40) [0|0] "" Vector__XXX
 SG_ VCRIGHT_a285_cabinTempInterior m285 : 32|8@1+ (0.5,-40) [0|0] "" Vector__XXX
 SG_ VCRIGHT_a286_encoderVoltage m286 : 32|6@1+ (0.15,0) [0|0] "" Vector__XXX
 SG_ VCRIGHT_a287_encoderVoltage m287 : 32|6@1+ (0.15,0) [0|0] "" Vector__XXX
 SG_ VCRIGHT_a290_railVoltage m290 : 32|12@1- (0.01,0) [0|0] "" Vector__XXX
 SG_ VCRIGHT_a294_railV m294 : 32|12@1- (0.01,0) [0|0] "" Vector__XXX
 SG_ VCRIGHT_a295_railV m295 : 32|12@1- (0.01,0) [0|0] "" Vector__XXX
 SG_ VCRIGHT_a296_railV m296 : 32|12@1- (0.01,0) [0|0] "" Vector__XXX
 SG_ VCRIGHT_a310_mirrorMaxFoldCurrent m310 : 32|7@1- (0.05,0) [0|0] "" Vector__XXX
 SG_ VCRIGHT_a316_maxCurrentAmps m316 : 32|12@1+ (0.01,0) [0|0] "" Vector__XXX
 SG_ VCRIGHT_a321_movementStartPosition m321 : 32|16@1- (1,0) [0|0] "" Vector__XXX
 SG_ VCRIGHT_a322_movementStartPosition m322 : 32|16@1- (1,0) [0|0] "" Vector__XXX
 SG_ VCRIGHT_a330_temperature m330 : 32|8@1+ (0.5,-40) [0|0] "" Vector__XXX
 SG_ VCRIGHT_a331_temperature m331 : 32|8@1+ (0.5,-40) [0|0] "" Vector__XXX
 SG_ VCRIGHT_a343_ambientTemperature m343 : 32|8@1+ (0.5,-40) [0|0] "" Vector__XXX
 SG_ VCRIGHT_a344_ambientTemperature m344 : 32|8@1+ (0.5,-40) [0|0] "" Vector__XXX
 SG_ VCRIGHT_a426_seatMotorPosReal m426 : 32|12@1- (1,0) [0|0] "" Vector__XXX
 SG_ VCRIGHT_a427_seatMotorPosReal m427 : 32|12@1- (1,0) [0|0] "" Vector__XXX
 SG_ VCRIGHT_a428_seatMotorPosReal m428 : 32|12@1- (1,0) [0|0] "" Vector__XXX
 SG_ VCRIGHT_a429_seatMotorPosReal m429 : 32|12@1- (1,0) [0|0] "" Vector__XXX
 SG_ VCRIGHT_a444_watchdog m444 : 32|1@1+ (1,0) [0|0] "" Vector__XXX
 SG_ VCRIGHT_a445_expectedLSB m445 : 32|8@1+ (1,0) [0|0] "" Vector__XXX
 SG_ VCRIGHT_a448_manHvacAutoSteerFogIntvn m448 : 32|1@1+ (1,0) [0|0] "" Vector__XXX
 SG_ VCRIGHT_a491_ambientTemperature m491 : 32|8@1+ (0.5,-40) [0|0] "" Vector__XXX
 SG_ VCRIGHT_a499_remoteEpbmStatus m499 : 32|5@1+ (1,0) [0|0] "" Vector__XXX
 SG_ VCRIGHT_a533_thsTimeOnSchedule m533 : 32|7@1+ (100,0) [0|0] "" Vector__XXX
 SG_ VCRIGHT_a540_RHVaneDBGDitherErrToTarget m540 : 32|5@1+ (1,0) [0|0] "" Vector__XXX
 SG_ VCRIGHT_a546_mirrorMaxFoldVoltage m546 : 32|8@1+ (0.0784313725490196,0) [0|0] "" Vector__XXX
 SG_ VCRIGHT_a550_pcbaTemperature m550 : 32|16@1- (0.125,55) [0|0] "" Vector__XXX
 SG_ VCRIGHT_a551_lastRequestSourceFront m551 : 32|3@1+ (1,0) [0|0] "" Vector__XXX
 SG_ VCRIGHT_a589_defrostingTime m589 : 32|5@1+ (1,0) [0|0] "" Vector__XXX
 SG_ VCRIGHT_a016_NVMMCRCMismatch m16 : 33|1@1+ (1,0) [0|0] "" Vector__XXX
 SG_ VCRIGHT_a104_PARTY_matrixBendAngleRequest m104 : 33|1@1+ (1,0) [0|0] "" Vector__XXX
 SG_ VCRIGHT_a113_VEH_status m113 : 33|1@1+ (1,0) [0|0] "" Vector__XXX
 SG_ VCRIGHT_a114_CH_party1 m114 : 33|1@1+ (1,0) [0|0] "" Vector__XXX
 SG_ VCRIGHT_a116_PARTY_restraintStatus m116 : 33|1@1+ (1,0) [0|0] "" Vector__XXX
 SG_ VCRIGHT_a117_VEH_seatStatus2 m117 : 33|1@1+ (1,0) [0|0] "" Vector__XXX
 SG_ VCRIGHT_a118_VEH_interNodeResistance m118 : 33|1@1+ (1,0) [0|0] "" Vector__XXX
 SG_ VCRIGHT_a120_VEH_autonomyHealth m120 : 33|1@1+ (1,0) [0|0] "" Vector__XXX
 SG_ VCRIGHT_a126_intakeN0P1HS m126 : 33|1@1+ (1,0) [0|0] "" Vector__XXX
 SG_ VCRIGHT_a127_intakeN0P1HS m127 : 33|1@1+ (1,0) [0|0] "" Vector__XXX
 SG_ VCRIGHT_a128_node0SPIError m128 : 33|1@1+ (1,0) [0|0] "" Vector__XXX
 SG_ VCRIGHT_a262_TempOCP m262 : 33|1@1+ (1,0) [0|0] "" Vector__XXX
 SG_ VCRIGHT_a444_gateDriver m444 : 33|1@1+ (1,0) [0|0] "" Vector__XXX
 SG_ VCRIGHT_a448_manHvacAutoSteerFogNudge m448 : 33|1@1+ (1,0) [0|0] "" Vector__XXX
 SG_ VCRIGHT_a016_NVMMVersionMismatch m16 : 34|1@1+ (1,0) [0|0] "" Vector__XXX
 SG_ VCRIGHT_a104_VEH_matrixHighBeamRequest m104 : 34|1@1+ (1,0) [0|0] "" Vector__XXX
 SG_ VCRIGHT_a113_VEH_elevationStatus m113 : 34|1@1+ (1,0) [0|0] "" Vector__XXX
 SG_ VCRIGHT_a114_CH_party3 m114 : 34|1@1+ (1,0) [0|0] "" Vector__XXX
 SG_ VCRIGHT_a116_PARTY_doorStatus m116 : 34|1@1+ (1,0) [0|0] "" Vector__XXX
 SG_ VCRIGHT_a117_PARTY_restraintStatus m117 : 34|1@1+ (1,0) [0|0] "" Vector__XXX
 SG_ VCRIGHT_a118_CH_lighting m118 : 34|1@1+ (1,0) [0|0] "" Vector__XXX
 SG_ VCRIGHT_a120_PT_systemPower m120 : 34|1@1+ (1,0) [0|0] "" Vector__XXX
 SG_ VCRIGHT_a126_intakeN0P2LS m126 : 34|1@1+ (1,0) [0|0] "" Vector__XXX
 SG_ VCRIGHT_a127_intakeN0P2LS m127 : 34|1@1+ (1,0) [0|0] "" Vector__XXX
 SG_ VCRIGHT_a128_node0LoadError m128 : 34|1@1+ (1,0) [0|0] "" Vector__XXX
 SG_ VCRIGHT_a224_seatSwitchForward m224 : 34|2@1+ (1,0) [0|0] "" Vector__XXX
 SG_ VCRIGHT_a225_seatSwitchForward m225 : 34|2@1+ (1,0) [0|0] "" Vector__XXX
 SG_ VCRIGHT_a226_seatSwitchForward m226 : 34|2@1+ (1,0) [0|0] "" Vector__XXX
 SG_ VCRIGHT_a227_seatSwitchForward m227 : 34|2@1+ (1,0) [0|0] "" Vector__XXX
 SG_ VCRIGHT_a262_RightTempIGBT m262 : 34|1@1+ (1,0) [0|0] "" Vector__XXX
 SG_ VCRIGHT_a352_prevFilteredCurrent m352 : 34|8@1+ (0.1,0) [0|0] "" Vector__XXX
 SG_ VCRIGHT_a360_angleVar m360 : 34|10@1+ (1e-05,0) [0|0] "" Vector__XXX
 SG_ VCRIGHT_a444_overcurrent m444 : 34|1@1+ (1,0) [0|0] "" Vector__XXX
 SG_ VCRIGHT_a448_manualHighBlowerSpeedAutoHVACIntvn m448 : 34|1@1+ (1,0) [0|0] "" Vector__XXX
 SG_ VCRIGHT_a016_NVMMRecordUpgraded m16 : 35|1@1+ (1,0) [0|0] "" Vector__XXX
 SG_ VCRIGHT_a104_VEH_summonCommand m104 : 35|1@1+ (1,0) [0|0] "" Vector__XXX
 SG_ VCRIGHT_a113_VEH_LVControl m113 : 35|1@1+ (1,0) [0|0] "" Vector__XXX
 SG_ VCRIGHT_a114_CH_status m114 : 35|1@1+ (1,0) [0|0] "" Vector__XXX
 SG_ VCRIGHT_a116_BDY_epbmStatus m116 : 35|1@1+ (1,0) [0|0] "" Vector__XXX
 SG_ VCRIGHT_a117_VEH_thermalStatus m117 : 35|1@1+ (1,0) [0|0] "" Vector__XXX
 SG_ VCRIGHT_a118_VEH_lightStatus m118 : 35|1@1+ (1,0) [0|0] "" Vector__XXX
 SG_ VCRIGHT_a120_PARTY_stalklessInterfaces m120 : 35|1@1+ (1,0) [0|0] "" Vector__XXX
 SG_ VCRIGHT_a126_intakeN0P2HS m126 : 35|1@1+ (1,0) [0|0] "" Vector__XXX
 SG_ VCRIGHT_a127_intakeN0P2HS m127 : 35|1@1+ (1,0) [0|0] "" Vector__XXX
 SG_ VCRIGHT_a128_node0UnderVoltage m128 : 35|1@1+ (1,0) [0|0] "" Vector__XXX
 SG_ VCRIGHT_a150_lookbackIndex m150 : 35|6@1+ (1,0) [0|0] "" Vector__XXX
 SG_ VCRIGHT_a151_lookbackIndex m151 : 35|6@1+ (1,0) [0|0] "" Vector__XXX
 SG_ VCRIGHT_a262_TempPCB m262 : 35|1@1+ (1,0) [0|0] "" Vector__XXX
 SG_ VCRIGHT_a444_supplyUndervoltage m444 : 35|1@1+ (1,0) [0|0] "" Vector__XXX
 SG_ VCRIGHT_a450_tempDuctLeftEst m450 : 35|8@1+ (0.5,-22) [0|0] "" Vector__XXX
 SG_ VCRIGHT_a551_restrictDoorReleaseSignalRear m551 : 35|1@1+ (1,0) [0|0] "" Vector__XXX
 SG_ VCRIGHT_a005_faults1 m5 : 36|12@1+ (1,0) [0|0] "" Vector__XXX
 SG_ VCRIGHT_a016_NVMMMemOverflow m16 : 36|1@1+ (1,0) [0|0] "" Vector__XXX
 SG_ VCRIGHT_a104_VEH_status m104 : 36|1@1+ (1,0) [0|0] "" Vector__XXX
 SG_ VCRIGHT_a113_CH_chassisControl m113 : 36|1@1+ (1,0) [0|0] "" Vector__XXX
 SG_ VCRIGHT_a116_BDY_restraintStatus m116 : 36|1@1+ (1,0) [0|0] "" Vector__XXX
 SG_ VCRIGHT_a117_PARTY_doorStatus m117 : 36|1@1+ (1,0) [0|0] "" Vector__XXX
 SG_ VCRIGHT_a118_PARTY_vehNm m118 : 36|1@1+ (1,0) [0|0] "" Vector__XXX
 SG_ VCRIGHT_a120_CH_speed m120 : 36|1@1+ (1,0) [0|0] "" Vector__XXX
 SG_ VCRIGHT_a126_leftVaneN0P3LS m126 : 36|1@1+ (1,0) [0|0] "" Vector__XXX
 SG_ VCRIGHT_a127_leftVaneN0P3LS m127 : 36|1@1+ (1,0) [0|0] "" Vector__XXX
 SG_ VCRIGHT_a128_node0OverVoltage m128 : 36|1@1+ (1,0) [0|0] "" Vector__XXX
 SG_ VCRIGHT_a173_btnTimeMsAutoDownLF m173 : 36|4@1+ (50,0) [0|0] "" Vector__XXX
 SG_ VCRIGHT_a262_LeftIGBTShort m262 : 36|1@1+ (1,0) [0|0] "" Vector__XXX
 SG_ VCRIGHT_a362_angleVar m362 : 36|20@1+ (1e-06,0) [0|0] "" Vector__XXX
 SG_ VCRIGHT_a444_cpUndervoltage m444 : 36|1@1+ (1,0) [0|0] "" Vector__XXX
 SG_ VCRIGHT_a016_NVMMWriteFailed m16 : 37|1@1+ (1,0) [0|0] "" Vector__XXX
 SG_ VCRIGHT_a104_CH_pscControl m104 : 37|1@1+ (1,0) [0|0] "" Vector__XXX
 SG_ VCRIGHT_a113_CH_powertrainControl m113 : 37|1@1+ (1,0) [0|0] "" Vector__XXX
 SG_ VCRIGHT_a116_BDY_switchStatus m116 : 37|1@1+ (1,0) [0|0] "" Vector__XXX
 SG_ VCRIGHT_a117_VEH_status m117 : 37|1@1+ (1,0) [0|0] "" Vector__XXX
 SG_ VCRIGHT_a118_CH_12VBatteryStatus m118 : 37|1@1+ (1,0) [0|0] "" Vector__XXX
 SG_ VCRIGHT_a120_VEH_estimatedBrakeTemp m120 : 37|1@1+ (1,0) [0|0] "" Vector__XXX
 SG_ VCRIGHT_a126_leftVaneN0P3HS m126 : 37|1@1+ (1,0) [0|0] "" Vector__XXX
 SG_ VCRIGHT_a127_leftVaneN0P3HS m127 : 37|1@1+ (1,0) [0|0] "" Vector__XXX
 SG_ VCRIGHT_a128_node0NotPowerOnReset m128 : 37|1@1+ (1,0) [0|0] "" Vector__XXX
 SG_ VCRIGHT_a262_RightIGBTShort m262 : 37|1@1+ (1,0) [0|0] "" Vector__XXX
 SG_ VCRIGHT_a444_overTempShutdown m444 : 37|1@1+ (1,0) [0|0] "" Vector__XXX
 SG_ VCRIGHT_a540_RHBleedDebugDither m540 : 37|1@1+ (1,0) [0|0] "" Vector__XXX
 SG_ VCRIGHT_a104_BDY_gpsAccuracies m104 : 38|1@1+ (1,0) [0|0] "" Vector__XXX
 SG_ VCRIGHT_a113_VEH_tripPlanning m113 : 38|1@1+ (1,0) [0|0] "" Vector__XXX
 SG_ VCRIGHT_a117_PARTY_prndStatus m117 : 38|1@1+ (1,0) [0|0] "" Vector__XXX
 SG_ VCRIGHT_a118_CH_LVBMS_statusHigh m118 : 38|1@1+ (1,0) [0|0] "" Vector__XXX
 SG_ VCRIGHT_a120_PARTY_prndControl m120 : 38|1@1+ (1,0) [0|0] "" Vector__XXX
 SG_ VCRIGHT_a126_leftVaneN0P4LS m126 : 38|1@1+ (1,0) [0|0] "" Vector__XXX
 SG_ VCRIGHT_a127_leftVaneN0P4LS m127 : 38|1@1+ (1,0) [0|0] "" Vector__XXX
 SG_ VCRIGHT_a128_node0ThermalShutdown m128 : 38|1@1+ (1,0) [0|0] "" Vector__XXX
 SG_ VCRIGHT_a167_powerDeriv2Accum m167 : 38|10@1+ (1,0) [0|0] "" Vector__XXX
 SG_ VCRIGHT_a168_powerDeriv2Accum m168 : 38|10@1+ (1,0) [0|0] "" Vector__XXX
 SG_ VCRIGHT_a175_absAccelTripped m175 : 38|1@1+ (1,0) [0|0] "" Vector__XXX
 SG_ VCRIGHT_a176_absAccelTripped m176 : 38|1@1+ (1,0) [0|0] "" Vector__XXX
 SG_ VCRIGHT_a202_current m202 : 38|10@1+ (0.05,0) [0|0] "" Vector__XXX
 SG_ VCRIGHT_a203_current m203 : 38|10@1+ (0.05,0) [0|0] "" Vector__XXX
 SG_ VCRIGHT_a204_current m204 : 38|10@1+ (0.05,0) [0|0] "" Vector__XXX
 SG_ VCRIGHT_a205_current m205 : 38|10@1+ (0.05,0) [0|0] "" Vector__XXX
 SG_ VCRIGHT_a211_current m211 : 38|10@1+ (0.05,0) [0|0] "" Vector__XXX
 SG_ VCRIGHT_a212_current m212 : 38|10@1+ (0.05,0) [0|0] "" Vector__XXX
 SG_ VCRIGHT_a213_current m213 : 38|10@1+ (0.05,0) [0|0] "" Vector__XXX
 SG_ VCRIGHT_a214_current m214 : 38|10@1+ (0.05,0) [0|0] "" Vector__XXX
 SG_ VCRIGHT_a262_IGBTDriverTemporary m262 : 38|1@1+ (1,0) [0|0] "" Vector__XXX
 SG_ VCRIGHT_a444_overTempWarning m444 : 38|1@1+ (1,0) [0|0] "" Vector__XXX
 SG_ VCRIGHT_a058_prevREstimate m58 : 39|12@1+ (0.00061,0) [0|0] "" Vector__XXX
 SG_ VCRIGHT_a066_maxConsecutiveShortPeriods m66 : 39|4@1+ (1,0) [0|0] "" Vector__XXX
 SG_ VCRIGHT_a104_BDY_control m104 : 39|1@1+ (1,0) [0|0] "" Vector__XXX
 SG_ VCRIGHT_a113_VEH_vehicleControl3 m113 : 39|1@1+ (1,0) [0|0] "" Vector__XXX
 SG_ VCRIGHT_a117_PARTY_lightingSecondary m117 : 39|1@1+ (1,0) [0|0] "" Vector__XXX
 SG_ VCRIGHT_a118_CH_alertMatrix m118 : 39|1@1+ (1,0) [0|0] "" Vector__XXX
 SG_ VCRIGHT_a120_PARTY_locStatus2 m120 : 39|1@1+ (1,0) [0|0] "" Vector__XXX
 SG_ VCRIGHT_a126_leftVaneN0P4HS m126 : 39|1@1+ (1,0) [0|0] "" Vector__XXX
 SG_ VCRIGHT_a127_leftVaneN0P4HS m127 : 39|1@1+ (1,0) [0|0] "" Vector__XXX
 SG_ VCRIGHT_a128_node0PreThermalShutdown m128 : 39|1@1+ (1,0) [0|0] "" Vector__XXX
 SG_ VCRIGHT_a175_relAccelTripped m175 : 39|1@1+ (1,0) [0|0] "" Vector__XXX
 SG_ VCRIGHT_a176_relAccelTripped m176 : 39|1@1+ (1,0) [0|0] "" Vector__XXX
 SG_ VCRIGHT_a200_encoderVoltage m200 : 39|6@1+ (0.15,0) [0|0] "" Vector__XXX
 SG_ VCRIGHT_a262_IGBTDriverPermanent m262 : 39|1@1+ (1,0) [0|0] "" Vector__XXX
 SG_ VCRIGHT_a444_highSide2GateDriver m444 : 39|1@1+ (1,0) [0|0] "" Vector__XXX
 SG_ VCRIGHT_a022_TaskInitError2 m22 : 40|8@1+ (1,0) [0|0] "" Vector__XXX
 SG_ VCRIGHT_a031_uds_bytes_3 m31 : 40|8@1+ (1,0) [0|0] "" Vector__XXX
 SG_ VCRIGHT_a041_CPULoad100msTask m41 : 40|8@1+ (1,0) [0|0] "" Vector__XXX
 SG_ VCRIGHT_a042_Usage1000msTask m42 : 40|8@1+ (1,0) [0|0] "" Vector__XXX
 SG_ VCRIGHT_a043_CallTrace1 m43 : 40|24@1+ (1,0) [0|0] "" Vector__XXX
 SG_ VCRIGHT_a044_CallTrace1 m44 : 40|24@1+ (1,0) [0|0] "" Vector__XXX
 SG_ VCRIGHT_a045_CallTrace1 m45 : 40|24@1+ (1,0) [0|0] "" Vector__XXX
 SG_ VCRIGHT_a046_CallTrace1 m46 : 40|24@1+ (1,0) [0|0] "" Vector__XXX
 SG_ VCRIGHT_a059_current m59 : 40|12@1+ (0.05,0) [0|0] "" Vector__XXX
 SG_ VCRIGHT_a063_disconnected m63 : 40|1@1+ (1,0) [0|0] "" Vector__XXX
 SG_ VCRIGHT_a104_BDY_status m104 : 40|1@1+ (1,0) [0|0] "" Vector__XXX
 SG_ VCRIGHT_a113_VEH_vehicleControlThermal m113 : 40|1@1+ (1,0) [0|0] "" Vector__XXX
 SG_ VCRIGHT_a118_BDY_outputPowerStatus m118 : 40|1@1+ (1,0) [0|0] "" Vector__XXX
 SG_ VCRIGHT_a120_VEH_chassisCntl m120 : 40|1@1+ (1,0) [0|0] "" Vector__XXX
 SG_ VCRIGHT_a126_leftBleedN0P5LS m126 : 40|1@1+ (1,0) [0|0] "" Vector__XXX
 SG_ VCRIGHT_a127_leftBleedN0P5LS m127 : 40|1@1+ (1,0) [0|0] "" Vector__XXX
 SG_ VCRIGHT_a128_node1SPIError m128 : 40|1@1+ (1,0) [0|0] "" Vector__XXX
 SG_ VCRIGHT_a164_downMovementTimeMs m164 : 40|7@1+ (50,0) [0|0] "" Vector__XXX
 SG_ VCRIGHT_a165_lowerEndStopPosition m165 : 40|8@1+ (10,0) [0|0] "" Vector__XXX
 SG_ VCRIGHT_a173_btnTimeMsDownLR m173 : 40|4@1+ (50,0) [0|0] "" Vector__XXX
 SG_ VCRIGHT_a180_releasePWM m180 : 40|8@1+ (1,0) [0|0] "" Vector__XXX
 SG_ VCRIGHT_a181_releasePWM m181 : 40|8@1+ (1,0) [0|0] "" Vector__XXX
 SG_ VCRIGHT_a206_unitStatusEPBM m206 : 40|5@1+ (1,0) [0|0] "" Vector__XXX
 SG_ VCRIGHT_a207_unitStatusEPBM m207 : 40|5@1+ (1,0) [0|0] "" Vector__XXX
 SG_ VCRIGHT_a208_unitStatusEPBM m208 : 40|5@1+ (1,0) [0|0] "" Vector__XXX
 SG_ VCRIGHT_a209_unitStatusEPBM m209 : 40|5@1+ (1,0) [0|0] "" Vector__XXX
 SG_ VCRIGHT_a210_unitStatusEPBM m210 : 40|5@1+ (1,0) [0|0] "" Vector__XXX
 SG_ VCRIGHT_a216_byte2 m216 : 40|8@1+ (1,0) [0|0] "" Vector__XXX
 SG_ VCRIGHT_a217_byte7 m217 : 40|8@1+ (1,0) [0|0] "" Vector__XXX
 SG_ VCRIGHT_a232_seatMotorState m232 : 40|3@1+ (1,0) [0|0] "" Vector__XXX
 SG_ VCRIGHT_a233_seatMotorState m233 : 40|3@1+ (1,0) [0|0] "" Vector__XXX
 SG_ VCRIGHT_a234_seatMotorState m234 : 40|3@1+ (1,0) [0|0] "" Vector__XXX
 SG_ VCRIGHT_a235_seatMotorState m235 : 40|3@1+ (1,0) [0|0] "" Vector__XXX
 SG_ VCRIGHT_a239_seatHeatTmpTarget m239 : 40|8@1- (0.5,0) [0|0] "" Vector__XXX
 SG_ VCRIGHT_a241_cushion m241 : 40|1@1+ (1,0) [0|0] "" Vector__XXX
 SG_ VCRIGHT_a242_seatHeatTmpTarget m242 : 40|8@1- (0.5,0) [0|0] "" Vector__XXX
 SG_ VCRIGHT_a244_cushion m244 : 40|1@1+ (1,0) [0|0] "" Vector__XXX
 SG_ VCRIGHT_a245_seatHeatTmpTarget m245 : 40|8@1- (0.5,0) [0|0] "" Vector__XXX
 SG_ VCRIGHT_a247_cushion m247 : 40|1@1+ (1,0) [0|0] "" Vector__XXX
 SG_ VCRIGHT_a248_seatHeatTmpTarget m248 : 40|8@1- (0.5,0) [0|0] "" Vector__XXX
 SG_ VCRIGHT_a250_cushion m250 : 40|1@1+ (1,0) [0|0] "" Vector__XXX
 SG_ VCRIGHT_a251_seatMotorState m251 : 40|3@1+ (1,0) [0|0] "" Vector__XXX
 SG_ VCRIGHT_a252_seatMotorState m252 : 40|3@1+ (1,0) [0|0] "" Vector__XXX
 SG_ VCRIGHT_a253_seatMotorState m253 : 40|3@1+ (1,0) [0|0] "" Vector__XXX
 SG_ VCRIGHT_a254_seatMotorState m254 : 40|3@1+ (1,0) [0|0] "" Vector__XXX
 SG_ VCRIGHT_a255_PCBTemp m255 : 40|8@1- (1,80) [0|0] "" Vector__XXX
 SG_ VCRIGHT_a262_LeftIGBTOpen m262 : 40|1@1+ (1,0) [0|0] "" Vector__XXX
 SG_ VCRIGHT_a263_seatMotorPosReal m263 : 40|12@1- (1,0) [0|0] "" Vector__XXX
 SG_ VCRIGHT_a264_seatMotorPosReal m264 : 40|12@1- (1,0) [0|0] "" Vector__XXX
 SG_ VCRIGHT_a265_seatMotorPosReal m265 : 40|12@1- (1,0) [0|0] "" Vector__XXX
 SG_ VCRIGHT_a266_seatMotorPosReal m266 : 40|12@1- (1,0) [0|0] "" Vector__XXX
 SG_ VCRIGHT_a267_seatMotorPosReal m267 : 40|12@1- (1,0) [0|0] "" Vector__XXX
 SG_ VCRIGHT_a268_seatMotorPosReal m268 : 40|12@1- (1,0) [0|0] "" Vector__XXX
 SG_ VCRIGHT_a269_seatMotorPosReal m269 : 40|12@1- (1,0) [0|0] "" Vector__XXX
 SG_ VCRIGHT_a270_seatMotorPosReal m270 : 40|12@1- (1,0) [0|0] "" Vector__XXX
 SG_ VCRIGHT_a310_ambientTemperature m310 : 40|8@1+ (0.5,-40) [0|0] "" Vector__XXX
 SG_ VCRIGHT_a323_calibrationUp m323 : 40|12@1+ (0.002,0) [0|0] "" Vector__XXX
 SG_ VCRIGHT_a376_2RowSeatEasyEntryState m376 : 40|3@1+ (1,0) [0|0] "" Vector__XXX
 SG_ VCRIGHT_a444_lowSide2GateDriver m444 : 40|1@1+ (1,0) [0|0] "" Vector__XXX
 SG_ VCRIGHT_a445_actualMSB m445 : 40|8@1+ (1,0) [0|0] "" Vector__XXX
 SG_ VCRIGHT_a499_localEpbStatus m499 : 40|5@1+ (1,0) [0|0] "" Vector__XXX
 SG_ VCRIGHT_a526_tempChangeRate m526 : 40|16@1- (0.125,55) [0|0] "" Vector__XXX
 SG_ VCRIGHT_a533_forwardCalcTime m533 : 40|11@1+ (5,0) [0|0] "" Vector__XXX
 SG_ VCRIGHT_a540_RHBleedDBGDitherErrToTarget m540 : 40|5@1+ (1,0) [0|0] "" Vector__XXX
 SG_ VCRIGHT_a546_mirrorFoldDirection m546 : 40|1@1+ (1,0) [0|0] "" Vector__XXX
 SG_ VCRIGHT_a551_interiorReleaseReqCountRear m551 : 40|8@1+ (1,0) [0|0] "" Vector__XXX
 SG_ VCRIGHT_a063_indeterminate m63 : 41|1@1+ (1,0) [0|0] "" Vector__XXX
 SG_ VCRIGHT_a104_PARTY_autonomyControl m104 : 41|1@1+ (1,0) [0|0] "" Vector__XXX
 SG_ VCRIGHT_a113_CH_odo m113 : 41|1@1+ (1,0) [0|0] "" Vector__XXX
 SG_ VCRIGHT_a118_BDY_vehicleTime m118 : 41|1@1+ (1,0) [0|0] "" Vector__XXX
 SG_ VCRIGHT_a120_CH_locStatus2 m120 : 41|1@1+ (1,0) [0|0] "" Vector__XXX
 SG_ VCRIGHT_a126_leftBleedN0P5HS m126 : 41|1@1+ (1,0) [0|0] "" Vector__XXX
 SG_ VCRIGHT_a127_leftBleedN0P5HS m127 : 41|1@1+ (1,0) [0|0] "" Vector__XXX
 SG_ VCRIGHT_a128_node1LoadError m128 : 41|1@1+ (1,0) [0|0] "" Vector__XXX
 SG_ VCRIGHT_a150_absAccelExceedance m150 : 41|8@1+ (0.09803921568627451,0) [0|0] "" Vector__XXX
 SG_ VCRIGHT_a151_absAccelExceedance m151 : 41|8@1+ (0.09803921568627451,0) [0|0] "" Vector__XXX
 SG_ VCRIGHT_a241_backrest m241 : 41|1@1+ (1,0) [0|0] "" Vector__XXX
 SG_ VCRIGHT_a244_backrest m244 : 41|1@1+ (1,0) [0|0] "" Vector__XXX
 SG_ VCRIGHT_a247_backrest m247 : 41|1@1+ (1,0) [0|0] "" Vector__XXX
 SG_ VCRIGHT_a250_backrest m250 : 41|1@1+ (1,0) [0|0] "" Vector__XXX
 SG_ VCRIGHT_a262_RightIGBTOpen m262 : 41|1@1+ (1,0) [0|0] "" Vector__XXX
 SG_ VCRIGHT_a444_highSide1GateDriver m444 : 41|1@1+ (1,0) [0|0] "" Vector__XXX
 SG_ VCRIGHT_a546_mirrorFoldTime m546 : 41|9@1+ (10,0) [0|0] "" Vector__XXX
 SG_ VCRIGHT_a063_stuckActive m63 : 42|1@1+ (1,0) [0|0] "" Vector__XXX
 SG_ VCRIGHT_a104_VEH_autonomyControl m104 : 42|1@1+ (1,0) [0|0] "" Vector__XXX
 SG_ VCRIGHT_a113_VEH_locationStatus m113 : 42|1@1+ (1,0) [0|0] "" Vector__XXX
 SG_ VCRIGHT_a118_PARTY_AP_vehicleState1HzMuxed m118 : 42|1@1+ (1,0) [0|0] "" Vector__XXX
 SG_ VCRIGHT_a120_VEH_locStatus m120 : 42|1@1+ (1,0) [0|0] "" Vector__XXX
 SG_ VCRIGHT_a126_leftBleedN0P6LS m126 : 42|1@1+ (1,0) [0|0] "" Vector__XXX
 SG_ VCRIGHT_a127_leftBleedN0P6LS m127 : 42|1@1+ (1,0) [0|0] "" Vector__XXX
 SG_ VCRIGHT_a128_node1UnderVoltage m128 : 42|1@1+ (1,0) [0|0] "" Vector__XXX
 SG_ VCRIGHT_a218_motorCurrent m218 : 42|10@1- (0.04,0) [0|0] "" Vector__XXX
 SG_ VCRIGHT_a352_startTime m352 : 42|10@1+ (10,0) [0|0] "" Vector__XXX
 SG_ VCRIGHT_a444_lowSide1GateDriver m444 : 42|1@1+ (1,0) [0|0] "" Vector__XXX
 SG_ VCRIGHT_a063_faulted m63 : 43|1@1+ (1,0) [0|0] "" Vector__XXX
 SG_ VCRIGHT_a066_shortPeriodLength1 m66 : 43|7@1+ (10,0) [0|0] "" Vector__XXX
 SG_ VCRIGHT_a104_CH_autonomyControl m104 : 43|1@1+ (1,0) [0|0] "" Vector__XXX
 SG_ VCRIGHT_a113_VEH_gpsTime m113 : 43|1@1+ (1,0) [0|0] "" Vector__XXX
 SG_ VCRIGHT_a118_BDY_AP_vehicleState1HzMuxed m118 : 43|1@1+ (1,0) [0|0] "" Vector__XXX
 SG_ VCRIGHT_a120_VEH_locStatus2 m120 : 43|1@1+ (1,0) [0|0] "" Vector__XXX
 SG_ VCRIGHT_a126_leftBleedN0P6HS m126 : 43|1@1+ (1,0) [0|0] "" Vector__XXX
 SG_ VCRIGHT_a127_leftBleedN0P6HS m127 : 43|1@1+ (1,0) [0|0] "" Vector__XXX
 SG_ VCRIGHT_a128_node1OverVoltage m128 : 43|1@1+ (1,0) [0|0] "" Vector__XXX
 SG_ VCRIGHT_a166_sealPos m166 : 43|8@1+ (1,0) [0|0] "" Vector__XXX
 SG_ VCRIGHT_a232_seatSwitchBack m232 : 43|2@1+ (1,0) [0|0] "" Vector__XXX
 SG_ VCRIGHT_a233_seatSwitchBack m233 : 43|2@1+ (1,0) [0|0] "" Vector__XXX
 SG_ VCRIGHT_a234_seatSwitchBack m234 : 43|2@1+ (1,0) [0|0] "" Vector__XXX
 SG_ VCRIGHT_a235_seatSwitchBack m235 : 43|2@1+ (1,0) [0|0] "" Vector__XXX
 SG_ VCRIGHT_a251_seatSwitchBack m251 : 43|2@1+ (1,0) [0|0] "" Vector__XXX
 SG_ VCRIGHT_a252_seatSwitchBack m252 : 43|2@1+ (1,0) [0|0] "" Vector__XXX
 SG_ VCRIGHT_a253_seatSwitchBack m253 : 43|2@1+ (1,0) [0|0] "" Vector__XXX
 SG_ VCRIGHT_a254_seatSwitchBack m254 : 43|2@1+ (1,0) [0|0] "" Vector__XXX
 SG_ VCRIGHT_a376_2RowSeatTrackPositionSwitch m376 : 43|2@1+ (1,0) [0|0] "" Vector__XXX
 SG_ VCRIGHT_a444_highSide2OverCurent m444 : 43|1@1+ (1,0) [0|0] "" Vector__XXX
 SG_ VCRIGHT_a450_tempDuctRightEst m450 : 43|8@1+ (0.5,-22) [0|0] "" Vector__XXX
 SG_ VCRIGHT_a104_BDY_autonomyControl m104 : 44|1@1+ (1,0) [0|0] "" Vector__XXX
 SG_ VCRIGHT_a113_VEH_gpsVehicleSpeed m113 : 44|1@1+ (1,0) [0|0] "" Vector__XXX
 SG_ VCRIGHT_a118_PARTY_VCFRONT_cameraCleaningStatus m118 : 44|1@1+ (1,0) [0|0] "" Vector__XXX
 SG_ VCRIGHT_a120_VEH_prndControl m120 : 44|1@1+ (1,0) [0|0] "" Vector__XXX
 SG_ VCRIGHT_a126_upperModeN1P1LS m126 : 44|1@1+ (1,0) [0|0] "" Vector__XXX
 SG_ VCRIGHT_a127_upperModeN1P1LS m127 : 44|1@1+ (1,0) [0|0] "" Vector__XXX
 SG_ VCRIGHT_a128_node1NotPowerOnReset m128 : 44|1@1+ (1,0) [0|0] "" Vector__XXX
 SG_ VCRIGHT_a173_btnTimeMsAutoDownLR m173 : 44|4@1+ (50,0) [0|0] "" Vector__XXX
 SG_ VCRIGHT_a228_seatMotorState m228 : 44|3@1+ (1,0) [0|0] "" Vector__XXX
 SG_ VCRIGHT_a229_seatMotorState m229 : 44|3@1+ (1,0) [0|0] "" Vector__XXX
 SG_ VCRIGHT_a230_seatMotorState m230 : 44|3@1+ (1,0) [0|0] "" Vector__XXX
 SG_ VCRIGHT_a231_seatMotorState m231 : 44|3@1+ (1,0) [0|0] "" Vector__XXX
 SG_ VCRIGHT_a316_averageCurrentAmps m316 : 44|12@1+ (0.01,0) [0|0] "" Vector__XXX
 SG_ VCRIGHT_a360_instantAccel m360 : 44|10@1+ (0.002,0) [0|0] "" Vector__XXX
 SG_ VCRIGHT_a426_seatMotorState m426 : 44|3@1+ (1,0) [0|0] "" Vector__XXX
 SG_ VCRIGHT_a427_seatMotorState m427 : 44|3@1+ (1,0) [0|0] "" Vector__XXX
 SG_ VCRIGHT_a428_seatMotorState m428 : 44|3@1+ (1,0) [0|0] "" Vector__XXX
 SG_ VCRIGHT_a429_seatMotorState m429 : 44|3@1+ (1,0) [0|0] "" Vector__XXX
 SG_ VCRIGHT_a444_lowSide2OverCurent m444 : 44|1@1+ (1,0) [0|0] "" Vector__XXX
 SG_ VCRIGHT_a104_VEH_wirelessChargingStatus m104 : 45|1@1+ (1,0) [0|0] "" Vector__XXX
 SG_ VCRIGHT_a113_VEH_status2 m113 : 45|1@1+ (1,0) [0|0] "" Vector__XXX
 SG_ VCRIGHT_a120_VEH_vehicleEstimates m120 : 45|1@1+ (1,0) [0|0] "" Vector__XXX
 SG_ VCRIGHT_a126_upperModeN1P1HS m126 : 45|1@1+ (1,0) [0|0] "" Vector__XXX
 SG_ VCRIGHT_a127_upperModeN1P1HS m127 : 45|1@1+ (1,0) [0|0] "" Vector__XXX
 SG_ VCRIGHT_a128_node1ThermalShutdown m128 : 45|1@1+ (1,0) [0|0] "" Vector__XXX
 SG_ VCRIGHT_a200_encoderEnabled m200 : 45|1@1+ (1,0) [0|0] "" Vector__XXX
 SG_ VCRIGHT_a232_seatSwitchForward m232 : 45|2@1+ (1,0) [0|0] "" Vector__XXX
 SG_ VCRIGHT_a233_seatSwitchForward m233 : 45|2@1+ (1,0) [0|0] "" Vector__XXX
 SG_ VCRIGHT_a234_seatSwitchForward m234 : 45|2@1+ (1,0) [0|0] "" Vector__XXX
 SG_ VCRIGHT_a235_seatSwitchForward m235 : 45|2@1+ (1,0) [0|0] "" Vector__XXX
 SG_ VCRIGHT_a251_seatSwitchForward m251 : 45|2@1+ (1,0) [0|0] "" Vector__XXX
 SG_ VCRIGHT_a252_seatSwitchForward m252 : 45|2@1+ (1,0) [0|0] "" Vector__XXX
 SG_ VCRIGHT_a253_seatSwitchForward m253 : 45|2@1+ (1,0) [0|0] "" Vector__XXX
 SG_ VCRIGHT_a254_seatSwitchForward m254 : 45|2@1+ (1,0) [0|0] "" Vector__XXX
 SG_ VCRIGHT_a444_highSide1OverCurent m444 : 45|1@1+ (1,0) [0|0] "" Vector__XXX
 SG_ VCRIGHT_a499_okayToRequalifyCdp m499 : 45|1@1+ (1,0) [0|0] "" Vector__XXX
 SG_ VCRIGHT_a540_UpperModeDebugDither m540 : 45|1@1+ (1,0) [0|0] "" Vector__XXX
 SG_ VCRIGHT_a104_VEH_control m104 : 46|1@1+ (1,0) [0|0] "" Vector__XXX
 SG_ VCRIGHT_a113_VEH_autopilotControl m113 : 46|1@1+ (1,0) [0|0] "" Vector__XXX
 SG_ VCRIGHT_a120_PARTY_motorStatus m120 : 46|1@1+ (1,0) [0|0] "" Vector__XXX
 SG_ VCRIGHT_a126_upperModeN1P2LS m126 : 46|1@1+ (1,0) [0|0] "" Vector__XXX
 SG_ VCRIGHT_a127_upperModeN1P2LS m127 : 46|1@1+ (1,0) [0|0] "" Vector__XXX
 SG_ VCRIGHT_a128_node1PreThermalShutdown m128 : 46|1@1+ (1,0) [0|0] "" Vector__XXX
 SG_ VCRIGHT_a200_motorPosition m200 : 46|7@1+ (20,0) [0|0] "" Vector__XXX
 SG_ VCRIGHT_a444_lowSide1OverCurent m444 : 46|1@1+ (1,0) [0|0] "" Vector__XXX
 SG_ VCRIGHT_a499_bootTimeExpired m499 : 46|1@1+ (1,0) [0|0] "" Vector__XXX
 SG_ VCRIGHT_a540_UpperModeDBGDitherErrToTarget m540 : 46|5@1+ (1,0) [0|0] "" Vector__XXX
 SG_ VCRIGHT_a104_VEH_redundantBrakingControl m104 : 47|1@1+ (1,0) [0|0] "" Vector__XXX
 SG_ VCRIGHT_a113_VEH_ambientLightingCtrls m113 : 47|1@1+ (1,0) [0|0] "" Vector__XXX
 SG_ VCRIGHT_a120_VEH_motorStatus m120 : 47|1@1+ (1,0) [0|0] "" Vector__XXX
 SG_ VCRIGHT_a126_upperModeN1P2HS m126 : 47|1@1+ (1,0) [0|0] "" Vector__XXX
 SG_ VCRIGHT_a127_upperModeN1P2HS m127 : 47|1@1+ (1,0) [0|0] "" Vector__XXX
 SG_ VCRIGHT_a128_node2SPIError m128 : 47|1@1+ (1,0) [0|0] "" Vector__XXX
 SG_ VCRIGHT_a444_spiInit m444 : 47|1@1+ (1,0) [0|0] "" Vector__XXX
 SG_ VCRIGHT_a499_faultForBootTimeout m499 : 47|1@1+ (1,0) [0|0] "" Vector__XXX
 SG_ VCRIGHT_a000_alertDataW2 m0 : 48|16@1+ (1,0) [0|0] "" Vector__XXX
 SG_ VCRIGHT_a003_Data m3 : 48|16@1+ (1,0) [0|0] "" Vector__XXX
 SG_ VCRIGHT_a022_TaskInitError3 m22 : 48|8@1+ (1,0) [0|0] "" Vector__XXX
 SG_ VCRIGHT_a031_uds_bytes_4 m31 : 48|8@1+ (1,0) [0|0] "" Vector__XXX
 SG_ VCRIGHT_a041_CPULoad1000msTask m41 : 48|8@1+ (1,0) [0|0] "" Vector__XXX
 SG_ VCRIGHT_a042_UsageUDSTask m42 : 48|8@1+ (1,0) [0|0] "" Vector__XXX
 SG_ VCRIGHT_a104_BDY_bodyControls m104 : 48|1@1+ (1,0) [0|0] "" Vector__XXX
 SG_ VCRIGHT_a113_VEH_driverAssistMapData m113 : 48|1@1+ (1,0) [0|0] "" Vector__XXX
 SG_ VCRIGHT_a120_BDY_speed m120 : 48|1@1+ (1,0) [0|0] "" Vector__XXX
 SG_ VCRIGHT_a126_rightVaneN1P3LS m126 : 48|1@1+ (1,0) [0|0] "" Vector__XXX
 SG_ VCRIGHT_a127_rightVaneN1P3LS m127 : 48|1@1+ (1,0) [0|0] "" Vector__XXX
 SG_ VCRIGHT_a128_node2LoadError m128 : 48|1@1+ (1,0) [0|0] "" Vector__XXX
 SG_ VCRIGHT_a164_calibratedVoltage m164 : 48|6@1+ (0.25,0) [0|0] "" Vector__XXX
 SG_ VCRIGHT_a167_pinchV3InUse m167 : 48|1@1+ (1,0) [0|0] "" Vector__XXX
 SG_ VCRIGHT_a168_pinchV3InUse m168 : 48|1@1+ (1,0) [0|0] "" Vector__XXX
 SG_ VCRIGHT_a173_btnTimeMsDownRF m173 : 48|4@1+ (50,0) [0|0] "" Vector__XXX
 SG_ VCRIGHT_a180_latchStatus m180 : 48|4@1+ (1,0) [0|0] "" Vector__XXX
 SG_ VCRIGHT_a181_latchStatus m181 : 48|4@1+ (1,0) [0|0] "" Vector__XXX
 SG_ VCRIGHT_a202_epbConfig m202 : 48|4@1+ (1,0) [0|0] "" Vector__XXX
 SG_ VCRIGHT_a203_epbConfig m203 : 48|4@1+ (1,0) [0|0] "" Vector__XXX
 SG_ VCRIGHT_a204_epbConfig m204 : 48|4@1+ (1,0) [0|0] "" Vector__XXX
 SG_ VCRIGHT_a205_epbConfig m205 : 48|4@1+ (1,0) [0|0] "" Vector__XXX
 SG_ VCRIGHT_a211_epbConfig m211 : 48|4@1+ (1,0) [0|0] "" Vector__XXX
 SG_ VCRIGHT_a212_epbConfig m212 : 48|4@1+ (1,0) [0|0] "" Vector__XXX
 SG_ VCRIGHT_a213_epbConfig m213 : 48|4@1+ (1,0) [0|0] "" Vector__XXX
 SG_ VCRIGHT_a214_epbConfig m214 : 48|4@1+ (1,0) [0|0] "" Vector__XXX
 SG_ VCRIGHT_a216_byte3 m216 : 48|8@1+ (1,0) [0|0] "" Vector__XXX
 SG_ VCRIGHT_a228_seatSwitchBack m228 : 48|2@1+ (1,0) [0|0] "" Vector__XXX
 SG_ VCRIGHT_a229_seatSwitchBack m229 : 48|2@1+ (1,0) [0|0] "" Vector__XXX
 SG_ VCRIGHT_a230_seatSwitchBack m230 : 48|2@1+ (1,0) [0|0] "" Vector__XXX
 SG_ VCRIGHT_a231_seatSwitchBack m231 : 48|2@1+ (1,0) [0|0] "" Vector__XXX
 SG_ VCRIGHT_a236_lumbarDiagStatus m236 : 48|1@1+ (1,0) [0|0] "" Vector__XXX
 SG_ VCRIGHT_a237_lumbarDiagStatus m237 : 48|1@1+ (1,0) [0|0] "" Vector__XXX
 SG_ VCRIGHT_a238_lumbarDiagStatus m238 : 48|1@1+ (1,0) [0|0] "" Vector__XXX
 SG_ VCRIGHT_a321_maxCurrent m321 : 48|7@1+ (0.25,0) [0|0] "" Vector__XXX
 SG_ VCRIGHT_a322_maxCurrent m322 : 48|7@1+ (0.25,0) [0|0] "" Vector__XXX
 SG_ VCRIGHT_a426_seatSwitchBack m426 : 48|2@1+ (1,0) [0|0] "" Vector__XXX
 SG_ VCRIGHT_a427_seatSwitchBack m427 : 48|2@1+ (1,0) [0|0] "" Vector__XXX
 SG_ VCRIGHT_a428_seatSwitchBack m428 : 48|2@1+ (1,0) [0|0] "" Vector__XXX
 SG_ VCRIGHT_a429_seatSwitchBack m429 : 48|2@1+ (1,0) [0|0] "" Vector__XXX
 SG_ VCRIGHT_a444_spiPeriodicCheck m444 : 48|1@1+ (1,0) [0|0] "" Vector__XXX
 SG_ VCRIGHT_a445_actualLSB m445 : 48|8@1+ (1,0) [0|0] "" Vector__XXX
 SG_ VCRIGHT_a499_anyCdpRequest m499 : 48|1@1+ (1,0) [0|0] "" Vector__XXX
 SG_ VCRIGHT_a551_lastRequestSourceRear m551 : 48|3@1+ (1,0) [0|0] "" Vector__XXX
 SG_ VCRIGHT_a104_VEH_bodyControls2 m104 : 49|1@1+ (1,0) [0|0] "" Vector__XXX
 SG_ VCRIGHT_a113_CH_vehicleControl2 m113 : 49|1@1+ (1,0) [0|0] "" Vector__XXX
 SG_ VCRIGHT_a126_rightVaneN1P3HS m126 : 49|1@1+ (1,0) [0|0] "" Vector__XXX
 SG_ VCRIGHT_a127_rightVaneN1P3HS m127 : 49|1@1+ (1,0) [0|0] "" Vector__XXX
 SG_ VCRIGHT_a128_node2UnderVoltage m128 : 49|1@1+ (1,0) [0|0] "" Vector__XXX
 SG_ VCRIGHT_a150_relAccelExceedance m150 : 49|8@1+ (0.09803921568627451,0) [0|0] "" Vector__XXX
 SG_ VCRIGHT_a151_relAccelExceedance m151 : 49|8@1+ (0.09803921568627451,0) [0|0] "" Vector__XXX
 SG_ VCRIGHT_a236_lumbarAState m236 : 49|3@1+ (1,0) [0|0] "" Vector__XXX
 SG_ VCRIGHT_a237_lumbarAState m237 : 49|3@1+ (1,0) [0|0] "" Vector__XXX
 SG_ VCRIGHT_a238_lumbarAState m238 : 49|3@1+ (1,0) [0|0] "" Vector__XXX
 SG_ VCRIGHT_a444_spiFault m444 : 49|1@1+ (1,0) [0|0] "" Vector__XXX
 SG_ VCRIGHT_a499_localEpbmCdpOkay m499 : 49|1@1+ (1,0) [0|0] "" Vector__XXX
 SG_ VCRIGHT_a066_shortPeriodLength2 m66 : 50|7@1+ (10,0) [0|0] "" Vector__XXX
 SG_ VCRIGHT_a113_VEH_odo m113 : 50|1@1+ (1,0) [0|0] "" Vector__XXX
 SG_ VCRIGHT_a126_rightVaneN1P4LS m126 : 50|1@1+ (1,0) [0|0] "" Vector__XXX
 SG_ VCRIGHT_a127_rightVaneN1P4LS m127 : 50|1@1+ (1,0) [0|0] "" Vector__XXX
 SG_ VCRIGHT_a128_node2OverVoltage m128 : 50|1@1+ (1,0) [0|0] "" Vector__XXX
 SG_ VCRIGHT_a228_seatSwitchForward m228 : 50|2@1+ (1,0) [0|0] "" Vector__XXX
 SG_ VCRIGHT_a229_seatSwitchForward m229 : 50|2@1+ (1,0) [0|0] "" Vector__XXX
 SG_ VCRIGHT_a230_seatSwitchForward m230 : 50|2@1+ (1,0) [0|0] "" Vector__XXX
 SG_ VCRIGHT_a231_seatSwitchForward m231 : 50|2@1+ (1,0) [0|0] "" Vector__XXX
 SG_ VCRIGHT_a426_seatSwitchForward m426 : 50|2@1+ (1,0) [0|0] "" Vector__XXX
 SG_ VCRIGHT_a427_seatSwitchForward m427 : 50|2@1+ (1,0) [0|0] "" Vector__XXX
 SG_ VCRIGHT_a428_seatSwitchForward m428 : 50|2@1+ (1,0) [0|0] "" Vector__XXX
 SG_ VCRIGHT_a429_seatSwitchForward m429 : 50|2@1+ (1,0) [0|0] "" Vector__XXX
 SG_ VCRIGHT_a444_voltageMonitor m444 : 50|1@1+ (1,0) [0|0] "" Vector__XXX
 SG_ VCRIGHT_a499_remoteEpbmCdpOkay m499 : 50|1@1+ (1,0) [0|0] "" Vector__XXX
 SG_ VCRIGHT_a058_newREstimate m58 : 51|12@1+ (0.00061,0) [0|0] "" Vector__XXX
 SG_ VCRIGHT_a113_VEH_frontSeatRequests m113 : 51|1@1+ (1,0) [0|0] "" Vector__XXX
 SG_ VCRIGHT_a126_rightVaneN1P4HS m126 : 51|1@1+ (1,0) [0|0] "" Vector__XXX
 SG_ VCRIGHT_a127_rightVaneN1P4HS m127 : 51|1@1+ (1,0) [0|0] "" Vector__XXX
 SG_ VCRIGHT_a128_node2NotPowerOnReset m128 : 51|1@1+ (1,0) [0|0] "" Vector__XXX
 SG_ VCRIGHT_a166_REAR_SWITCH_IGNORED m166 : 51|1@1+ (1,0) [0|0] "" Vector__XXX
 SG_ VCRIGHT_a444_enableLow m444 : 51|1@1+ (1,0) [0|0] "" Vector__XXX
 SG_ VCRIGHT_a450_hvacAirFlowModeRow1 m450 : 51|3@1+ (1,0) [0|0] "" Vector__XXX
 SG_ VCRIGHT_a499_espCdpActuating m499 : 51|1@1+ (1,0) [0|0] "" Vector__XXX
 SG_ VCRIGHT_a540_LowerDebugDither m540 : 51|1@1+ (1,0) [0|0] "" Vector__XXX
 SG_ VCRIGHT_a113_VEH_weatherDataService m113 : 52|1@1+ (1,0) [0|0] "" Vector__XXX
 SG_ VCRIGHT_a126_rightBleedN1P5LS m126 : 52|1@1+ (1,0) [0|0] "" Vector__XXX
 SG_ VCRIGHT_a127_rightBleedN1P5LS m127 : 52|1@1+ (1,0) [0|0] "" Vector__XXX
 SG_ VCRIGHT_a128_node2ThermalShutdown m128 : 52|1@1+ (1,0) [0|0] "" Vector__XXX
 SG_ VCRIGHT_a166_INT_SWITCH_IGNORED m166 : 52|1@1+ (1,0) [0|0] "" Vector__XXX
 SG_ VCRIGHT_a173_btnTimeMsAutoDownRF m173 : 52|4@1+ (50,0) [0|0] "" Vector__XXX
 SG_ VCRIGHT_a180_latchClawStatus m180 : 52|1@1+ (1,0) [0|0] "" Vector__XXX
 SG_ VCRIGHT_a181_latchClawStatus m181 : 52|1@1+ (1,0) [0|0] "" Vector__XXX
 SG_ VCRIGHT_a218_motorDutyCycle m218 : 52|10@1+ (0.1,0) [0|0] "" Vector__XXX
 SG_ VCRIGHT_a236_lumbarBState m236 : 52|3@1+ (1,0) [0|0] "" Vector__XXX
 SG_ VCRIGHT_a237_lumbarBState m237 : 52|3@1+ (1,0) [0|0] "" Vector__XXX
 SG_ VCRIGHT_a238_lumbarBState m238 : 52|3@1+ (1,0) [0|0] "" Vector__XXX
 SG_ VCRIGHT_a263_seatMotorState m263 : 52|3@1+ (1,0) [0|0] "" Vector__XXX
 SG_ VCRIGHT_a264_seatMotorState m264 : 52|3@1+ (1,0) [0|0] "" Vector__XXX
 SG_ VCRIGHT_a265_seatMotorState m265 : 52|3@1+ (1,0) [0|0] "" Vector__XXX
 SG_ VCRIGHT_a266_seatMotorState m266 : 52|3@1+ (1,0) [0|0] "" Vector__XXX
 SG_ VCRIGHT_a267_seatMotorState m267 : 52|3@1+ (1,0) [0|0] "" Vector__XXX
 SG_ VCRIGHT_a268_seatMotorState m268 : 52|3@1+ (1,0) [0|0] "" Vector__XXX
 SG_ VCRIGHT_a269_seatMotorState m269 : 52|3@1+ (1,0) [0|0] "" Vector__XXX
 SG_ VCRIGHT_a270_seatMotorState m270 : 52|3@1+ (1,0) [0|0] "" Vector__XXX
 SG_ VCRIGHT_a323_calibrationDown m323 : 52|12@1+ (0.002,0) [0|0] "" Vector__XXX
 SG_ VCRIGHT_a352_duration m352 : 52|10@1+ (1,0) [0|0] "" Vector__XXX
 SG_ VCRIGHT_a426_cabinTmp m426 : 52|12@1- (0.1,0) [0|0] "" Vector__XXX
 SG_ VCRIGHT_a427_cabinTmp m427 : 52|12@1- (0.1,0) [0|0] "" Vector__XXX
 SG_ VCRIGHT_a428_cabinTmp m428 : 52|12@1- (0.1,0) [0|0] "" Vector__XXX
 SG_ VCRIGHT_a429_cabinTmp m429 : 52|12@1- (0.1,0) [0|0] "" Vector__XXX
 SG_ VCRIGHT_a499_localEpbmEpbDynamic m499 : 52|1@1+ (1,0) [0|0] "" Vector__XXX
 SG_ VCRIGHT_a540_LowerDBGDitherErrToTarget m540 : 52|5@1+ (1,0) [0|0] "" Vector__XXX
 SG_ VCRIGHT_a113_VEH_hvacDebugControl m113 : 53|1@1+ (1,0) [0|0] "" Vector__XXX
 SG_ VCRIGHT_a126_rightBleedN1P5HS m126 : 53|1@1+ (1,0) [0|0] "" Vector__XXX
 SG_ VCRIGHT_a127_rightBleedN1P5HS m127 : 53|1@1+ (1,0) [0|0] "" Vector__XXX
 SG_ VCRIGHT_a128_node2PreThermalShutdown m128 : 53|1@1+ (1,0) [0|0] "" Vector__XXX
 SG_ VCRIGHT_a166_PINCH_TABLE_REJECTED m166 : 53|1@1+ (1,0) [0|0] "" Vector__XXX
 SG_ VCRIGHT_a200_phantomTicks m200 : 53|11@1- (1,0) [0|0] "" Vector__XXX
 SG_ VCRIGHT_a499_remoteEpbmEpbDynamic m499 : 53|1@1+ (1,0) [0|0] "" Vector__XXX
 SG_ VCRIGHT_a126_rightBleedN1P6LS m126 : 54|1@1+ (1,0) [0|0] "" Vector__XXX
 SG_ VCRIGHT_a127_rightBleedN1P6LS m127 : 54|1@1+ (1,0) [0|0] "" Vector__XXX
 SG_ VCRIGHT_a128_node0IntakeActive m128 : 54|1@1+ (1,0) [0|0] "" Vector__XXX
 SG_ VCRIGHT_a166_SHORT_DROP_FAILED m166 : 54|1@1+ (1,0) [0|0] "" Vector__XXX
 SG_ VCRIGHT_a360_instantAngle m360 : 54|10@1+ (1e-05,0) [0|0] "" Vector__XXX
 SG_ VCRIGHT_a450_runningCrackedRodMitigation m450 : 54|1@1+ (1,0) [0|0] "" Vector__XXX
 SG_ VCRIGHT_a499_parkButtonPressed m499 : 54|1@1+ (1,0) [0|0] "" Vector__XXX
 SG_ VCRIGHT_a126_rightBleedN1P6HS m126 : 55|1@1+ (1,0) [0|0] "" Vector__XXX
 SG_ VCRIGHT_a127_rightBleedN1P6HS m127 : 55|1@1+ (1,0) [0|0] "" Vector__XXX
 SG_ VCRIGHT_a128_node0LeftVaneActive m128 : 55|1@1+ (1,0) [0|0] "" Vector__XXX
 SG_ VCRIGHT_a166_CAL_CLEAR_ENC_LOSS m166 : 55|1@1+ (1,0) [0|0] "" Vector__XXX
 SG_ VCRIGHT_a450_rightBankCompromisedRod m450 : 55|3@1+ (1,0) [0|0] "" Vector__XXX
 SG_ VCRIGHT_a499_cdpValidActivationFault m499 : 55|1@1+ (1,0) [0|0] "" Vector__XXX
 SG_ VCRIGHT_a022_TaskInitError4 m22 : 56|8@1+ (1,0) [0|0] "" Vector__XXX
 SG_ VCRIGHT_a031_uds_bytes_5 m31 : 56|8@1+ (1,0) [0|0] "" Vector__XXX
 SG_ VCRIGHT_a041_CPULoadNVMMTask m41 : 56|8@1+ (1,0) [0|0] "" Vector__XXX
 SG_ VCRIGHT_a042_UsageNVMMTask m42 : 56|8@1+ (1,0) [0|0] "" Vector__XXX
 SG_ VCRIGHT_a126_lowerModeN2P1LS m126 : 56|1@1+ (1,0) [0|0] "" Vector__XXX
 SG_ VCRIGHT_a127_lowerModeN2P1LS m127 : 56|1@1+ (1,0) [0|0] "" Vector__XXX
 SG_ VCRIGHT_a128_node0LeftBleedActive m128 : 56|1@1+ (1,0) [0|0] "" Vector__XXX
 SG_ VCRIGHT_a166_SOFT_STOP_OVERRIDE m166 : 56|1@1+ (1,0) [0|0] "" Vector__XXX
 SG_ VCRIGHT_a173_btnTimeMsDownRR m173 : 56|4@1+ (50,0) [0|0] "" Vector__XXX
 SG_ VCRIGHT_a316_ambientTemperatureDegC m316 : 56|8@1+ (0.5,-40) [0|0] "" Vector__XXX
 SG_ VCRIGHT_a362_alertWhileMoving m362 : 56|1@1+ (1,0) [0|0] "" Vector__XXX
 SG_ VCRIGHT_a499_cdpNoParkButtonTimeout m499 : 56|1@1+ (1,0) [0|0] "" Vector__XXX
 SG_ VCRIGHT_a546_ambientTemperature m546 : 56|8@1+ (0.5,-40) [0|0] "" Vector__XXX
 SG_ VCRIGHT_a066_shortPeriodLength3 m66 : 57|7@1+ (10,0) [0|0] "" Vector__XXX
 SG_ VCRIGHT_a126_lowerModeN2P1HS m126 : 57|1@1+ (1,0) [0|0] "" Vector__XXX
 SG_ VCRIGHT_a127_lowerModeN2P1HS m127 : 57|1@1+ (1,0) [0|0] "" Vector__XXX
 SG_ VCRIGHT_a128_node1UpperModeActive m128 : 57|1@1+ (1,0) [0|0] "" Vector__XXX
 SG_ VCRIGHT_a150_speedExpScore m150 : 57|6@1- (0.0006451612903225806,-0.009677419354838708) [0|0] "" Vector__XXX
 SG_ VCRIGHT_a151_speedExpScore m151 : 57|6@1- (0.0006451612903225806,-0.009677419354838708) [0|0] "" Vector__XXX
 SG_ VCRIGHT_a166_AUTO_DOWN_HELD m166 : 57|1@1+ (1,0) [0|0] "" Vector__XXX
 SG_ VCRIGHT_a499_cdpEpbDynamicFault m499 : 57|1@1+ (1,0) [0|0] "" Vector__XXX
 SG_ VCRIGHT_a540_IntakeDebugDither m540 : 57|1@1+ (1,0) [0|0] "" Vector__XXX
 SG_ VCRIGHT_a126_lowerModeN2P2LS m126 : 58|1@1+ (1,0) [0|0] "" Vector__XXX
 SG_ VCRIGHT_a127_lowerModeN2P2LS m127 : 58|1@1+ (1,0) [0|0] "" Vector__XXX
 SG_ VCRIGHT_a128_node1RightVaneActive m128 : 58|1@1+ (1,0) [0|0] "" Vector__XXX
 SG_ VCRIGHT_a166_ENC_LOSS_SHORT_DROP m166 : 58|1@1+ (1,0) [0|0] "" Vector__XXX
 SG_ VCRIGHT_a450_leftBankCompromisedRod m450 : 58|3@1+ (1,0) [0|0] "" Vector__XXX
 SG_ VCRIGHT_a499_cdpUncommanedActuation m499 : 58|1@1+ (1,0) [0|0] "" Vector__XXX
 SG_ VCRIGHT_a540_IntakeDBGDitherErrToTarget m540 : 58|5@1+ (1,0) [0|0] "" Vector__XXX
 SG_ VCRIGHT_a126_lowerModeN2P2HS m126 : 59|1@1+ (1,0) [0|0] "" Vector__XXX
 SG_ VCRIGHT_a127_lowerModeN2P2HS m127 : 59|1@1+ (1,0) [0|0] "" Vector__XXX
 SG_ VCRIGHT_a128_node1RightBleedActive m128 : 59|1@1+ (1,0) [0|0] "" Vector__XXX
 SG_ VCRIGHT_a166_SHORT_RISE_FAILED_ENC m166 : 59|1@1+ (1,0) [0|0] "" Vector__XXX
 SG_ VCRIGHT_a128_node2LowerModeActive m128 : 60|1@1+ (1,0) [0|0] "" Vector__XXX
 SG_ VCRIGHT_a173_btnTimeMsAutoDownRR m173 : 60|4@1+ (50,0) [0|0] "" Vector__XXX
 SG_ VCRIGHT_a118_VEH_LVHealth m118 : 62|1@1+ (1,0) [0|0] "" Vector__XXX
 SG_ VCRIGHT_a058_faultReason m58 : 63|1@1+ (1,0) [0|0] "" Vector__XXX
 SG_ VCRIGHT_a118_BDY_LVHealth m118 : 63|1@1+ (1,0) [0|0] "" Vector__XXX
 SG_ VCRIGHT_a150_treatedInGear m150 : 63|1@1+ (1,0) [0|0] "" Vector__XXX
 SG_ VCRIGHT_a151_treatedInGear m151 : 63|1@1+ (1,0) [0|0] "" Vector__XXX

BO_ 1362 VCLEFT_systemStatus: 8 Vector__XXX
 SG_ VCLEFT_loadShedReason : 0|7@1+ (1,0) [0|0] "" Vector__XXX
 SG_ VCLEFT_loadShedSts12VAUXLoads : 7|1@1+ (1,0) [0|0] "" Vector__XXX
 SG_ VCLEFT_loadShedStsHVACBlower : 8|1@1+ (1,0) [0|0] "" Vector__XXX
 SG_ VCLEFT_loadShedStsLiftgate : 9|1@1+ (1,0) [0|0] "" Vector__XXX
 SG_ VCLEFT_loadShedStsMirrorHeater : 10|1@1+ (1,0) [0|0] "" Vector__XXX
 SG_ VCLEFT_loadShedStsMotorEncoders : 11|1@1+ (1,0) [0|0] "" Vector__XXX
 SG_ VCLEFT_loadShedStsSeatBackrest : 12|1@1+ (1,0) [0|0] "" Vector__XXX
 SG_ VCLEFT_loadShedStsSeatHeaters : 13|1@1+ (1,0) [0|0] "" Vector__XXX
 SG_ VCLEFT_loadShedStsSeatLift : 14|1@1+ (1,0) [0|0] "" Vector__XXX
 SG_ VCLEFT_loadShedStsSeatTilt : 15|1@1+ (1,0) [0|0] "" Vector__XXX
 SG_ VCLEFT_loadShedStsSeatTrack : 16|1@1+ (1,0) [0|0] "" Vector__XXX
 SG_ VCLEFT_loadShedStsSTWInOut : 17|1@1+ (1,0) [0|0] "" Vector__XXX
 SG_ VCLEFT_loadShedStsSTWUpDown : 18|1@1+ (1,0) [0|0] "" Vector__XXX
 SG_ VCLEFT_loadShedStsUSBPorts : 19|1@1+ (1,0) [0|0] "" Vector__XXX
 SG_ VCLEFT_loadShedStsWindowMotorsFront : 20|1@1+ (1,0) [0|0] "" Vector__XXX
 SG_ VCLEFT_loadShedStsWindowMotorsRear : 21|1@1+ (1,0) [0|0] "" Vector__XXX
 SG_ VCLEFT_alcoholInterlockState : 22|2@1+ (1,0) [0|0] "" Vector__XXX
 SG_ VCLEFT_systemStatusCounter : 52|4@1+ (1,0) [0|0] "" Vector__XXX
 SG_ VCLEFT_systemStatusChecksum : 56|8@1+ (1,0) [0|0] "" Vector__XXX

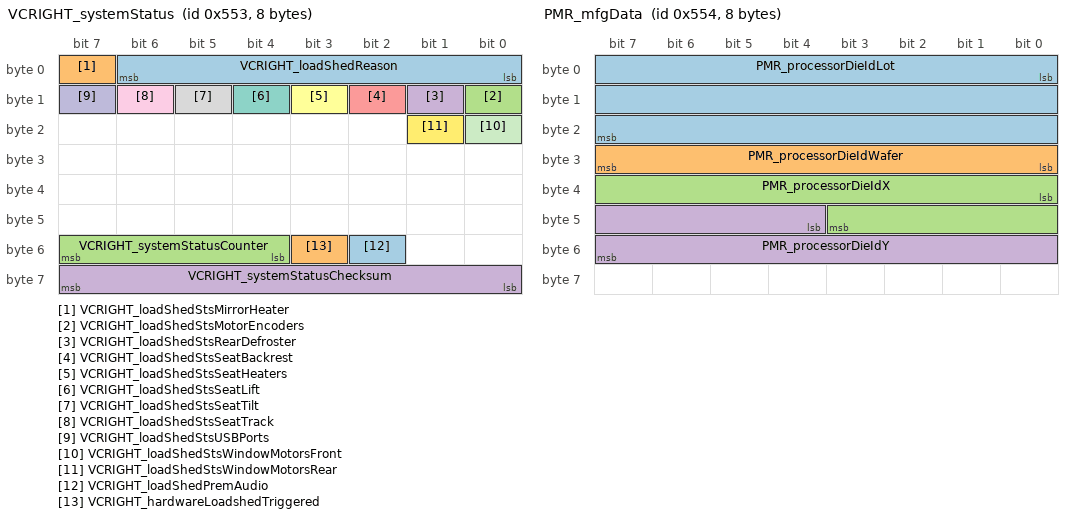
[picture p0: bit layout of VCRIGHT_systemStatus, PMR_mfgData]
BO_ 1363 VCRIGHT_systemStatus: 8 Vector__XXX
 SG_ VCRIGHT_loadShedReason : 0|7@1+ (1,0) [0|0] "" Vector__XXX
 SG_ VCRIGHT_loadShedStsMirrorHeater : 7|1@1+ (1,0) [0|0] "" Vector__XXX
 SG_ VCRIGHT_loadShedStsMotorEncoders : 8|1@1+ (1,0) [0|0] "" Vector__XXX
 SG_ VCRIGHT_loadShedStsRearDefroster : 9|1@1+ (1,0) [0|0] "" Vector__XXX
 SG_ VCRIGHT_loadShedStsSeatBackrest : 10|1@1+ (1,0) [0|0] "" Vector__XXX
 SG_ VCRIGHT_loadShedStsSeatHeaters : 11|1@1+ (1,0) [0|0] "" Vector__XXX
 SG_ VCRIGHT_loadShedStsSeatLift : 12|1@1+ (1,0) [0|0] "" Vector__XXX
 SG_ VCRIGHT_loadShedStsSeatTilt : 13|1@1+ (1,0) [0|0] "" Vector__XXX
 SG_ VCRIGHT_loadShedStsSeatTrack : 14|1@1+ (1,0) [0|0] "" Vector__XXX
 SG_ VCRIGHT_loadShedStsUSBPorts : 15|1@1+ (1,0) [0|0] "" Vector__XXX
 SG_ VCRIGHT_loadShedStsWindowMotorsFront : 16|1@1+ (1,0) [0|0] "" Vector__XXX
 SG_ VCRIGHT_loadShedStsWindowMotorsRear : 17|1@1+ (1,0) [0|0] "" Vector__XXX
 SG_ VCRIGHT_loadShedPremAudio : 50|1@1+ (1,0) [0|0] "" Vector__XXX
 SG_ VCRIGHT_hardwareLoadshedTriggered : 51|1@1+ (1,0) [0|0] "" Vector__XXX
 SG_ VCRIGHT_systemStatusCounter : 52|4@1+ (1,0) [0|0] "" Vector__XXX
 SG_ VCRIGHT_systemStatusChecksum : 56|8@1+ (1,0) [0|0] "" Vector__XXX

BO_ 1364 PMR_mfgData: 8 Vector__XXX
 SG_ PMR_processorDieIdLot : 0|24@1+ (1,0) [0|0] "" Vector__XXX
 SG_ PMR_processorDieIdWafer : 24|8@1+ (1,0) [0|0] "" Vector__XXX
 SG_ PMR_processorDieIdX : 32|12@1+ (1,0) [0|0] "" Vector__XXX
 SG_ PMR_processorDieIdY : 44|12@1+ (1,0) [0|0] "" Vector__XXX

BO_ 1365 TAS_estimatorData: 8 Vector__XXX
 SG_ TAS_estimatorDataIndex M : 0|4@1+ (1,0) [0|0] "" Vector__XXX
 SG_ TAS_Ay_fromSteer m0 : 8|8@1- (0.1,0) [0|0] "" Vector__XXX
 SG_ TAS_bodyCornerAz_FL m6 : 8|8@1- (0.4,0) [0|0] "" Vector__XXX
 SG_ TAS_bodyCornerVz_FL m5 : 8|8@1- (0.02,0) [0|0] "" Vector__XXX
 SG_ TAS_damperForceActual_FL m13 : 8|8@1- (128,0) [0|0] "" Vector__XXX
 SG_ TAS_heightDynamicCorrected_FL m2 : 8|8@1- (0.002,0) [0|0] "" Vector__XXX
 SG_ TAS_heightSteadyCorrected_FL m9 : 8|8@1- (0.002,0) [0|0] "" Vector__XXX
 SG_ TAS_offsets_FL m1 : 8|8@1- (0.002,0) [0|0] "" Vector__XXX
 SG_ TAS_rollBarFRoadHP_FL m12 : 8|6@1- (128,0) [0|0] "" Vector__XXX
 SG_ TAS_rollBarForce_FL m11 : 8|6@1- (128,0) [0|0] "" Vector__XXX
 SG_ TAS_rollVelocity m7 : 8|8@1- (0.01,0) [0|0] "" Vector__XXX
 SG_ TAS_springActualHeaveOnly_FL m10 : 8|8@1- (128,0) [0|0] "" Vector__XXX
 SG_ TAS_springDamperFRoadHP_FL m8 : 8|8@1- (256,0) [0|0] "" Vector__XXX
 SG_ TAS_springDamperForce_FL m3 : 8|8@1- (256,0) [0|0] "" Vector__XXX
 SG_ TAS_springDynamicHeaveOnly_FL m4 : 8|8@1- (256,0) [0|0] "" Vector__XXX
 SG_ TAS_Jy_fromSteer m0 : 16|8@1- (1,0) [0|0] "" Vector__XXX
 SG_ TAS_bodyCornerAz_FR m6 : 16|8@1- (0.4,0) [0|0] "" Vector__XXX
 SG_ TAS_bodyCornerVz_FR m5 : 16|8@1- (0.02,0) [0|0] "" Vector__XXX
 SG_ TAS_damperForceActual_FR m13 : 16|8@1- (128,0) [0|0] "" Vector__XXX
 SG_ TAS_heightDynamicCorrected_FR m2 : 16|8@1- (0.002,0) [0|0] "" Vector__XXX
 SG_ TAS_heightSteadyCorrected_FR m9 : 16|8@1- (0.002,0) [0|0] "" Vector__XXX
 SG_ TAS_offsets_FR m1 : 16|8@1- (0.004,0) [0|0] "" Vector__XXX
 SG_ TAS_pitchVelocity m7 : 16|8@1- (0.01,0) [0|0] "" Vector__XXX
 SG_ TAS_rollBarFRoadHP_FR m12 : 16|6@1- (128,0) [0|0] "" Vector__XXX
 SG_ TAS_rollBarForce_FR m11 : 16|6@1- (128,0) [0|0] "" Vector__XXX
 SG_ TAS_springActualHeaveOnly_FR m10 : 16|8@1- (128,0) [0|0] "" Vector__XXX
 SG_ TAS_springDamperFRoadHP_FR m8 : 16|8@1- (256,0) [0|0] "" Vector__XXX
 SG_ TAS_springDamperForce_FR m3 : 16|8@1- (256,0) [0|0] "" Vector__XXX
 SG_ TAS_springDynamicHeaveOnly_FR m4 : 16|8@1- (256,0) [0|0] "" Vector__XXX
 SG_ TAS_bodyCornerAz_RL m6 : 24|8@1- (0.4,0) [0|0] "" Vector__XXX
 SG_ TAS_bodyCornerVz_RL m5 : 24|8@1- (0.02,0) [0|0] "" Vector__XXX
 SG_ TAS_cos_gradeAngle m0 : 24|8@1+ (0.005,0) [0|0] "" Vector__XXX
 SG_ TAS_damperForceActual_RL m13 : 24|8@1- (128,0) [0|0] "" Vector__XXX
 SG_ TAS_heaveVelocity m7 : 24|8@1- (0.02,0) [0|0] "" Vector__XXX
 SG_ TAS_heightDynamicCorrected_RL m2 : 24|8@1- (0.002,0) [0|0] "" Vector__XXX
 SG_ TAS_heightSteadyCorrected_RL m9 : 24|8@1- (0.002,0) [0|0] "" Vector__XXX
 SG_ TAS_offsets_RL m1 : 24|8@1- (0.004,0) [0|0] "" Vector__XXX
 SG_ TAS_rollBarFRoadHP_RL m12 : 24|6@1- (128,0) [0|0] "" Vector__XXX
 SG_ TAS_rollBarForce_RL m11 : 24|6@1- (128,0) [0|0] "" Vector__XXX
 SG_ TAS_springActualHeaveOnly_RL m10 : 24|8@1- (128,0) [0|0] "" Vector__XXX
 SG_ TAS_springDamperFRoadHP_RL m8 : 24|8@1- (256,0) [0|0] "" Vector__XXX
 SG_ TAS_springDamperForce_RL m3 : 24|8@1- (256,0) [0|0] "" Vector__XXX
 SG_ TAS_springDynamicHeaveOnly_RL m4 : 24|8@1- (256,0) [0|0] "" Vector__XXX
 SG_ TAS_bodyCornerAz_RR m6 : 32|8@1- (0.4,0) [0|0] "" Vector__XXX
 SG_ TAS_bodyCornerVz_RR m5 : 32|8@1- (0.02,0) [0|0] "" Vector__XXX
 SG_ TAS_cos_bankAngle m0 : 32|8@1+ (0.005,0) [0|0] "" Vector__XXX
 SG_ TAS_damperForceActual_RR m13 : 32|8@1- (128,0) [0|0] "" Vector__XXX
 SG_ TAS_heightDynamicCorrected_RR m2 : 32|8@1- (0.002,0) [0|0] "" Vector__XXX
 SG_ TAS_heightSteadyCorrected_RR m9 : 32|8@1- (0.002,0) [0|0] "" Vector__XXX
 SG_ TAS_offsets_RR m1 : 32|8@1- (0.004,0) [0|0] "" Vector__XXX
 SG_ TAS_rollBarFRoadHP_RR m12 : 32|6@1- (128,0) [0|0] "" Vector__XXX
 SG_ TAS_rollBarForce_RR m11 : 32|6@1- (128,0) [0|0] "" Vector__XXX
 SG_ TAS_springActualHeaveOnly_RR m10 : 32|8@1- (128,0) [0|0] "" Vector__XXX
 SG_ TAS_springDamperFRoadHP_RR m8 : 32|8@1- (256,0) [0|0] "" Vector__XXX
 SG_ TAS_springDamperForce_RR m3 : 32|8@1- (256,0) [0|0] "" Vector__XXX
 SG_ TAS_springDynamicHeaveOnly_RR m4 : 32|8@1- (256,0) [0|0] "" Vector__XXX
 SG_ TAS_steadyStateOffsets_FL m7 : 32|8@1- (0.004,0) [0|0] "" Vector__XXX
 SG_ TAS_harshnessMetric m0 : 40|4@1+ (0.04,0) [0|0] "" Vector__XXX
 SG_ TAS_steadyStateOffsets_FR m7 : 40|8@1- (0.004,0) [0|0] "" Vector__XXX
 SG_ TAS_steadyStateOffsets_RL m7 : 48|8@1- (0.004,0) [0|0] "" Vector__XXX
 SG_ TAS_steadyStateOffsets_RR m7 : 56|8@1- (0.004,0) [0|0] "" Vector__XXX

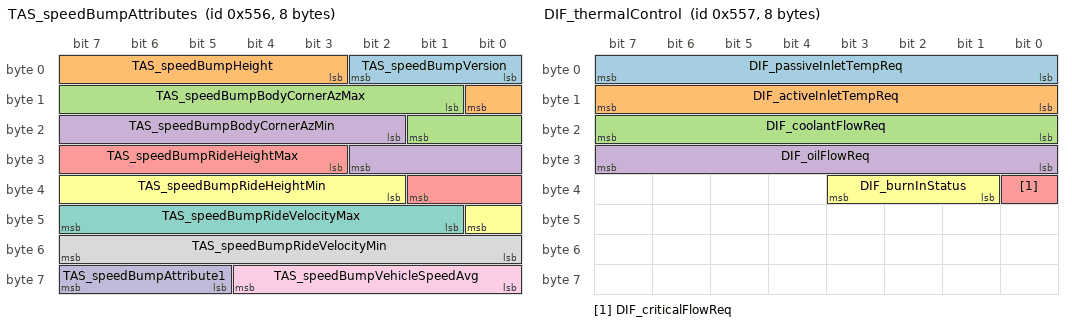
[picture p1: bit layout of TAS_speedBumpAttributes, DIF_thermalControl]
BO_ 1366 TAS_speedBumpAttributes: 8 Vector__XXX
 SG_ TAS_speedBumpVersion : 0|3@1+ (1,0) [0|0] "" Vector__XXX
 SG_ TAS_speedBumpHeight : 3|6@1+ (0.005,0) [0|0] "" Vector__XXX
 SG_ TAS_speedBumpBodyCornerAzMax : 9|9@1+ (0.1,0) [0|0] "" Vector__XXX
 SG_ TAS_speedBumpBodyCornerAzMin : 18|9@1+ (0.1,-51.1) [0|0] "" Vector__XXX
 SG_ TAS_speedBumpRideHeightMax : 27|7@1+ (0.002,0) [0|0] "" Vector__XXX
 SG_ TAS_speedBumpRideHeightMin : 34|7@1+ (0.002,-0.252) [0|0] "" Vector__XXX
 SG_ TAS_speedBumpRideVelocityMax : 41|7@1+ (0.02,0) [0|0] "" Vector__XXX
 SG_ TAS_speedBumpRideVelocityMin : 48|8@1+ (0.02,-2.54) [0|0] "" Vector__XXX
 SG_ TAS_speedBumpVehicleSpeedAvg : 56|5@1+ (2,0) [0|0] "" Vector__XXX
 SG_ TAS_speedBumpAttribute1 : 61|3@1- (1,0) [0|0] "" Vector__XXX

BO_ 1367 DIF_thermalControl: 8 Vector__XXX
 SG_ DIF_passiveInletTempReq : 0|8@1+ (1,-40) [0|0] "" Vector__XXX
 SG_ DIF_activeInletTempReq : 8|8@1+ (1,-40) [0|0] "" Vector__XXX
 SG_ DIF_coolantFlowReq : 16|8@1+ (0.2,0) [0|0] "" Vector__XXX
 SG_ DIF_oilFlowReq : 24|8@1+ (0.1,0) [0|0] "" Vector__XXX
 SG_ DIF_criticalFlowReq : 32|1@1+ (1,0) [0|0] "" Vector__XXX
 SG_ DIF_burnInStatus : 33|3@1+ (1,0) [0|0] "" Vector__XXX

BO_ 1369 GTW_mismatchFaultReserved: 8 Vector__XXX
 SG_ GTW_reservedSignal : 0|8@1+ (1,0) [0|0] "" Vector__XXX

BO_ 1370 GTW_mismatchFault: 8 Vector__XXX
 SG_ GTW_mismatchFaultIndex M : 0|3@1+ (1,0) [0|0] "" Vector__XXX
 SG_ GTW_mismatchFaultChecksum : 3|8@1+ (1,0) [0|0] "" Vector__XXX
 SG_ GTW_mismatchFaultCounter : 11|4@1+ (1,0) [0|0] "" Vector__XXX
 SG_ GTW_DISPOSDmismatchFault m2 : 15|1@1+ (1,0) [0|0] "" Vector__XXX
 SG_ GTW_GTWmismatchFault m1 : 15|1@1+ (1,0) [0|0] "" Vector__XXX
 SG_ GTW_BMSmismatchFault m1 : 16|1@1+ (1,0) [0|0] "" Vector__XXX
 SG_ GTW_DISPmismatchFault m2 : 16|1@1+ (1,0) [0|0] "" Vector__XXX
 SG_ GTW_APSmismatchFault m1 : 17|1@1+ (1,0) [0|0] "" Vector__XXX
 SG_ GTW_DISPTOUCHmismatchFault m2 : 17|1@1+ (1,0) [0|0] "" Vector__XXX
 SG_ GTW_BLEEPCENTERmismatchFault m1 : 18|1@1+ (1,0) [0|0] "" Vector__XXX
 SG_ GTW_BLEEPLEFTmismatchFault m1 : 19|1@1+ (1,0) [0|0] "" Vector__XXX
 SG_ GTW_LUMBAR32LmismatchFault m5 : 19|1@1+ (1,0) [0|0] "" Vector__XXX
 SG_ GTW_BLEEPREARmismatchFault m1 : 20|1@1+ (1,0) [0|0] "" Vector__XXX
 SG_ GTW_LUMBAR32RmismatchFault m5 : 20|1@1+ (1,0) [0|0] "" Vector__XXX
 SG_ GTW_BLEEPRIGHTmismatchFault m1 : 21|1@1+ (1,0) [0|0] "" Vector__XXX
 SG_ GTW_CBCmismatchFault m1 : 22|1@1+ (1,0) [0|0] "" Vector__XXX
 SG_ GTW_CMPmismatchFault m1 : 23|1@1+ (1,0) [0|0] "" Vector__XXX
 SG_ GTW_CPmismatchFault m1 : 24|1@1+ (1,0) [0|0] "" Vector__XXX
 SG_ GTW_DIFmismatchFault m1 : 25|1@1+ (1,0) [0|0] "" Vector__XXX
 SG_ GTW_DIRmismatchFault m1 : 26|1@1+ (1,0) [0|0] "" Vector__XXX
 SG_ GTW_CMPDmismatchFault m2 : 27|1@1+ (1,0) [0|0] "" Vector__XXX
 SG_ GTW_EPAS3PmismatchFault m1 : 27|1@1+ (1,0) [0|0] "" Vector__XXX
 SG_ GTW_CMPSmismatchFault m2 : 28|1@1+ (1,0) [0|0] "" Vector__XXX
 SG_ GTW_EPAS3SmismatchFault m1 : 28|1@1+ (1,0) [0|0] "" Vector__XXX
 SG_ GTW_EPBLmismatchFault m1 : 29|1@1+ (1,0) [0|0] "" Vector__XXX
 SG_ GTW_EPBRmismatchFault m1 : 30|1@1+ (1,0) [0|0] "" Vector__XXX
 SG_ GTW_ESPCALmismatchFault m1 : 31|1@1+ (1,0) [0|0] "" Vector__XXX
 SG_ GTW_ESPmismatchFault m1 : 32|1@1+ (1,0) [0|0] "" Vector__XXX
 SG_ GTW_HCM3LmismatchFault m1 : 33|1@1+ (1,0) [0|0] "" Vector__XXX
 SG_ GTW_HCM3RmismatchFault m1 : 34|1@1+ (1,0) [0|0] "" Vector__XXX
 SG_ GTW_HCMLmismatchFault m1 : 35|1@1+ (1,0) [0|0] "" Vector__XXX
 SG_ GTW_HCMRmismatchFault m1 : 36|1@1+ (1,0) [0|0] "" Vector__XXX
 SG_ GTW_VCBLDCPPmismatchFault m4 : 36|1@1+ (1,0) [0|0] "" Vector__XXX
 SG_ GTW_HVPmismatchFault m1 : 37|1@1+ (1,0) [0|0] "" Vector__XXX
 SG_ GTW_VCBLDCPBmismatchFault m4 : 37|1@1+ (1,0) [0|0] "" Vector__XXX
 SG_ GTW_IBSTCALmismatchFault m1 : 38|1@1+ (1,0) [0|0] "" Vector__XXX
 SG_ GTW_VCBLDCFmismatchFault m4 : 38|1@1+ (1,0) [0|0] "" Vector__XXX
 SG_ GTW_IBSTmismatchFault m1 : 39|1@1+ (1,0) [0|0] "" Vector__XXX
 SG_ GTW_LVBMSmismatchFault m1 : 40|1@1+ (1,0) [0|0] "" Vector__XXX
 SG_ GTW_OCS1PmismatchFault m1 : 41|1@1+ (1,0) [0|0] "" Vector__XXX
 SG_ GTW_RADCmismatchFault m2 : 41|1@1+ (1,0) [0|0] "" Vector__XXX
 SG_ GTW_OPCFmismatchFault m1 : 42|1@1+ (1,0) [0|0] "" Vector__XXX
 SG_ GTW_OPCRmismatchFault m1 : 43|1@1+ (1,0) [0|0] "" Vector__XXX
 SG_ GTW_PARKmismatchFault m1 : 44|1@1+ (1,0) [0|0] "" Vector__XXX
 SG_ GTW_PCSCPU2mismatchFault m1 : 45|1@1+ (1,0) [0|0] "" Vector__XXX
 SG_ GTW_PCSmismatchFault m1 : 46|1@1+ (1,0) [0|0] "" Vector__XXX
 SG_ GTW_PMFmismatchFault m1 : 47|1@1+ (1,0) [0|0] "" Vector__XXX
 SG_ GTW_TASmismatchFault m2 : 47|1@1+ (1,0) [0|0] "" Vector__XXX
 SG_ GTW_PMRmismatchFault m1 : 48|1@1+ (1,0) [0|0] "" Vector__XXX
 SG_ GTW_USMmismatchFault m2 : 48|1@1+ (1,0) [0|0] "" Vector__XXX
 SG_ GTW_PTCmismatchFault m1 : 49|1@1+ (1,0) [0|0] "" Vector__XXX
 SG_ GTW_RCMCALmismatchFault m1 : 50|1@1+ (1,0) [0|0] "" Vector__XXX
 SG_ GTW_RCMmismatchFault m1 : 51|1@1+ (1,0) [0|0] "" Vector__XXX
 SG_ GTW_SCCMmismatchFault m1 : 52|1@1+ (1,0) [0|0] "" Vector__XXX
 SG_ GTW_SDCRmismatchFault m1 : 53|1@1+ (1,0) [0|0] "" Vector__XXX
 SG_ GTW_SWCmismatchFault m1 : 54|1@1+ (1,0) [0|0] "" Vector__XXX
 SG_ GTW_THSmismatchFault m1 : 55|1@1+ (1,0) [0|0] "" Vector__XXX
 SG_ GTW_EPASTPmismatchFault m2 : 56|1@1+ (1,0) [0|0] "" Vector__XXX
 SG_ GTW_VCFRONTmismatchFault m1 : 56|1@1+ (1,0) [0|0] "" Vector__XXX
 SG_ GTW_EPASTSmismatchFault m2 : 57|1@1+ (1,0) [0|0] "" Vector__XXX
 SG_ GTW_ICRmismatchFault m4 : 57|1@1+ (1,0) [0|0] "" Vector__XXX
 SG_ GTW_VCLEFTmismatchFault m1 : 57|1@1+ (1,0) [0|0] "" Vector__XXX
 SG_ GTW_VCRIGHTmismatchFault m1 : 58|1@1+ (1,0) [0|0] "" Vector__XXX
 SG_ GTW_WIPERmismatchFault m4 : 58|1@1+ (1,0) [0|0] "" Vector__XXX
 SG_ GTW_VCSECmismatchFault m1 : 59|1@1+ (1,0) [0|0] "" Vector__XXX

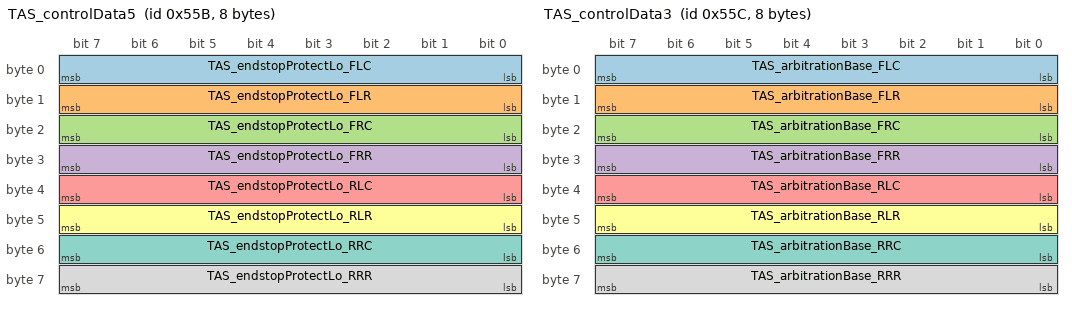
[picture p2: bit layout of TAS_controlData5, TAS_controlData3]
BO_ 1371 TAS_controlData5: 8 Vector__XXX
 SG_ TAS_endstopProtectLo_FLC : 0|8@1+ (0.01,0) [0|0] "" Vector__XXX
 SG_ TAS_endstopProtectLo_FLR : 8|8@1+ (0.01,0) [0|0] "" Vector__XXX
 SG_ TAS_endstopProtectLo_FRC : 16|8@1+ (0.01,0) [0|0] "" Vector__XXX
 SG_ TAS_endstopProtectLo_FRR : 24|8@1+ (0.01,0) [0|0] "" Vector__XXX
 SG_ TAS_endstopProtectLo_RLC : 32|8@1+ (0.01,0) [0|0] "" Vector__XXX
 SG_ TAS_endstopProtectLo_RLR : 40|8@1+ (0.01,0) [0|0] "" Vector__XXX
 SG_ TAS_endstopProtectLo_RRC : 48|8@1+ (0.01,0) [0|0] "" Vector__XXX
 SG_ TAS_endstopProtectLo_RRR : 56|8@1+ (0.01,0) [0|0] "" Vector__XXX

BO_ 1372 TAS_controlData3: 8 Vector__XXX
 SG_ TAS_arbitrationBase_FLC : 0|8@1+ (0.01,0) [0|0] "" Vector__XXX
 SG_ TAS_arbitrationBase_FLR : 8|8@1+ (0.01,0) [0|0] "" Vector__XXX
 SG_ TAS_arbitrationBase_FRC : 16|8@1+ (0.01,0) [0|0] "" Vector__XXX
 SG_ TAS_arbitrationBase_FRR : 24|8@1+ (0.01,0) [0|0] "" Vector__XXX
 SG_ TAS_arbitrationBase_RLC : 32|8@1+ (0.01,0) [0|0] "" Vector__XXX
 SG_ TAS_arbitrationBase_RLR : 40|8@1+ (0.01,0) [0|0] "" Vector__XXX
 SG_ TAS_arbitrationBase_RRC : 48|8@1+ (0.01,0) [0|0] "" Vector__XXX
 SG_ TAS_arbitrationBase_RRR : 56|8@1+ (0.01,0) [0|0] "" Vector__XXX

VAL_ 1359 SCCM_matrixIndex 0 "SCCM_AlertMatrix0" ;
VAL_ 1360 VCRIGHT_alertID 0 "ALERT_DO_NOT_USE_ZERO" 1 "a001_DriverDoorOpen" 2 "a002_DoorOpen" 3 "a003_TrunkOpen" 4 "a004_FrunkOpen" 5 "a005_HeadlightsOnDoorOpen" 6 "a006_RemoteServiceAlert" 7 "a007_SoftPackConfigMismatch" 8 "a008_TouchScreenError" 9 "a009_SquashfsError" 10 "a010_MapsMissing" 11 "a011_IncorrectMap" 12 "a012_NotOnPrivateProperty" 13 "a013_TPMSHardWarning" 14 "a014_TPMSSoftWarning" 15 "a015_TPMSOverPressureWarning" 16 "a016_TPMSTemperatureWarning" 17 "a017_TPMSSystemFault" 18 "a018_SlipStartOn" 19 "a019_ParkBrakeFault" 20 "a020_SteeringReduced" 21 "a021_RearSeatbeltUnbuckled" 22 "a022_ApeFusesEtc" 23 "a023_CellInternetCheckFailed" 24 "a024_WifiInternetCheckFailed" 25 "a025_WifiOnlineCheckFailed" 26 "a026_ModemResetLoopDetected" 27 "a027_AutoSteerMIA" 28 "a028_FrontTrunkPopupClosed" 29 "a029_ModemMIA" 30 "a030_ModemVMCrash" 31 "a031_BrakeFluidLow" 32 "a032_CellModemRecoveryResets" 33 "a033_ApTrialExpired" 34 "a034_WakeupProblem" 35 "a035_AudioWatchdogKernelError" 36 "a036_AudioWatchdogHfpError" 37 "a037_AudioWatchdogXrunStormError" 38 "a038_AudioWatchdogA2bI2cLockupError" 39 "a039_AudioA2bNeedRediscovery" 40 "a040_HomelinkTransmit" 41 "a041_AudioDmesgXrun" 42 "a042_AudioDmesgRtThrottling" 43 "a043_InvalidMapDataOverride" 44 "a044_AudioDmesgDspException" 45 "a045_ECallNeedsService" 46 "a046_BackupCameraStreamError" 47 "a047_CellRoamingDisallowed" 48 "a048_AudioPremiumAmpCheckFailed" 49 "a049_BrakeShiftRequired" 50 "a050_BackupCameraIPUTimeout" 51 "a051_BackupCameraFrameTimeout" 52 "a052_KernelPanicReported" 53 "a053_QtCarExitError" 54 "a054_AudioBoostPowerBad" 55 "a055_ManualECallDisabled" 56 "a056_ManualECallButtonDisconnected" 57 "a057_CellAntennaDisconnected" 58 "a058_GPSAntennaDisconnected" 59 "a059_ECallSpeakerDisconnected" 60 "a060_ECallMicDisconnected" 61 "a061_SIMTestFailed" 62 "a062_ENSTestFailed" 63 "a063_CellularTestFailed" 64 "a064_ModemFirmwareTestFailed" 65 "a065_WiFiRecoveryReset" 66 "a066_GpuHangDetected" 67 "a067_WarnOnI915" 68 "a068_VideoUnexpectedExit" 69 "a069_VideoUDPTimeout" 70 "a070_VideoPipelineWarning" 71 "a071_VideoPipelineError" 72 "a072_ECallAnalogMicFailed" 73 "a073_ECallDigitalMicFailed" 74 "a074_EMMCHangDetected" 75 "a075_BackupCameraInitError" 76 "a076_NumFalseManualECalls" 77 "a077_AudioA2bMicChannelSwap" 78 "a078_DashcamUsbDriveUnmountable" 79 "a079_DashcamUsbDriveFull" 80 "a080_DashcamUsbDriveSlow" 81 "a081_CellModemSearchExpired" 82 "a082_NumModemRebootStuckInECall" 83 "a083_ECallProxyWatchdogTriggered" 84 "a084_SerializerError" 85 "a085_DeserializerError" 86 "a086_TouchEnumerationError" 87 "a087_BmpReset" 88 "a088_CellRemovableSimMissing" 89 "a089_RadioSoftResetError" 90 "a090_RadioPingFailError" 91 "a091_VehicleLinkStall" 92 "a092_updateStarted" 93 "a093_updateEnded" 94 "a094_ModemPowerOnFailure" 95 "a095_CidStorageRunningLow" 96 "a096_VideodPipelineIssueDetected" 97 "a097_AudiodRestarted" 98 "a098_DiskCheckFailure" 99 "a099_eMMCStatusError" 100 "a100_eMMCFTLError" 101 "a101_wifiStackProblem" 102 "a102_A2bDiscoveryFailed" 103 "a103_UsbHubNotEnumerating" 104 "a104_DashcamUsbDriveMissing" 105 "a105_firmwareReinstallRequested" 106 "a106_rebootBackstopTriggered" 107 "a107_DashcamUsbDriveTooBigForVfatFsck" 108 "a108_DashcamUsbDriveGettingFull" 109 "a109_DashcamUsbDriveTooSmall" 110 "a110_DashcamUsbDriveCorrupt" 111 "a111_DashcamUsbDriveWrongPort" 112 "a112_badUSBDevice" 113 "a113_DashcamHasOnboardSentryClips" ;
VAL_ 1360 VCRIGHT_alertState 0 "CLEARED" 1 "SET" ;
VAL_ 1360 VCRIGHT_a031_uds_bytes_0 0 "0" 1 "1" 2 "2" 3 "3" 4 "4" 5 "5" 6 "6" 7 "7" 8 "8" 9 "9" 10 "10" 11 "11" 12 "12" 13 "13" 14 "14" 15 "15" 16 "16" 17 "17" 18 "18" 19 "19" 20 "20" 21 "21" 22 "22" 23 "23" 24 "24" 25 "25" 26 "26" 27 "27" 28 "28" 29 "29" 30 "30" 31 "31" ;
VAL_ 1360 VCRIGHT_a096_VEH_status 0 "DISABLED" 1 "ENABLED" 2 "TEMPORARY_FAILURE" 3 "SNA" ;
VAL_ 1360 VCRIGHT_a101_VEH_state 0 "STANDBY" 1 "DRIVE" 2 "SUPPORT" 3 "CHARGE" 4 "FEIM" 5 "CLEAR_FAULT" 6 "FAULT" 7 "WELD" 8 "TEST" 9 "SNA" 10 "DIAG" ;
VAL_ 1360 VCRIGHT_a109_PARTY_status 0 "DISABLED" 1 "ENABLED" 2 "TEMPORARY_FAILURE" 3 "SNA" ;
VAL_ 1360 VCRIGHT_a114_PARTY_status 0 "DISABLED" 1 "ENABLED" 2 "TEMPORARY_FAILURE" 3 "SNA" ;
VAL_ 1360 VCRIGHT_a122_VEH_status 0 "DISABLED" 1 "ENABLED" 2 "TEMPORARY_FAILURE" 3 "SNA" ;
VAL_ 1360 VCRIGHT_a185_summonFaultReason 0 "NONE" 1 "DI_MIA" 2 "DAS_MIA" 3 "ESP_MIA" 4 "EPBM_MIA" 5 "DI_FAULT" 6 "DI_APC_FAULT" 7 "DAS_FAULT" 8 "ESP_FAULT" 9 "VEH_CAN_FAULT" 10 "EAC_NOT_ALLOWED" 11 "EPBM_REQUEST" 12 "SPEED" 13 "EXTERNAL" 14 "PARK_MIA" 15 "PM_MIA" 16 "PM_REQUEST" 17 "OOC" 18 "MISMATCH" 19 "EPB_FAULT" 20 "DI_STATE_INVALID" 21 "PASSIVE_REQUEST" 22 "EPBREMOTE_MIA" 23 "REMOTE_SUMMON_FAULTED" 24 "LOCAL_UNIT_FAULTED" 25 "REMOTE_UNIT_FAULTED" 26 "START_IN_UNAVAILABLE" 27 "INVALID_REMOTE_STATE" 28 "REMOTE_DID_NOT_START" ;
VAL_ 1360 VCRIGHT_a360_vehicleSpeed 8191 "SNA" ;
VAL_ 1360 VCRIGHT_a496_cabinTempInterior 240 "SNA" ;
VAL_ 1360 VCRIGHT_a525_GTW_twelveVBatteryType 0 "ATLASBX_B24_FLOODED" 1 "CLARIOS_B24_FLOODED" ;
VAL_ 1360 VCRIGHT_a545_GTW_twelveVBatteryType 0 "ATLASBX_B24_FLOODED" 1 "CLARIOS_B24_FLOODED" ;
VAL_ 1360 VCRIGHT_a583_ambientTemp 4294966273 "SNA" ;
VAL_ 1360 VCRIGHT_a584_ambientTemp 4294966273 "SNA" ;
VAL_ 1360 VCRIGHT_a585_ambientTemp 4294966273 "SNA" ;
VAL_ 1360 VCRIGHT_a586_ambientTemp 4294966273 "SNA" ;
VAL_ 1360 VCRIGHT_a599_GTW_twelveVBatteryType 0 "ATLASBX_B24_FLOODED" 1 "CLARIOS_B24_FLOODED" ;
VAL_ 1360 VCRIGHT_a089_PARTY_status 0 "DISABLED" 1 "ENABLED" 2 "TEMPORARY_FAILURE" 3 "SNA" ;
VAL_ 1360 VCRIGHT_a090_VEH_state 0 "STANDBY" 1 "DRIVE" 2 "SUPPORT" 3 "CHARGE" 4 "FEIM" 5 "CLEAR_FAULT" 6 "FAULT" 7 "WELD" 8 "TEST" 9 "SNA" 10 "DIAG" ;
VAL_ 1360 VCRIGHT_a095_PT_status 0 "DISABLED" 1 "ENABLED" 2 "TEMPORARY_FAILURE" 3 "SNA" ;
VAL_ 1360 VCRIGHT_a096_CH_status 0 "DISABLED" 1 "ENABLED" 2 "TEMPORARY_FAILURE" 3 "SNA" ;
VAL_ 1360 VCRIGHT_a097_VEH_state 0 "STANDBY" 1 "DRIVE" 2 "SUPPORT" 3 "CHARGE" 4 "FEIM" 5 "CLEAR_FAULT" 6 "FAULT" 7 "WELD" 8 "TEST" 9 "SNA" 10 "DIAG" ;
VAL_ 1360 VCRIGHT_a111_VEH_status 0 "DISABLED" 1 "ENABLED" 2 "TEMPORARY_FAILURE" 3 "SNA" ;
VAL_ 1360 VCRIGHT_a112_VEH_status 0 "DISABLED" 1 "ENABLED" 2 "TEMPORARY_FAILURE" 3 "SNA" ;
VAL_ 1360 VCRIGHT_a120_VEH_systemStatus 0 "UNKNOWN" 1 "RELEASED" 2 "PARKED" 3 "DYNAMIC" 4 "PARKING" 5 "RELEASING" 6 "FAULT" 7 "FAULT_SECURE" 8 "MISMATCH" ;
VAL_ 1360 VCRIGHT_a086_VEH_status 0 "DISABLED" 1 "ENABLED" 2 "TEMPORARY_FAILURE" 3 "SNA" ;
VAL_ 1360 VCRIGHT_a089_VEH_status 0 "DISABLED" 1 "ENABLED" 2 "TEMPORARY_FAILURE" 3 "SNA" ;
VAL_ 1360 VCRIGHT_a091_VEH_state 0 "STANDBY" 1 "DRIVE" 2 "SUPPORT" 3 "CHARGE" 4 "FEIM" 5 "CLEAR_FAULT" 6 "FAULT" 7 "WELD" 8 "TEST" 9 "SNA" 10 "DIAG" ;
VAL_ 1360 VCRIGHT_a098_VEH_status 0 "DISABLED" 1 "ENABLED" 2 "TEMPORARY_FAILURE" 3 "SNA" ;
VAL_ 1360 VCRIGHT_a103_VEH_status 0 "DISABLED" 1 "ENABLED" 2 "TEMPORARY_FAILURE" 3 "SNA" ;
VAL_ 1360 VCRIGHT_a107_VEH_status 0 "DISABLED" 1 "ENABLED" 2 "TEMPORARY_FAILURE" 3 "SNA" ;
VAL_ 1360 VCRIGHT_a087_VEH_status 0 "DISABLED" 1 "ENABLED" 2 "TEMPORARY_FAILURE" 3 "SNA" ;
VAL_ 1360 VCRIGHT_a088_VEH_status 0 "DISABLED" 1 "ENABLED" 2 "TEMPORARY_FAILURE" 3 "SNA" ;
VAL_ 1360 VCRIGHT_a118_VEH_status 0 "DISABLED" 1 "ENABLED" 2 "TEMPORARY_FAILURE" 3 "SNA" ;
VAL_ 1360 VCRIGHT_a120_PARTY_systemStatus 0 "UNKNOWN" 1 "RELEASED" 2 "PARKED" 3 "DYNAMIC" 4 "PARKING" 5 "RELEASING" 6 "FAULT" 7 "FAULT_SECURE" 8 "MISMATCH" ;
VAL_ 1360 VCRIGHT_a276_mirrorState 0 "IDLE" 1 "TILT_X" 2 "TILT_Y" 3 "FOLD_UNFOLD" 4 "RECALL" ;
VAL_ 1360 VCRIGHT_a450_tempDuctLeft 255 "SNA" ;
VAL_ 1360 VCRIGHT_a089_BDY_status 0 "DISABLED" 1 "ENABLED" 2 "TEMPORARY_FAILURE" 3 "SNA" ;
VAL_ 1360 VCRIGHT_a103_PT_status 0 "DISABLED" 1 "ENABLED" 2 "TEMPORARY_FAILURE" 3 "SNA" ;
VAL_ 1360 VCRIGHT_a108_VEH_status 0 "DISABLED" 1 "ENABLED" 2 "TEMPORARY_FAILURE" 3 "SNA" ;
VAL_ 1360 VCRIGHT_a109_VEH_status 0 "DISABLED" 1 "ENABLED" 2 "TEMPORARY_FAILURE" 3 "SNA" ;
VAL_ 1360 VCRIGHT_a087_PARTY_status 0 "DISABLED" 1 "ENABLED" 2 "TEMPORARY_FAILURE" 3 "SNA" ;
VAL_ 1360 VCRIGHT_a088_PARTY_status 0 "DISABLED" 1 "ENABLED" 2 "TEMPORARY_FAILURE" 3 "SNA" ;
VAL_ 1360 VCRIGHT_a089_CH_status 0 "DISABLED" 1 "ENABLED" 2 "TEMPORARY_FAILURE" 3 "SNA" ;
VAL_ 1360 VCRIGHT_a086_VEH_systemStatus 0 "UNKNOWN" 1 "RELEASED" 2 "PARKED" 3 "DYNAMIC" 4 "PARKING" 5 "RELEASING" 6 "FAULT" 7 "FAULT_SECURE" 8 "MISMATCH" ;
VAL_ 1360 VCRIGHT_a098_PARTY_status 0 "DISABLED" 1 "ENABLED" 2 "TEMPORARY_FAILURE" 3 "SNA" ;
VAL_ 1360 VCRIGHT_a108_PARTY_status 0 "DISABLED" 1 "ENABLED" 2 "TEMPORARY_FAILURE" 3 "SNA" ;
VAL_ 1360 VCRIGHT_a114_VEH_status 0 "DISABLED" 1 "ENABLED" 2 "TEMPORARY_FAILURE" 3 "SNA" ;
VAL_ 1360 VCRIGHT_a545_serviceMode 0 "DISABLED" 1 "ENABLED" ;
VAL_ 1360 VCRIGHT_a107_PT_status 0 "DISABLED" 1 "ENABLED" 2 "TEMPORARY_FAILURE" 3 "SNA" ;
VAL_ 1360 VCRIGHT_a112_PARTY_status 0 "DISABLED" 1 "ENABLED" 2 "TEMPORARY_FAILURE" 3 "SNA" ;
VAL_ 1360 VCRIGHT_a118_VEH_systemStatus 0 "UNKNOWN" 1 "RELEASED" 2 "PARKED" 3 "DYNAMIC" 4 "PARKING" 5 "RELEASING" 6 "FAULT" 7 "FAULT_SECURE" 8 "MISMATCH" ;
VAL_ 1360 VCRIGHT_a120_PARTY_status 0 "DISABLED" 1 "ENABLED" 2 "TEMPORARY_FAILURE" 3 "SNA" ;
VAL_ 1360 VCRIGHT_a109_BDY_status 0 "DISABLED" 1 "ENABLED" 2 "TEMPORARY_FAILURE" 3 "SNA" ;
VAL_ 1360 VCRIGHT_a110_CH_airbagCutoffStatus 0 "RCM_PASSENGER_AIRBAG_ENABLED" 1 "RCM_PASSENGER_AIRBAG_DISABLED" 3 "SNA" ;
VAL_ 1360 VCRIGHT_a111_PARTY_status 0 "DISABLED" 1 "ENABLED" 2 "TEMPORARY_FAILURE" 3 "SNA" ;
VAL_ 1360 VCRIGHT_a112_CH_status 0 "DISABLED" 1 "ENABLED" 2 "TEMPORARY_FAILURE" 3 "SNA" ;
VAL_ 1360 VCRIGHT_a104_CH_status 0 "DISABLED" 1 "ENABLED" 2 "TEMPORARY_FAILURE" 3 "SNA" ;
VAL_ 1360 VCRIGHT_a111_CH_status 0 "DISABLED" 1 "ENABLED" 2 "TEMPORARY_FAILURE" 3 "SNA" ;
VAL_ 1360 VCRIGHT_a120_PT_systemStatus 0 "UNKNOWN" 1 "RELEASED" 2 "PARKED" 3 "DYNAMIC" 4 "PARKING" 5 "RELEASING" 6 "FAULT" 7 "FAULT_SECURE" 8 "MISMATCH" ;
VAL_ 1360 VCRIGHT_a450_tempDuctRight 255 "SNA" ;
VAL_ 1360 VCRIGHT_a525_serviceMode 0 "DISABLED" 1 "ENABLED" ;
VAL_ 1360 VCRIGHT_a599_serviceMode 0 "DISABLED" 1 "ENABLED" ;
VAL_ 1360 VCRIGHT_a104_PARTY_status 0 "DISABLED" 1 "ENABLED" 2 "TEMPORARY_FAILURE" 3 "SNA" ;
VAL_ 1360 VCRIGHT_a114_BDY_status 0 "DISABLED" 1 "ENABLED" 2 "TEMPORARY_FAILURE" 3 "SNA" ;
VAL_ 1360 VCRIGHT_a116_VEH_status 0 "DISABLED" 1 "ENABLED" 2 "TEMPORARY_FAILURE" 3 "SNA" ;
VAL_ 1360 VCRIGHT_a109_CH_status 0 "DISABLED" 1 "ENABLED" 2 "TEMPORARY_FAILURE" 3 "SNA" ;
VAL_ 1360 VCRIGHT_a284_cabinTempInterior 240 "SNA" ;
VAL_ 1360 VCRIGHT_a285_cabinTempInterior 240 "SNA" ;
VAL_ 1360 VCRIGHT_a113_VEH_status 0 "DISABLED" 1 "ENABLED" 2 "TEMPORARY_FAILURE" 3 "SNA" ;
VAL_ 1360 VCRIGHT_a114_CH_status 0 "DISABLED" 1 "ENABLED" 2 "TEMPORARY_FAILURE" 3 "SNA" ;
VAL_ 1360 VCRIGHT_a104_VEH_status 0 "DISABLED" 1 "ENABLED" 2 "TEMPORARY_FAILURE" 3 "SNA" ;
VAL_ 1360 VCRIGHT_a117_VEH_status 0 "DISABLED" 1 "ENABLED" 2 "TEMPORARY_FAILURE" 3 "SNA" ;
VAL_ 1360 VCRIGHT_a104_BDY_status 0 "DISABLED" 1 "ENABLED" 2 "TEMPORARY_FAILURE" 3 "SNA" ;
VAL_ 1360 VCRIGHT_a180_latchStatus 0 "SNA" 1 "OPENED" 2 "CLOSED" 3 "CLOSING" 4 "OPENING" 5 "AJAR" 6 "TIMEOUT" 7 "DEFAULT" 8 "FAULT" ;
VAL_ 1360 VCRIGHT_a181_latchStatus 0 "SNA" 1 "OPENED" 2 "CLOSED" 3 "CLOSING" 4 "OPENING" 5 "AJAR" 6 "TIMEOUT" 7 "DEFAULT" 8 "FAULT" ;
VAL_ 1360 VCRIGHT_a236_lumbarAState 0 "STOPPED" 1 "MOVING_UP" 2 "MOVING_DOWN" 3 "RECALLING" 4 "CALIBRATING" 5 "UNDEFINED" ;
VAL_ 1360 VCRIGHT_a237_lumbarAState 0 "STOPPED" 1 "MOVING_UP" 2 "MOVING_DOWN" 3 "RECALLING" 4 "CALIBRATING" 5 "UNDEFINED" ;
VAL_ 1360 VCRIGHT_a238_lumbarAState 0 "STOPPED" 1 "MOVING_UP" 2 "MOVING_DOWN" 3 "RECALLING" 4 "CALIBRATING" 5 "UNDEFINED" ;
VAL_ 1360 VCRIGHT_a450_hvacAirFlowModeRow1 0 "NONE" 1 "FLOOR" 2 "PANEL" 3 "PANEL_FLOOR" 4 "DEFROST" 5 "DEFROST_FLOOR" 6 "DEFROST_PANEL" 7 "DEFROST_PANEL_FLOOR" ;
VAL_ 1360 VCRIGHT_a236_lumbarBState 0 "STOPPED" 1 "MOVING_UP" 2 "MOVING_DOWN" 3 "RECALLING" 4 "CALIBRATING" 5 "UNDEFINED" ;
VAL_ 1360 VCRIGHT_a237_lumbarBState 0 "STOPPED" 1 "MOVING_UP" 2 "MOVING_DOWN" 3 "RECALLING" 4 "CALIBRATING" 5 "UNDEFINED" ;
VAL_ 1360 VCRIGHT_a238_lumbarBState 0 "STOPPED" 1 "MOVING_UP" 2 "MOVING_DOWN" 3 "RECALLING" 4 "CALIBRATING" 5 "UNDEFINED" ;
VAL_ 1362 VCLEFT_loadShedReason 0 "NONE" 1 "DCDC_EFUSE_PROTECTION" 2 "LVBRIDGE_EFUSE_PROTECTION" 4 "DCDC_SATURATION" 8 "POST_CRASH" 16 "HV_FAULT" ;
VAL_ 1363 VCRIGHT_loadShedReason 0 "NONE" 1 "DCDC_EFUSE_PROTECTION" 2 "LVBRIDGE_EFUSE_PROTECTION" 4 "DCDC_SATURATION" 8 "POST_CRASH" 16 "HV_FAULT" ;
VAL_ 1370 GTW_mismatchFaultIndex 1 "Mux1" 2 "Mux2" ;
